AUTOSAR XML (schema 4-0-3)
package /AUTOSAR_Dem/CompuMethods
  compu method Dem_EventStatusExtendedType: 1=DEM_UDS_STATUS_TF, 2=DEM_UDS_STATUS_TFTOC, 4=DEM_UDS_STATUS_PDTC, 8=DEM_UDS_STATUS_CDTC, 16=DEM_UDS_STATUS_TNCSLC, 32=DEM_UDS_STATUS_TFSLC, 64=DEM_UDS_STATUS_TNCTOC, 128=DEM_UDS_STATUS_WIR
package /AUTOSAR_Dem/ImplementationDataTypes
  30 x impl type:
    Dem_ReturnDisableDTCRecordUpdateType: category=VALUE, base-type=uint8, compu {0x00=DEM_DISABLE_DTCRECUP_OK, 0x01=DEM_DISABLE_DTCRECUP_WRONG_DTC, 0x02=DEM_DISABLE_DTCRECUP_WRONG_DTCORIGIN, 0x03=DEM_DISABLE_DTCRECUP_PENDING}, range raw 0x00..0x03
    Dem_ReturnGetFreezeFrameDataByDTCType: category=VALUE, base-type=uint8, compu {0x00=DEM_GET_FFDATABYDTC_OK, 0x01=DEM_GET_FFDATABYDTC_WRONG_DTC, 0x02=DEM_GET_FFDATABYDTC_WRONG_DTCORIGIN, 0x03=DEM_GET_FFDATABYDTC_WRONG_RECORDNUMBER, 0x04=DEM_GET_FFDATABYDTC_WRONG_BUFFERSIZE, 0x05=DEM_GET_FFDATABYDTC_PENDING}, range raw 0x00..0x05
    Dem_ReturnGetSizeOfExtendedDataRecordByDTCType: category=VALUE, base-type=uint8, compu {0x00=DEM_GET_SIZEOFEDRBYDTC_OK, 0x01=DEM_GET_SIZEOFEDRBYDTC_W_DTC, 0x02=DEM_GET_SIZEOFEDRBYDTC_W_DTCOR, 0x03=DEM_GET_SIZEOFEDRBYDTC_W_RNUM, 0x04=DEM_GET_SIZEOFEDRBYDTC_PENDING}, range raw 0x00..0x04
    Dem_ReturnGetSeverityOfDTCType: category=VALUE, base-type=uint8, compu {0x00=DEM_GET_SEVERITYOFDTC_OK, 0x01=DEM_GET_SEVERITYOFDTC_WRONG_DTC, 0x02=DEM_GET_SEVERITYOFDTC_NOSEVERITY, 0x03=DEM_GET_SEVERITYOFDTC_PENDING}, range raw 0x00..0x03
    Dem_DTCFormatType: category=VALUE, base-type=uint8, compu {0=DEM_DTC_FORMAT_OBD, 1=DEM_DTC_FORMAT_UDS, 2=DEM_DTC_FORMAT_J1939}, range raw 0..2
    Dem_DTCKindType: category=VALUE, base-type=uint8, compu {0x01=DEM_DTC_KIND_ALL_DTCS, 0x02=DEM_DTC_KIND_EMISSION_REL_DTCS}, range raw 0x01..0x02
    Dem_DTCOriginType: category=VALUE, base-type=uint8, compu {0x01=DEM_DTC_ORIGIN_PRIMARY_MEMORY, 0x02=DEM_DTC_ORIGIN_MIRROR_MEMORY, 0x03=DEM_DTC_ORIGIN_PERMANENT_MEMORY, 0x04=DEM_DTC_ORIGIN_SECONDARY_MEMORY}, range raw 0x01..0x04
    Dem_DTCRequestType: category=VALUE, base-type=uint8, compu {0x01=DEM_FIRST_FAILED_DTC, 0x02=DEM_MOST_RECENT_FAILED_DTC, 0x03=DEM_FIRST_DET_CONFIRMED_DTC, 0x04=DEM_MOST_REC_DET_CONFIRMED_DTC, 0x04=DEM_NUM_OF_DTC_REQEST_TYPE}, range raw 0x01..0x04
    Dem_ReturnGetNumberOfFilteredDTCType: category=VALUE, base-type=uint8, compu {0x00=DEM_NUMBER_OK, 0x01=DEM_NUMBER_FAILED, 0x02=DEM_NUMBER_PENDING}, range raw 0x00..0x02
    Dem_DTCSeverityType: category=VALUE, base-type=uint8, compu {0=DEM_SEVERITY_NO_SEVERITY, 32=DEM_SEVERITY_MAINTENANCE_ONLY, 64=DEM_SEVERITY_CHECK_AT_NEXT_HALT, 128=DEM_SEVERITY_CHECK_IMMEDIATELY}, range raw 0x00..0xE0
    Dem_DTCTranslationFormatType: category=VALUE, base-type=uint8, compu {0x00=DEM_DTC_TRANSLATION_ISO15031_6, 0x01=DEM_DTC_TRANSLATION_ISO14229_1, 0x02=DEM_DTC_TRANSLATION_SAEJ1939_73, 0x03=DEM_DTC_TRANSLATION_ISO11992_4, 0x04=DEM_DTC_TRANSLATION_J2012DA_FORMAT_04}, range raw 0x00..0x04
    Dem_EventStatusType: category=VALUE, base-type=uint8, compu {0x00=DEM_EVENT_STATUS_PASSED, 0x01=DEM_EVENT_STATUS_FAILED, 0x02=DEM_EVENT_STATUS_PREPASSED, 0x03=DEM_EVENT_STATUS_PREFAILED}, range raw 0x00..0x03
    Dem_IndicatorStatusType: category=VALUE, base-type=uint8, compu {0x00=DEM_INDICATOR_OFF, 0x01=DEM_INDICATOR_CONTINUOUS, 0x02=DEM_INDICATOR_BLINKING, 0x03=DEM_INDICATOR_BLINK_CONT, 0x04=DEM_INDICATOR_SLOW_FLASH, 0x05=DEM_INDICATOR_FAST_FLASH}, range raw 0x00..0x05
    Dem_InitMonitorReasonType: category=VALUE, base-type=uint8, compu {0x01=DEM_INIT_MONITOR_CLEAR, 0x02=DEM_INIT_MONITOR_RESTART, 0x03=DEM_INIT_MONITOR_REENABLED}, range raw 0x01..0x03
    Dem_ReturnSetFilterType: category=VALUE, base-type=uint8, compu {0x00=DEM_FILTER_ACCEPTED, 0x01=DEM_WRONG_FILTER}, range raw 0x00..0x01
    Dem_OperationCycleStateType: category=VALUE, base-type=uint8, compu {0x00=DEM_CYCLE_STATE_START, 0x01=DEM_CYCLE_STATE_END}, range raw 0x00..0x01
    Dem_ReturnGetFunctionalUnitOfDTCType: category=VALUE, base-type=uint8, compu {0x00=DEM_GET_FUNCTIONALUNITOFDTC_OK, 0x01=DEM_GET_FUNCTIONALUNITOFDTC_WRONG_DTC}, range raw 0x00..0x01
    Dem_EventStatusExtendedType: category=VALUE, base-type=uint8, compu-method=Dem_EventStatusExtendedType, range raw 0x00..0xFF
    Dem_EventIdType: category=VALUE, base-type=uint16, range raw 0..65535
    DataArrayType_DE_0001: category=ARRAY
      element DataArrayType: array-size=3, array-size-semantics=FIXED-SIZE, implementation-data-type=uint8
    DataArrayType_DE_0002: category=ARRAY
      element DataArrayType: array-size=3, array-size-semantics=FIXED-SIZE, implementation-data-type=uint8
    Dem_ReturnGetStatusOfDTCType: category=VALUE, base-type=uint8, compu {0x00=DEM_STATUS_OK, 0x01=DEM_STATUS_WRONG_DTC, 0x02=DEM_STATUS_WRONG_DTCORIGIN, 0x03=DEM_STATUS_FAILED, 0x04=DEM_STATUS_PENDING}, range raw 0x00..0x04
    Dem_MaxDataValueType: category=ARRAY
      element Dem_MaxDataValueType: array-size=6, array-size-semantics=FIXED-SIZE, implementation-data-type=uint8
    Dem_ReturnGetSizeOfFreezeFrameByDTCType: category=VALUE, base-type=uint8, compu {0x00=DEM_GET_SIZEOFFF_OK, 0x01=DEM_GET_SIZEOFFF_WRONG_DTC, 0x02=DEM_GET_SIZEOFFF_WRONG_DTCOR, 0x03=DEM_GET_SIZEOFFF_WRONG_RNUM, 0x04=DEM_GET_SIZEOFFF_PENDING}, range raw 0x00..0x04
    Dem_DTCStatusMaskType: category=VALUE, base-type=uint8, compu-method=Dem_EventStatusExtendedType, range raw 0x00..0xFF
    Dem_ReturnGetNextFilteredDTCType: category=VALUE, base-type=uint8, compu {0x00=DEM_FILTERED_OK, 0x01=DEM_FILTERED_NO_MATCHING_DTC, 0x02=DEM_FILTERED_PENDING}, range raw 0x00..0x02
    Dem_ReturnClearDTCType: category=VALUE, base-type=uint8, compu {0x00=DEM_CLEAR_OK, 0x01=DEM_CLEAR_WRONG_DTC, 0x02=DEM_CLEAR_WRONG_DTCORIGIN, 0x03=DEM_CLEAR_FAILED, 0x04=DEM_CLEAR_PENDING, 0x05=DEM_CLEAR_BUSY, 0x06=DEM_CLEAR_MEMORY_ERROR}, range raw 0x00..0x06
    Dem_ReturnControlDTCSettingType: category=VALUE, base-type=uint8, compu {0x00=DEM_CONTROL_DTC_SETTING_OK, 0x01=DEM_CONTROL_DTC_SETTING_N_OK, 0x02=DEM_CONTROL_DTC_WRONG_DTCGROUP}, range raw 0x00..0x02
    Dem_ReturnGetExtendedDataRecordByDTCType: category=VALUE, base-type=uint8, compu {0x00=DEM_RECORD_OK, 0x01=DEM_RECORD_WRONG_DTC, 0x02=DEM_RECORD_WRONG_DTCORIGIN, 0x03=DEM_RECORD_WRONG_NUMBER, 0x04=DEM_RECORD_WRONG_BUFFERSIZE, 0x05=DEM_RECORD_PENDING}, range raw 0x00..0x05
    Dem_ReturnGetDTCByOccurrenceTimeType: category=VALUE, base-type=uint8, compu {0x00=DEM_OCCURR_OK, 0x01=DEM_OCCURR_NOT_AVAILABLE}, range raw 0x00..0x01
package /AUTOSAR_Dem/ClientServerInterfaces
  19 x client server interface, all with is-service=true:
    CSDataServices_DE_0001
      operation ReadData: possible-error=CSDataServices_DE_0001/E_NOT_OK
        arg Data: type=DataArrayType_DE_0001, direction=OUT
      error E_NOT_OK: error-code=1
    CSDataServices_DE_0002
      operation ReadData: possible-error=CSDataServices_DE_0002/E_NOT_OK
        arg Data: type=DataArrayType_DE_0002, direction=OUT
      error E_NOT_OK: error-code=1
    EnableCondition
      operation SetEnableCondition: possible-error=EnableCondition/E_NOT_OK
        arg ConditionFulfilled: type=boolean, direction=IN
      error E_NOT_OK: error-code=1
    DiagnosticMonitor
      operation ResetEventStatus: possible-error=DiagnosticMonitor/E_NOT_OK
      operation SetEventDisabled: possible-error=DiagnosticMonitor/E_NOT_OK
      operation SetEventStatus: possible-error=DiagnosticMonitor/E_NOT_OK
        arg EventStatus: type=Dem_EventStatusType, direction=IN
      error E_NOT_OK: error-code=1
    DiagnosticInfo
      7 x operation:
        GetDTCOfEvent: possible-error=[DiagnosticInfo/E_NOT_OK, DiagnosticInfo/DEM_E_NO_DTC_AVAILABLE]
          arg DTCFormat: type=Dem_DTCFormatType, direction=IN
          arg DTCOfEvent: type=uint32, direction=OUT
        GetEventExtendedDataRecord: possible-error=[DiagnosticInfo/DEM_E_NODATAAVAILABLE, DiagnosticInfo/DEM_E_WRONG_RECORDNUMBER]
          arg RecordNumber: type=uint8, direction=IN
          arg DestBuffer: type=Dem_MaxDataValueType, direction=OUT
        GetEventFailed: possible-error=DiagnosticInfo/E_NOT_OK
          arg EventFailed: type=boolean, direction=OUT
        GetEventFreezeFrameData: possible-error=[DiagnosticInfo/DEM_E_NODATAAVAILABLE, DiagnosticInfo/DEM_E_WRONG_RECORDNUMBER, DiagnosticInfo/DEM_E_WRONG_DIDNUMBER]
          4 x arg:
            RecordNumber: type=uint8, direction=IN
            ReportTotalRecord: type=boolean, direction=IN
            DataId: type=uint16, direction=IN
            DestBuffer: type=Dem_MaxDataValueType, direction=OUT
        GetEventStatus: possible-error=DiagnosticInfo/E_NOT_OK
          arg EventStatusExtended: type=Dem_EventStatusExtendedType, direction=OUT
        GetEventTested: possible-error=DiagnosticInfo/E_NOT_OK
          arg EventTested: type=boolean, direction=OUT
        GetFaultDetectionCounter: possible-error=[DiagnosticInfo/E_NOT_OK, DiagnosticInfo/DEM_E_NO_FDC_AVAILABLE]
          arg FaultDetectionCounter: type=sint8, direction=OUT
      6 x error:
        E_NOT_OK: error-code=1
        DEM_E_NO_DTC_AVAILABLE: error-code=2
        DEM_E_NO_FDC_AVAILABLE: error-code=3
        DEM_E_NODATAAVAILABLE: error-code=48
        DEM_E_WRONG_RECORDNUMBER: error-code=49
        DEM_E_WRONG_DIDNUMBER: error-code=50
    CallbackClearEventAllowed
      operation ClearEventAllowed: possible-error=CallbackClearEventAllowed/E_NOT_OK
        arg Allowed: type=boolean, direction=OUT
      error E_NOT_OK: error-code=1
    GeneralCallbackEventDataChanged
      operation EventDataChanged: possible-error=GeneralCallbackEventDataChanged/E_NOT_OK
        arg EventId: type=Dem_EventIdType, direction=IN
      error E_NOT_OK: error-code=1
    GeneralCallbackEventStatusChange
      operation EventStatusChanged: possible-error=GeneralCallbackEventStatusChange/E_NOT_OK
        arg EventId: type=Dem_EventIdType, direction=IN
        arg EventStatusOld: type=Dem_EventStatusExtendedType, direction=IN
        arg EventStatusNew: type=Dem_EventStatusExtendedType, direction=IN
      error E_NOT_OK: error-code=1
    GeneralDiagnosticInfo
      7 x operation:
        GetDTCOfEvent: possible-error=[GeneralDiagnosticInfo/E_NOT_OK, GeneralDiagnosticInfo/DEM_E_NO_DTC_AVAILABLE]
          arg EventId: type=Dem_EventIdType, direction=IN
          arg DTCFormat: type=Dem_DTCFormatType, direction=IN
          arg DTCOfEvent: type=uint32, direction=OUT
        GetEventExtendedDataRecord: possible-error=[GeneralDiagnosticInfo/DEM_E_NODATAAVAILABLE, GeneralDiagnosticInfo/DEM_E_WRONG_RECORDNUMBER]
          arg EventId: type=Dem_EventIdType, direction=IN
          arg RecordNumber: type=uint8, direction=IN
          arg DestBuffer: type=Dem_MaxDataValueType, direction=OUT
        GetEventFailed: possible-error=GeneralDiagnosticInfo/E_NOT_OK
          arg EventId: type=Dem_EventIdType, direction=IN
          arg EventFailed: type=boolean, direction=OUT
        GetEventFreezeFrameData: possible-error=[GeneralDiagnosticInfo/DEM_E_NODATAAVAILABLE, GeneralDiagnosticInfo/DEM_E_WRONG_RECORDNUMBER, GeneralDiagnosticInfo/DEM_E_WRONG_DIDNUMBER]
          5 x arg:
            EventId: type=Dem_EventIdType, direction=IN
            RecordNumber: type=uint8, direction=IN
            ReportTotalRecord: type=boolean, direction=IN
            DataId: type=uint16, direction=IN
            DestBuffer: type=Dem_MaxDataValueType, direction=OUT
        GetEventStatus: possible-error=GeneralDiagnosticInfo/E_NOT_OK
          arg EventId: type=Dem_EventIdType, direction=IN
          arg EventStatusExtended: type=Dem_EventStatusExtendedType, direction=OUT
        GetEventTested: possible-error=GeneralDiagnosticInfo/E_NOT_OK
          arg EventId: type=Dem_EventIdType, direction=IN
          arg EventTested: type=boolean, direction=OUT
        GetFaultDetectionCounter: possible-error=[GeneralDiagnosticInfo/E_NOT_OK, GeneralDiagnosticInfo/DEM_E_NO_FDC_AVAILABLE]
          arg EventId: type=Dem_EventIdType, direction=IN
          arg FaultDetectionCounter: type=sint8, direction=OUT
      6 x error:
        E_NOT_OK: error-code=1
        DEM_E_NO_DTC_AVAILABLE: error-code=2
        DEM_E_NO_FDC_AVAILABLE: error-code=3
        DEM_E_NODATAAVAILABLE: error-code=48
        DEM_E_WRONG_RECORDNUMBER: error-code=49
        DEM_E_WRONG_DIDNUMBER: error-code=50
    IndicatorStatus
      operation GetIndicatorStatus: possible-error=IndicatorStatus/E_NOT_OK
        arg IndicatorStatus: type=Dem_IndicatorStatusType, direction=OUT
      error E_NOT_OK: error-code=1
    OperationCycle
      operation SetOperationCycleState: possible-error=OperationCycle/E_NOT_OK
        arg CycleState: type=Dem_OperationCycleStateType, direction=IN
      error E_NOT_OK: error-code=1
    EvMemOverflowIndication
      operation GetEventMemoryOverflow: possible-error=EvMemOverflowIndication/E_NOT_OK
        arg OverflowIndication: type=boolean, direction=OUT
      error E_NOT_OK: error-code=1
    CallbackEventDataChanged
      operation EventDataChanged: possible-error=CallbackEventDataChanged/E_NOT_OK
      error E_NOT_OK: error-code=1
    StorageCondition
      operation SetStorageCondition: possible-error=StorageCondition/E_NOT_OK
        arg ConditionFulfilled: type=boolean, direction=IN
      error E_NOT_OK: error-code=1
    CallbackGetFaultDetectCounter
      operation GetFaultDetectionCounter: possible-error=CallbackGetFaultDetectCounter/E_NOT_OK
        arg FaultDetectionCounter: type=sint8, direction=OUT
      error E_NOT_OK: error-code=1
    CallbackInitMonitorForEvent
      operation InitMonitorForEvent: possible-error=CallbackInitMonitorForEvent/E_NOT_OK
        arg InitMonitorReason: type=Dem_InitMonitorReasonType, direction=IN
      error E_NOT_OK: error-code=1
    CallbackDTCStatusChange
      operation DTCStatusChanged: possible-error=CallbackDTCStatusChange/E_NOT_OK
        arg DTC: type=uint32, direction=IN
        arg DTCStatusOld: type=Dem_DTCStatusMaskType, direction=IN
        arg DTCStatusNew: type=Dem_DTCStatusMaskType, direction=IN
      error E_NOT_OK: error-code=1
    CallbackEventStatusChange
      operation EventStatusChanged: possible-error=CallbackEventStatusChange/E_NOT_OK
        arg EventStatusOld: type=Dem_EventStatusExtendedType, direction=IN
        arg EventStatusNew: type=Dem_EventStatusExtendedType, direction=IN
      error E_NOT_OK: error-code=1
    CddIf
      operation ClearDTC: possible-error=[DEM_CLEAR_WRONG_DTC, DEM_CLEAR_WRONG_DTCORIGIN, DEM_CLEAR_FAILED, DEM_CLEAR_PENDING, DEM_CLEAR_BUSY]
        arg DTC: type=uint32, direction=IN
        arg DTCFormat: type=Dem_DTCFormatType, direction=IN
        arg DTCOrigin: type=Dem_DTCOriginType, direction=IN
      5 x error:
        DEM_CLEAR_WRONG_DTC: error-code=1
        DEM_CLEAR_WRONG_DTCORIGIN: error-code=2
        DEM_CLEAR_FAILED: error-code=3
        DEM_CLEAR_PENDING: error-code=4
        DEM_CLEAR_BUSY: error-code=5
package /AUTOSAR_Dem/ServiceSwComponentTypes
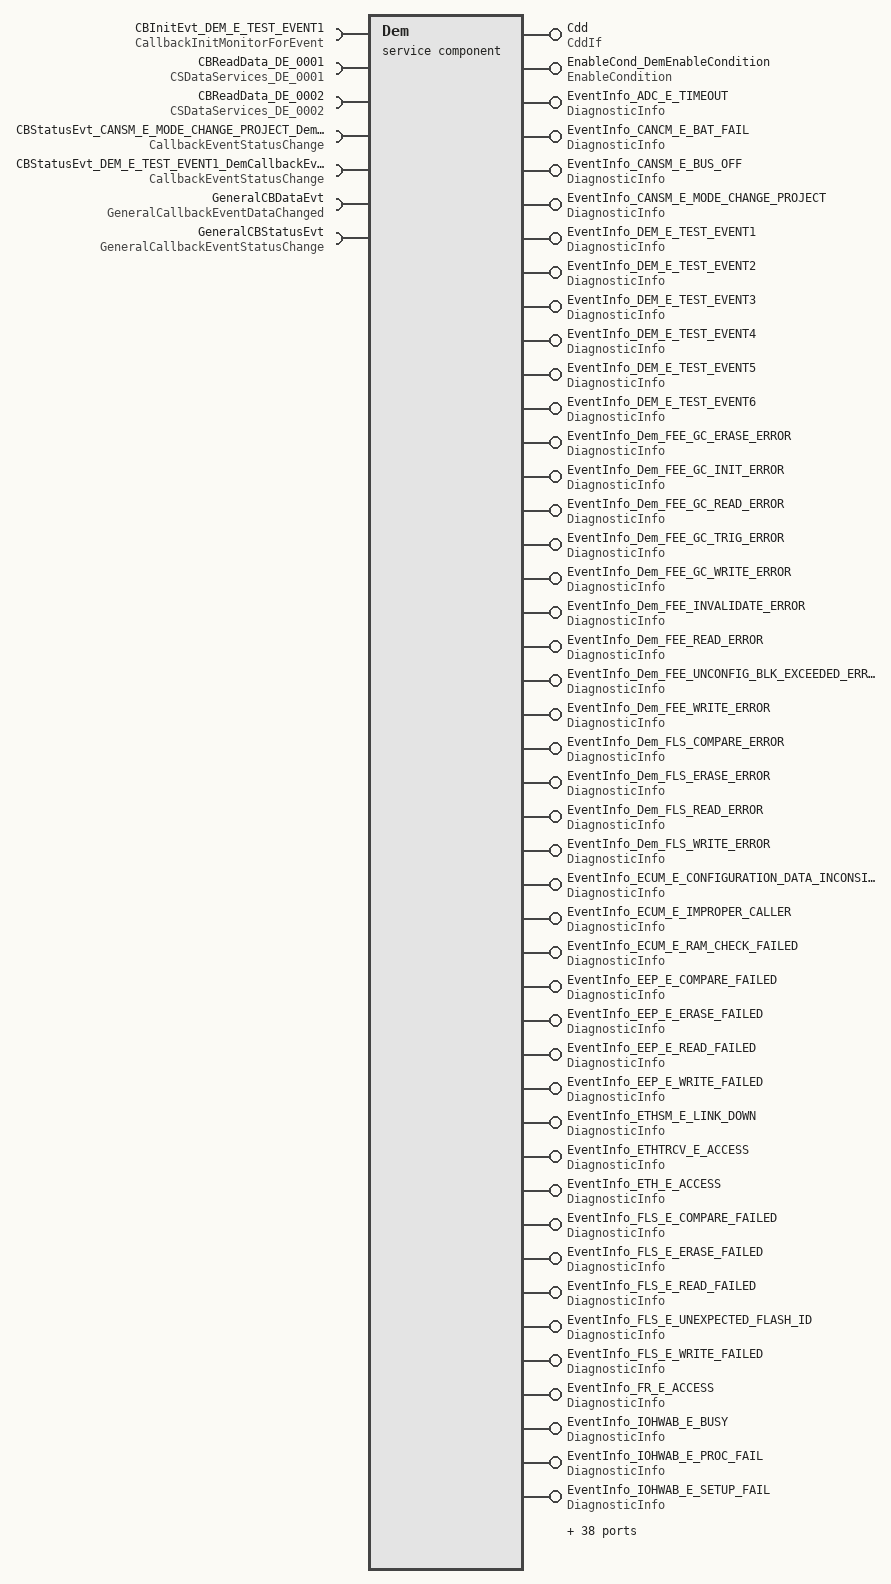
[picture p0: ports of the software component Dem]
  service sw component type Dem
    5 x require port:
      CBInitEvt_DEM_E_TEST_EVENT1: client-com-spec=InitMonitorForEvent, required-interface=CallbackInitMonitorForEvent
      CBReadData_DE_0001: client-com-spec=CSDataServices_DE_0001/ReadData, required-interface=CSDataServices_DE_0001
      CBReadData_DE_0002: client-com-spec=CSDataServices_DE_0002/ReadData, required-interface=CSDataServices_DE_0002
      CBStatusEvt_CANSM_E_MODE_CHANGE_PROJECT_DemCallbackEventStatusChanged0: client-com-spec=CallbackEventStatusChange/EventStatusChanged, required-interface=CallbackEventStatusChange
      CBStatusEvt_DEM_E_TEST_EVENT1_DemCallbackEventStatusChanged0: client-com-spec=CallbackEventStatusChange/EventStatusChanged, required-interface=CallbackEventStatusChange
    77 x provide port:
      Cdd: server-com-spec{operation=ClearDTC, queue-length=1}, provided-interface=CddIf
      EnableCond_DemEnableCondition: server-com-spec{operation=SetEnableCondition, queue-length=1}, provided-interface=EnableCondition
      EventInfo_ADC_E_TIMEOUT: provided-interface=DiagnosticInfo
        provided-com-specs:
          operation=DiagnosticInfo/GetDTCOfEvent, queue-length=1
          operation=DiagnosticInfo/GetEventExtendedDataRecord, queue-length=1
          operation=DiagnosticInfo/GetEventFailed, queue-length=1
          operation=DiagnosticInfo/GetEventFreezeFrameData, queue-length=1
          operation=DiagnosticInfo/GetEventStatus, queue-length=1
          operation=DiagnosticInfo/GetEventTested, queue-length=1
          operation=DiagnosticInfo/GetFaultDetectionCounter, queue-length=1
      EventInfo_CANCM_E_BAT_FAIL: provided-interface=DiagnosticInfo
        provided-com-specs:
          operation=DiagnosticInfo/GetDTCOfEvent, queue-length=1
          operation=DiagnosticInfo/GetEventExtendedDataRecord, queue-length=1
          operation=DiagnosticInfo/GetEventFailed, queue-length=1
          operation=DiagnosticInfo/GetEventFreezeFrameData, queue-length=1
          operation=DiagnosticInfo/GetEventStatus, queue-length=1
          operation=DiagnosticInfo/GetEventTested, queue-length=1
          operation=DiagnosticInfo/GetFaultDetectionCounter, queue-length=1
      EventInfo_CANSM_E_BUS_OFF: provided-interface=DiagnosticInfo
        provided-com-specs:
          operation=DiagnosticInfo/GetDTCOfEvent, queue-length=1
          operation=DiagnosticInfo/GetEventExtendedDataRecord, queue-length=1
          operation=DiagnosticInfo/GetEventFailed, queue-length=1
          operation=DiagnosticInfo/GetEventFreezeFrameData, queue-length=1
          operation=DiagnosticInfo/GetEventStatus, queue-length=1
          operation=DiagnosticInfo/GetEventTested, queue-length=1
          operation=DiagnosticInfo/GetFaultDetectionCounter, queue-length=1
      EventInfo_CANSM_E_MODE_CHANGE_PROJECT: provided-interface=DiagnosticInfo
        provided-com-specs:
          operation=DiagnosticInfo/GetDTCOfEvent, queue-length=1
          operation=DiagnosticInfo/GetEventExtendedDataRecord, queue-length=1
          operation=DiagnosticInfo/GetEventFailed, queue-length=1
          operation=DiagnosticInfo/GetEventFreezeFrameData, queue-length=1
          operation=DiagnosticInfo/GetEventStatus, queue-length=1
          operation=DiagnosticInfo/GetEventTested, queue-length=1
          operation=DiagnosticInfo/GetFaultDetectionCounter, queue-length=1
      EventInfo_DEM_E_TEST_EVENT1: provided-interface=DiagnosticInfo
        provided-com-specs:
          operation=DiagnosticInfo/GetDTCOfEvent, queue-length=1
          operation=DiagnosticInfo/GetEventExtendedDataRecord, queue-length=1
          operation=DiagnosticInfo/GetEventFailed, queue-length=1
          operation=DiagnosticInfo/GetEventFreezeFrameData, queue-length=1
          operation=DiagnosticInfo/GetEventStatus, queue-length=1
          operation=DiagnosticInfo/GetEventTested, queue-length=1
          operation=DiagnosticInfo/GetFaultDetectionCounter, queue-length=1
      EventInfo_DEM_E_TEST_EVENT2: provided-interface=DiagnosticInfo
        provided-com-specs:
          operation=DiagnosticInfo/GetDTCOfEvent, queue-length=1
          operation=DiagnosticInfo/GetEventExtendedDataRecord, queue-length=1
          operation=DiagnosticInfo/GetEventFailed, queue-length=1
          operation=DiagnosticInfo/GetEventFreezeFrameData, queue-length=1
          operation=DiagnosticInfo/GetEventStatus, queue-length=1
          operation=DiagnosticInfo/GetEventTested, queue-length=1
          operation=DiagnosticInfo/GetFaultDetectionCounter, queue-length=1
      EventInfo_DEM_E_TEST_EVENT3: provided-interface=DiagnosticInfo
        provided-com-specs:
          operation=DiagnosticInfo/GetDTCOfEvent, queue-length=1
          operation=DiagnosticInfo/GetEventExtendedDataRecord, queue-length=1
          operation=DiagnosticInfo/GetEventFailed, queue-length=1
          operation=DiagnosticInfo/GetEventFreezeFrameData, queue-length=1
          operation=DiagnosticInfo/GetEventStatus, queue-length=1
          operation=DiagnosticInfo/GetEventTested, queue-length=1
          operation=DiagnosticInfo/GetFaultDetectionCounter, queue-length=1
      EventInfo_DEM_E_TEST_EVENT4: provided-interface=DiagnosticInfo
        provided-com-specs:
          operation=DiagnosticInfo/GetDTCOfEvent, queue-length=1
          operation=DiagnosticInfo/GetEventExtendedDataRecord, queue-length=1
          operation=DiagnosticInfo/GetEventFailed, queue-length=1
          operation=DiagnosticInfo/GetEventFreezeFrameData, queue-length=1
          operation=DiagnosticInfo/GetEventStatus, queue-length=1
          operation=DiagnosticInfo/GetEventTested, queue-length=1
          operation=DiagnosticInfo/GetFaultDetectionCounter, queue-length=1
      EventInfo_DEM_E_TEST_EVENT5: provided-interface=DiagnosticInfo
        provided-com-specs:
          operation=DiagnosticInfo/GetDTCOfEvent, queue-length=1
          operation=DiagnosticInfo/GetEventExtendedDataRecord, queue-length=1
          operation=DiagnosticInfo/GetEventFailed, queue-length=1
          operation=DiagnosticInfo/GetEventFreezeFrameData, queue-length=1
          operation=DiagnosticInfo/GetEventStatus, queue-length=1
          operation=DiagnosticInfo/GetEventTested, queue-length=1
          operation=DiagnosticInfo/GetFaultDetectionCounter, queue-length=1
      EventInfo_DEM_E_TEST_EVENT6: provided-interface=DiagnosticInfo
        provided-com-specs:
          operation=DiagnosticInfo/GetDTCOfEvent, queue-length=1
          operation=DiagnosticInfo/GetEventExtendedDataRecord, queue-length=1
          operation=DiagnosticInfo/GetEventFailed, queue-length=1
          operation=DiagnosticInfo/GetEventFreezeFrameData, queue-length=1
          operation=DiagnosticInfo/GetEventStatus, queue-length=1
          operation=DiagnosticInfo/GetEventTested, queue-length=1
          operation=DiagnosticInfo/GetFaultDetectionCounter, queue-length=1
      EventInfo_Dem_FEE_GC_ERASE_ERROR: provided-interface=DiagnosticInfo
        provided-com-specs:
          operation=DiagnosticInfo/GetDTCOfEvent, queue-length=1
          operation=DiagnosticInfo/GetEventExtendedDataRecord, queue-length=1
          operation=DiagnosticInfo/GetEventFailed, queue-length=1
          operation=DiagnosticInfo/GetEventFreezeFrameData, queue-length=1
          operation=DiagnosticInfo/GetEventStatus, queue-length=1
          operation=DiagnosticInfo/GetEventTested, queue-length=1
          operation=DiagnosticInfo/GetFaultDetectionCounter, queue-length=1
      EventInfo_Dem_FEE_GC_INIT_ERROR: provided-interface=DiagnosticInfo
        provided-com-specs:
          operation=DiagnosticInfo/GetDTCOfEvent, queue-length=1
          operation=DiagnosticInfo/GetEventExtendedDataRecord, queue-length=1
          operation=DiagnosticInfo/GetEventFailed, queue-length=1
          operation=DiagnosticInfo/GetEventFreezeFrameData, queue-length=1
          operation=DiagnosticInfo/GetEventStatus, queue-length=1
          operation=DiagnosticInfo/GetEventTested, queue-length=1
          operation=DiagnosticInfo/GetFaultDetectionCounter, queue-length=1
      EventInfo_Dem_FEE_GC_READ_ERROR: provided-interface=DiagnosticInfo
        provided-com-specs:
          operation=DiagnosticInfo/GetDTCOfEvent, queue-length=1
          operation=DiagnosticInfo/GetEventExtendedDataRecord, queue-length=1
          operation=DiagnosticInfo/GetEventFailed, queue-length=1
          operation=DiagnosticInfo/GetEventFreezeFrameData, queue-length=1
          operation=DiagnosticInfo/GetEventStatus, queue-length=1
          operation=DiagnosticInfo/GetEventTested, queue-length=1
          operation=DiagnosticInfo/GetFaultDetectionCounter, queue-length=1
      EventInfo_Dem_FEE_GC_TRIG_ERROR: provided-interface=DiagnosticInfo
        provided-com-specs:
          operation=DiagnosticInfo/GetDTCOfEvent, queue-length=1
          operation=DiagnosticInfo/GetEventExtendedDataRecord, queue-length=1
          operation=DiagnosticInfo/GetEventFailed, queue-length=1
          operation=DiagnosticInfo/GetEventFreezeFrameData, queue-length=1
          operation=DiagnosticInfo/GetEventStatus, queue-length=1
          operation=DiagnosticInfo/GetEventTested, queue-length=1
          operation=DiagnosticInfo/GetFaultDetectionCounter, queue-length=1
      EventInfo_Dem_FEE_GC_WRITE_ERROR: provided-interface=DiagnosticInfo
        provided-com-specs:
          operation=DiagnosticInfo/GetDTCOfEvent, queue-length=1
          operation=DiagnosticInfo/GetEventExtendedDataRecord, queue-length=1
          operation=DiagnosticInfo/GetEventFailed, queue-length=1
          operation=DiagnosticInfo/GetEventFreezeFrameData, queue-length=1
          operation=DiagnosticInfo/GetEventStatus, queue-length=1
          operation=DiagnosticInfo/GetEventTested, queue-length=1
          operation=DiagnosticInfo/GetFaultDetectionCounter, queue-length=1
      EventInfo_Dem_FEE_INVALIDATE_ERROR: provided-interface=DiagnosticInfo
        provided-com-specs:
          operation=DiagnosticInfo/GetDTCOfEvent, queue-length=1
          operation=DiagnosticInfo/GetEventExtendedDataRecord, queue-length=1
          operation=DiagnosticInfo/GetEventFailed, queue-length=1
          operation=DiagnosticInfo/GetEventFreezeFrameData, queue-length=1
          operation=DiagnosticInfo/GetEventStatus, queue-length=1
          operation=DiagnosticInfo/GetEventTested, queue-length=1
          operation=DiagnosticInfo/GetFaultDetectionCounter, queue-length=1
      EventInfo_Dem_FEE_READ_ERROR: provided-interface=DiagnosticInfo
        provided-com-specs:
          operation=DiagnosticInfo/GetDTCOfEvent, queue-length=1
          operation=DiagnosticInfo/GetEventExtendedDataRecord, queue-length=1
          operation=DiagnosticInfo/GetEventFailed, queue-length=1
          operation=DiagnosticInfo/GetEventFreezeFrameData, queue-length=1
          operation=DiagnosticInfo/GetEventStatus, queue-length=1
          operation=DiagnosticInfo/GetEventTested, queue-length=1
          operation=DiagnosticInfo/GetFaultDetectionCounter, queue-length=1
      EventInfo_Dem_FEE_UNCONFIG_BLK_EXCEEDED_ERROR: provided-interface=DiagnosticInfo
        provided-com-specs:
          operation=DiagnosticInfo/GetDTCOfEvent, queue-length=1
          operation=DiagnosticInfo/GetEventExtendedDataRecord, queue-length=1
          operation=DiagnosticInfo/GetEventFailed, queue-length=1
          operation=DiagnosticInfo/GetEventFreezeFrameData, queue-length=1
          operation=DiagnosticInfo/GetEventStatus, queue-length=1
          operation=DiagnosticInfo/GetEventTested, queue-length=1
          operation=DiagnosticInfo/GetFaultDetectionCounter, queue-length=1
      EventInfo_Dem_FEE_WRITE_ERROR: provided-interface=DiagnosticInfo
        provided-com-specs:
          operation=DiagnosticInfo/GetDTCOfEvent, queue-length=1
          operation=DiagnosticInfo/GetEventExtendedDataRecord, queue-length=1
          operation=DiagnosticInfo/GetEventFailed, queue-length=1
          operation=DiagnosticInfo/GetEventFreezeFrameData, queue-length=1
          operation=DiagnosticInfo/GetEventStatus, queue-length=1
          operation=DiagnosticInfo/GetEventTested, queue-length=1
          operation=DiagnosticInfo/GetFaultDetectionCounter, queue-length=1
      EventInfo_Dem_FLS_COMPARE_ERROR: provided-interface=DiagnosticInfo
        provided-com-specs:
          operation=DiagnosticInfo/GetDTCOfEvent, queue-length=1
          operation=DiagnosticInfo/GetEventExtendedDataRecord, queue-length=1
          operation=DiagnosticInfo/GetEventFailed, queue-length=1
          operation=DiagnosticInfo/GetEventFreezeFrameData, queue-length=1
          operation=DiagnosticInfo/GetEventStatus, queue-length=1
          operation=DiagnosticInfo/GetEventTested, queue-length=1
          operation=DiagnosticInfo/GetFaultDetectionCounter, queue-length=1
      EventInfo_Dem_FLS_ERASE_ERROR: provided-interface=DiagnosticInfo
        provided-com-specs:
          operation=DiagnosticInfo/GetDTCOfEvent, queue-length=1
          operation=DiagnosticInfo/GetEventExtendedDataRecord, queue-length=1
          operation=DiagnosticInfo/GetEventFailed, queue-length=1
          operation=DiagnosticInfo/GetEventFreezeFrameData, queue-length=1
          operation=DiagnosticInfo/GetEventStatus, queue-length=1
          operation=DiagnosticInfo/GetEventTested, queue-length=1
          operation=DiagnosticInfo/GetFaultDetectionCounter, queue-length=1
      EventInfo_Dem_FLS_READ_ERROR: provided-interface=DiagnosticInfo
        provided-com-specs:
          operation=DiagnosticInfo/GetDTCOfEvent, queue-length=1
          operation=DiagnosticInfo/GetEventExtendedDataRecord, queue-length=1
          operation=DiagnosticInfo/GetEventFailed, queue-length=1
          operation=DiagnosticInfo/GetEventFreezeFrameData, queue-length=1
          operation=DiagnosticInfo/GetEventStatus, queue-length=1
          operation=DiagnosticInfo/GetEventTested, queue-length=1
          operation=DiagnosticInfo/GetFaultDetectionCounter, queue-length=1
      EventInfo_Dem_FLS_WRITE_ERROR: provided-interface=DiagnosticInfo
        provided-com-specs:
          operation=DiagnosticInfo/GetDTCOfEvent, queue-length=1
          operation=DiagnosticInfo/GetEventExtendedDataRecord, queue-length=1
          operation=DiagnosticInfo/GetEventFailed, queue-length=1
          operation=DiagnosticInfo/GetEventFreezeFrameData, queue-length=1
          operation=DiagnosticInfo/GetEventStatus, queue-length=1
          operation=DiagnosticInfo/GetEventTested, queue-length=1
          operation=DiagnosticInfo/GetFaultDetectionCounter, queue-length=1
      EventInfo_ECUM_E_CONFIGURATION_DATA_INCONSISTENT: provided-interface=DiagnosticInfo
        provided-com-specs:
          operation=DiagnosticInfo/GetDTCOfEvent, queue-length=1
          operation=DiagnosticInfo/GetEventExtendedDataRecord, queue-length=1
          operation=DiagnosticInfo/GetEventFailed, queue-length=1
          operation=DiagnosticInfo/GetEventFreezeFrameData, queue-length=1
          operation=DiagnosticInfo/GetEventStatus, queue-length=1
          operation=DiagnosticInfo/GetEventTested, queue-length=1
          operation=DiagnosticInfo/GetFaultDetectionCounter, queue-length=1
      EventInfo_ECUM_E_IMPROPER_CALLER: provided-interface=DiagnosticInfo
        provided-com-specs:
          operation=DiagnosticInfo/GetDTCOfEvent, queue-length=1
          operation=DiagnosticInfo/GetEventExtendedDataRecord, queue-length=1
          operation=DiagnosticInfo/GetEventFailed, queue-length=1
          operation=DiagnosticInfo/GetEventFreezeFrameData, queue-length=1
          operation=DiagnosticInfo/GetEventStatus, queue-length=1
          operation=DiagnosticInfo/GetEventTested, queue-length=1
          operation=DiagnosticInfo/GetFaultDetectionCounter, queue-length=1
      EventInfo_ECUM_E_RAM_CHECK_FAILED: provided-interface=DiagnosticInfo
        provided-com-specs:
          operation=DiagnosticInfo/GetDTCOfEvent, queue-length=1
          operation=DiagnosticInfo/GetEventExtendedDataRecord, queue-length=1
          operation=DiagnosticInfo/GetEventFailed, queue-length=1
          operation=DiagnosticInfo/GetEventFreezeFrameData, queue-length=1
          operation=DiagnosticInfo/GetEventStatus, queue-length=1
          operation=DiagnosticInfo/GetEventTested, queue-length=1
          operation=DiagnosticInfo/GetFaultDetectionCounter, queue-length=1
      EventInfo_EEP_E_COMPARE_FAILED: provided-interface=DiagnosticInfo
        provided-com-specs:
          operation=DiagnosticInfo/GetDTCOfEvent, queue-length=1
          operation=DiagnosticInfo/GetEventExtendedDataRecord, queue-length=1
          operation=DiagnosticInfo/GetEventFailed, queue-length=1
          operation=DiagnosticInfo/GetEventFreezeFrameData, queue-length=1
          operation=DiagnosticInfo/GetEventStatus, queue-length=1
          operation=DiagnosticInfo/GetEventTested, queue-length=1
          operation=DiagnosticInfo/GetFaultDetectionCounter, queue-length=1
      EventInfo_EEP_E_ERASE_FAILED: provided-interface=DiagnosticInfo
        provided-com-specs:
          operation=DiagnosticInfo/GetDTCOfEvent, queue-length=1
          operation=DiagnosticInfo/GetEventExtendedDataRecord, queue-length=1
          operation=DiagnosticInfo/GetEventFailed, queue-length=1
          operation=DiagnosticInfo/GetEventFreezeFrameData, queue-length=1
          operation=DiagnosticInfo/GetEventStatus, queue-length=1
          operation=DiagnosticInfo/GetEventTested, queue-length=1
          operation=DiagnosticInfo/GetFaultDetectionCounter, queue-length=1
      EventInfo_EEP_E_READ_FAILED: provided-interface=DiagnosticInfo
        provided-com-specs:
          operation=DiagnosticInfo/GetDTCOfEvent, queue-length=1
          operation=DiagnosticInfo/GetEventExtendedDataRecord, queue-length=1
          operation=DiagnosticInfo/GetEventFailed, queue-length=1
          operation=DiagnosticInfo/GetEventFreezeFrameData, queue-length=1
          operation=DiagnosticInfo/GetEventStatus, queue-length=1
          operation=DiagnosticInfo/GetEventTested, queue-length=1
          operation=DiagnosticInfo/GetFaultDetectionCounter, queue-length=1
      EventInfo_EEP_E_WRITE_FAILED: provided-interface=DiagnosticInfo
        provided-com-specs:
          operation=DiagnosticInfo/GetDTCOfEvent, queue-length=1
          operation=DiagnosticInfo/GetEventExtendedDataRecord, queue-length=1
          operation=DiagnosticInfo/GetEventFailed, queue-length=1
          operation=DiagnosticInfo/GetEventFreezeFrameData, queue-length=1
          operation=DiagnosticInfo/GetEventStatus, queue-length=1
          operation=DiagnosticInfo/GetEventTested, queue-length=1
          operation=DiagnosticInfo/GetFaultDetectionCounter, queue-length=1
      EventInfo_ETHSM_E_LINK_DOWN: provided-interface=DiagnosticInfo
        provided-com-specs:
          operation=DiagnosticInfo/GetDTCOfEvent, queue-length=1
          operation=DiagnosticInfo/GetEventExtendedDataRecord, queue-length=1
          operation=DiagnosticInfo/GetEventFailed, queue-length=1
          operation=DiagnosticInfo/GetEventFreezeFrameData, queue-length=1
          operation=DiagnosticInfo/GetEventStatus, queue-length=1
          operation=DiagnosticInfo/GetEventTested, queue-length=1
          operation=DiagnosticInfo/GetFaultDetectionCounter, queue-length=1
      EventInfo_ETHTRCV_E_ACCESS: provided-interface=DiagnosticInfo
        provided-com-specs:
          operation=DiagnosticInfo/GetDTCOfEvent, queue-length=1
          operation=DiagnosticInfo/GetEventExtendedDataRecord, queue-length=1
          operation=DiagnosticInfo/GetEventFailed, queue-length=1
          operation=DiagnosticInfo/GetEventFreezeFrameData, queue-length=1
          operation=DiagnosticInfo/GetEventStatus, queue-length=1
          operation=DiagnosticInfo/GetEventTested, queue-length=1
          operation=DiagnosticInfo/GetFaultDetectionCounter, queue-length=1
      EventInfo_ETH_E_ACCESS: provided-interface=DiagnosticInfo
        provided-com-specs:
          operation=DiagnosticInfo/GetDTCOfEvent, queue-length=1
          operation=DiagnosticInfo/GetEventExtendedDataRecord, queue-length=1
          operation=DiagnosticInfo/GetEventFailed, queue-length=1
          operation=DiagnosticInfo/GetEventFreezeFrameData, queue-length=1
          operation=DiagnosticInfo/GetEventStatus, queue-length=1
          operation=DiagnosticInfo/GetEventTested, queue-length=1
          operation=DiagnosticInfo/GetFaultDetectionCounter, queue-length=1
      EventInfo_FLS_E_COMPARE_FAILED: provided-interface=DiagnosticInfo
        provided-com-specs:
          operation=DiagnosticInfo/GetDTCOfEvent, queue-length=1
          operation=DiagnosticInfo/GetEventExtendedDataRecord, queue-length=1
          operation=DiagnosticInfo/GetEventFailed, queue-length=1
          operation=DiagnosticInfo/GetEventFreezeFrameData, queue-length=1
          operation=DiagnosticInfo/GetEventStatus, queue-length=1
          operation=DiagnosticInfo/GetEventTested, queue-length=1
          operation=DiagnosticInfo/GetFaultDetectionCounter, queue-length=1
      EventInfo_FLS_E_ERASE_FAILED: provided-interface=DiagnosticInfo
        provided-com-specs:
          operation=DiagnosticInfo/GetDTCOfEvent, queue-length=1
          operation=DiagnosticInfo/GetEventExtendedDataRecord, queue-length=1
          operation=DiagnosticInfo/GetEventFailed, queue-length=1
          operation=DiagnosticInfo/GetEventFreezeFrameData, queue-length=1
          operation=DiagnosticInfo/GetEventStatus, queue-length=1
          operation=DiagnosticInfo/GetEventTested, queue-length=1
          operation=DiagnosticInfo/GetFaultDetectionCounter, queue-length=1
      EventInfo_FLS_E_READ_FAILED: provided-interface=DiagnosticInfo
        provided-com-specs:
          operation=DiagnosticInfo/GetDTCOfEvent, queue-length=1
          operation=DiagnosticInfo/GetEventExtendedDataRecord, queue-length=1
          operation=DiagnosticInfo/GetEventFailed, queue-length=1
          operation=DiagnosticInfo/GetEventFreezeFrameData, queue-length=1
          operation=DiagnosticInfo/GetEventStatus, queue-length=1
          operation=DiagnosticInfo/GetEventTested, queue-length=1
          operation=DiagnosticInfo/GetFaultDetectionCounter, queue-length=1
      EventInfo_FLS_E_UNEXPECTED_FLASH_ID: provided-interface=DiagnosticInfo
        provided-com-specs:
          operation=DiagnosticInfo/GetDTCOfEvent, queue-length=1
          operation=DiagnosticInfo/GetEventExtendedDataRecord, queue-length=1
          operation=DiagnosticInfo/GetEventFailed, queue-length=1
          operation=DiagnosticInfo/GetEventFreezeFrameData, queue-length=1
          operation=DiagnosticInfo/GetEventStatus, queue-length=1
          operation=DiagnosticInfo/GetEventTested, queue-length=1
          operation=DiagnosticInfo/GetFaultDetectionCounter, queue-length=1
      EventInfo_FLS_E_WRITE_FAILED: provided-interface=DiagnosticInfo
        provided-com-specs:
          operation=DiagnosticInfo/GetDTCOfEvent, queue-length=1
          operation=DiagnosticInfo/GetEventExtendedDataRecord, queue-length=1
          operation=DiagnosticInfo/GetEventFailed, queue-length=1
          operation=DiagnosticInfo/GetEventFreezeFrameData, queue-length=1
          operation=DiagnosticInfo/GetEventStatus, queue-length=1
          operation=DiagnosticInfo/GetEventTested, queue-length=1
          operation=DiagnosticInfo/GetFaultDetectionCounter, queue-length=1
      EventInfo_FR_E_ACCESS: provided-interface=DiagnosticInfo
        provided-com-specs:
          operation=DiagnosticInfo/GetDTCOfEvent, queue-length=1
          operation=DiagnosticInfo/GetEventExtendedDataRecord, queue-length=1
          operation=DiagnosticInfo/GetEventFailed, queue-length=1
          operation=DiagnosticInfo/GetEventFreezeFrameData, queue-length=1
          operation=DiagnosticInfo/GetEventStatus, queue-length=1
          operation=DiagnosticInfo/GetEventTested, queue-length=1
          operation=DiagnosticInfo/GetFaultDetectionCounter, queue-length=1
      EventInfo_IOHWAB_E_BUSY: provided-interface=DiagnosticInfo
        provided-com-specs:
          operation=DiagnosticInfo/GetDTCOfEvent, queue-length=1
          operation=DiagnosticInfo/GetEventExtendedDataRecord, queue-length=1
          operation=DiagnosticInfo/GetEventFailed, queue-length=1
          operation=DiagnosticInfo/GetEventFreezeFrameData, queue-length=1
          operation=DiagnosticInfo/GetEventStatus, queue-length=1
          operation=DiagnosticInfo/GetEventTested, queue-length=1
          operation=DiagnosticInfo/GetFaultDetectionCounter, queue-length=1
      EventInfo_IOHWAB_E_PROC_FAIL: provided-interface=DiagnosticInfo
        provided-com-specs:
          operation=DiagnosticInfo/GetDTCOfEvent, queue-length=1
          operation=DiagnosticInfo/GetEventExtendedDataRecord, queue-length=1
          operation=DiagnosticInfo/GetEventFailed, queue-length=1
          operation=DiagnosticInfo/GetEventFreezeFrameData, queue-length=1
          operation=DiagnosticInfo/GetEventStatus, queue-length=1
          operation=DiagnosticInfo/GetEventTested, queue-length=1
          operation=DiagnosticInfo/GetFaultDetectionCounter, queue-length=1
      EventInfo_IOHWAB_E_SETUP_FAIL: provided-interface=DiagnosticInfo
        provided-com-specs:
          operation=DiagnosticInfo/GetDTCOfEvent, queue-length=1
          operation=DiagnosticInfo/GetEventExtendedDataRecord, queue-length=1
          operation=DiagnosticInfo/GetEventFailed, queue-length=1
          operation=DiagnosticInfo/GetEventFreezeFrameData, queue-length=1
          operation=DiagnosticInfo/GetEventStatus, queue-length=1
          operation=DiagnosticInfo/GetEventTested, queue-length=1
          operation=DiagnosticInfo/GetFaultDetectionCounter, queue-length=1
      EventInfo_IOHWAB_E_WRONG_PARAM: provided-interface=DiagnosticInfo
        provided-com-specs:
          operation=DiagnosticInfo/GetDTCOfEvent, queue-length=1
          operation=DiagnosticInfo/GetEventExtendedDataRecord, queue-length=1
          operation=DiagnosticInfo/GetEventFailed, queue-length=1
          operation=DiagnosticInfo/GetEventFreezeFrameData, queue-length=1
          operation=DiagnosticInfo/GetEventStatus, queue-length=1
          operation=DiagnosticInfo/GetEventTested, queue-length=1
          operation=DiagnosticInfo/GetFaultDetectionCounter, queue-length=1
      EventInfo_IOHWAB_E_WRONG_SETTING: provided-interface=DiagnosticInfo
        provided-com-specs:
          operation=DiagnosticInfo/GetDTCOfEvent, queue-length=1
          operation=DiagnosticInfo/GetEventExtendedDataRecord, queue-length=1
          operation=DiagnosticInfo/GetEventFailed, queue-length=1
          operation=DiagnosticInfo/GetEventFreezeFrameData, queue-length=1
          operation=DiagnosticInfo/GetEventStatus, queue-length=1
          operation=DiagnosticInfo/GetEventTested, queue-length=1
          operation=DiagnosticInfo/GetFaultDetectionCounter, queue-length=1
      EventInfo_IOHWAB_E_WRONG_STATE: provided-interface=DiagnosticInfo
        provided-com-specs:
          operation=DiagnosticInfo/GetDTCOfEvent, queue-length=1
          operation=DiagnosticInfo/GetEventExtendedDataRecord, queue-length=1
          operation=DiagnosticInfo/GetEventFailed, queue-length=1
          operation=DiagnosticInfo/GetEventFreezeFrameData, queue-length=1
          operation=DiagnosticInfo/GetEventStatus, queue-length=1
          operation=DiagnosticInfo/GetEventTested, queue-length=1
          operation=DiagnosticInfo/GetFaultDetectionCounter, queue-length=1
      EventInfo_LIN_E_TIMEOUT: provided-interface=DiagnosticInfo
        provided-com-specs:
          operation=DiagnosticInfo/GetDTCOfEvent, queue-length=1
          operation=DiagnosticInfo/GetEventExtendedDataRecord, queue-length=1
          operation=DiagnosticInfo/GetEventFailed, queue-length=1
          operation=DiagnosticInfo/GetEventFreezeFrameData, queue-length=1
          operation=DiagnosticInfo/GetEventStatus, queue-length=1
          operation=DiagnosticInfo/GetEventTested, queue-length=1
          operation=DiagnosticInfo/GetFaultDetectionCounter, queue-length=1
      EventInfo_MCU_E_CLOCK_FAILURE: provided-interface=DiagnosticInfo
        provided-com-specs:
          operation=DiagnosticInfo/GetDTCOfEvent, queue-length=1
          operation=DiagnosticInfo/GetEventExtendedDataRecord, queue-length=1
          operation=DiagnosticInfo/GetEventFailed, queue-length=1
          operation=DiagnosticInfo/GetEventFreezeFrameData, queue-length=1
          operation=DiagnosticInfo/GetEventStatus, queue-length=1
          operation=DiagnosticInfo/GetEventTested, queue-length=1
          operation=DiagnosticInfo/GetFaultDetectionCounter, queue-length=1
      EventInfo_MCU_E_LOCK_FAILURE: provided-interface=DiagnosticInfo
        provided-com-specs:
          operation=DiagnosticInfo/GetDTCOfEvent, queue-length=1
          operation=DiagnosticInfo/GetEventExtendedDataRecord, queue-length=1
          operation=DiagnosticInfo/GetEventFailed, queue-length=1
          operation=DiagnosticInfo/GetEventFreezeFrameData, queue-length=1
          operation=DiagnosticInfo/GetEventStatus, queue-length=1
          operation=DiagnosticInfo/GetEventTested, queue-length=1
          operation=DiagnosticInfo/GetFaultDetectionCounter, queue-length=1
      EventInfo_MCU_E_QUARTZ_FAILURE: provided-interface=DiagnosticInfo
        provided-com-specs:
          operation=DiagnosticInfo/GetDTCOfEvent, queue-length=1
          operation=DiagnosticInfo/GetEventExtendedDataRecord, queue-length=1
          operation=DiagnosticInfo/GetEventFailed, queue-length=1
          operation=DiagnosticInfo/GetEventFreezeFrameData, queue-length=1
          operation=DiagnosticInfo/GetEventStatus, queue-length=1
          operation=DiagnosticInfo/GetEventTested, queue-length=1
          operation=DiagnosticInfo/GetFaultDetectionCounter, queue-length=1
      EventInfo_MCU_E_TIMEOUT_TRANSITION: provided-interface=DiagnosticInfo
        provided-com-specs:
          operation=DiagnosticInfo/GetDTCOfEvent, queue-length=1
          operation=DiagnosticInfo/GetEventExtendedDataRecord, queue-length=1
          operation=DiagnosticInfo/GetEventFailed, queue-length=1
          operation=DiagnosticInfo/GetEventFreezeFrameData, queue-length=1
          operation=DiagnosticInfo/GetEventStatus, queue-length=1
          operation=DiagnosticInfo/GetEventTested, queue-length=1
          operation=DiagnosticInfo/GetFaultDetectionCounter, queue-length=1
      EventInfo_NVM_E_INTEGRITY_FAILED: provided-interface=DiagnosticInfo
        provided-com-specs:
          operation=DiagnosticInfo/GetDTCOfEvent, queue-length=1
          operation=DiagnosticInfo/GetEventExtendedDataRecord, queue-length=1
          operation=DiagnosticInfo/GetEventFailed, queue-length=1
          operation=DiagnosticInfo/GetEventFreezeFrameData, queue-length=1
          operation=DiagnosticInfo/GetEventStatus, queue-length=1
          operation=DiagnosticInfo/GetEventTested, queue-length=1
          operation=DiagnosticInfo/GetFaultDetectionCounter, queue-length=1
      EventInfo_NVM_E_LOSS_OF_REDUNDANCY: provided-interface=DiagnosticInfo
        provided-com-specs:
          operation=DiagnosticInfo/GetDTCOfEvent, queue-length=1
          operation=DiagnosticInfo/GetEventExtendedDataRecord, queue-length=1
          operation=DiagnosticInfo/GetEventFailed, queue-length=1
          operation=DiagnosticInfo/GetEventFreezeFrameData, queue-length=1
          operation=DiagnosticInfo/GetEventStatus, queue-length=1
          operation=DiagnosticInfo/GetEventTested, queue-length=1
          operation=DiagnosticInfo/GetFaultDetectionCounter, queue-length=1
      EventInfo_NVM_E_QUEUE_OVERFLOW: provided-interface=DiagnosticInfo
        provided-com-specs:
          operation=DiagnosticInfo/GetDTCOfEvent, queue-length=1
          operation=DiagnosticInfo/GetEventExtendedDataRecord, queue-length=1
          operation=DiagnosticInfo/GetEventFailed, queue-length=1
          operation=DiagnosticInfo/GetEventFreezeFrameData, queue-length=1
          operation=DiagnosticInfo/GetEventStatus, queue-length=1
          operation=DiagnosticInfo/GetEventTested, queue-length=1
          operation=DiagnosticInfo/GetFaultDetectionCounter, queue-length=1
      EventInfo_NVM_E_REQ_FAILED: provided-interface=DiagnosticInfo
        provided-com-specs:
          operation=DiagnosticInfo/GetDTCOfEvent, queue-length=1
          operation=DiagnosticInfo/GetEventExtendedDataRecord, queue-length=1
          operation=DiagnosticInfo/GetEventFailed, queue-length=1
          operation=DiagnosticInfo/GetEventFreezeFrameData, queue-length=1
          operation=DiagnosticInfo/GetEventStatus, queue-length=1
          operation=DiagnosticInfo/GetEventTested, queue-length=1
          operation=DiagnosticInfo/GetFaultDetectionCounter, queue-length=1
      EventInfo_NVM_E_VERIFY_FAILED: provided-interface=DiagnosticInfo
        provided-com-specs:
          operation=DiagnosticInfo/GetDTCOfEvent, queue-length=1
          operation=DiagnosticInfo/GetEventExtendedDataRecord, queue-length=1
          operation=DiagnosticInfo/GetEventFailed, queue-length=1
          operation=DiagnosticInfo/GetEventFreezeFrameData, queue-length=1
          operation=DiagnosticInfo/GetEventStatus, queue-length=1
          operation=DiagnosticInfo/GetEventTested, queue-length=1
          operation=DiagnosticInfo/GetFaultDetectionCounter, queue-length=1
      EventInfo_NVM_E_WRITE_PROTECTED: provided-interface=DiagnosticInfo
        provided-com-specs:
          operation=DiagnosticInfo/GetDTCOfEvent, queue-length=1
          operation=DiagnosticInfo/GetEventExtendedDataRecord, queue-length=1
          operation=DiagnosticInfo/GetEventFailed, queue-length=1
          operation=DiagnosticInfo/GetEventFreezeFrameData, queue-length=1
          operation=DiagnosticInfo/GetEventStatus, queue-length=1
          operation=DiagnosticInfo/GetEventTested, queue-length=1
          operation=DiagnosticInfo/GetFaultDetectionCounter, queue-length=1
      EventInfo_NVM_E_WRONG_BLOCK_ID: provided-interface=DiagnosticInfo
        provided-com-specs:
          operation=DiagnosticInfo/GetDTCOfEvent, queue-length=1
          operation=DiagnosticInfo/GetEventExtendedDataRecord, queue-length=1
          operation=DiagnosticInfo/GetEventFailed, queue-length=1
          operation=DiagnosticInfo/GetEventFreezeFrameData, queue-length=1
          operation=DiagnosticInfo/GetEventStatus, queue-length=1
          operation=DiagnosticInfo/GetEventTested, queue-length=1
          operation=DiagnosticInfo/GetFaultDetectionCounter, queue-length=1
      EventInfo_PWM_E_UNEXPECTED_IRQ: provided-interface=DiagnosticInfo
        provided-com-specs:
          operation=DiagnosticInfo/GetDTCOfEvent, queue-length=1
          operation=DiagnosticInfo/GetEventExtendedDataRecord, queue-length=1
          operation=DiagnosticInfo/GetEventFailed, queue-length=1
          operation=DiagnosticInfo/GetEventFreezeFrameData, queue-length=1
          operation=DiagnosticInfo/GetEventStatus, queue-length=1
          operation=DiagnosticInfo/GetEventTested, queue-length=1
          operation=DiagnosticInfo/GetFaultDetectionCounter, queue-length=1
      EventInfo_RAMTST_E_RAM_FAILURE: provided-interface=DiagnosticInfo
        provided-com-specs:
          operation=DiagnosticInfo/GetDTCOfEvent, queue-length=1
          operation=DiagnosticInfo/GetEventExtendedDataRecord, queue-length=1
          operation=DiagnosticInfo/GetEventFailed, queue-length=1
          operation=DiagnosticInfo/GetEventFreezeFrameData, queue-length=1
          operation=DiagnosticInfo/GetEventStatus, queue-length=1
          operation=DiagnosticInfo/GetEventTested, queue-length=1
          operation=DiagnosticInfo/GetFaultDetectionCounter, queue-length=1
      EventInfo_REGMON_E_REG_FAILURE: provided-interface=DiagnosticInfo
        provided-com-specs:
          operation=DiagnosticInfo/GetDTCOfEvent, queue-length=1
          operation=DiagnosticInfo/GetEventExtendedDataRecord, queue-length=1
          operation=DiagnosticInfo/GetEventFailed, queue-length=1
          operation=DiagnosticInfo/GetEventFreezeFrameData, queue-length=1
          operation=DiagnosticInfo/GetEventStatus, queue-length=1
          operation=DiagnosticInfo/GetEventTested, queue-length=1
          operation=DiagnosticInfo/GetFaultDetectionCounter, queue-length=1
      EventInfo_SPI_E_TIMEOUT: provided-interface=DiagnosticInfo
        provided-com-specs:
          operation=DiagnosticInfo/GetDTCOfEvent, queue-length=1
          operation=DiagnosticInfo/GetEventExtendedDataRecord, queue-length=1
          operation=DiagnosticInfo/GetEventFailed, queue-length=1
          operation=DiagnosticInfo/GetEventFreezeFrameData, queue-length=1
          operation=DiagnosticInfo/GetEventStatus, queue-length=1
          operation=DiagnosticInfo/GetEventTested, queue-length=1
          operation=DiagnosticInfo/GetFaultDetectionCounter, queue-length=1
      EventInfo_WDGM_E_IMPROPER_CALLER: provided-interface=DiagnosticInfo
        provided-com-specs:
          operation=DiagnosticInfo/GetDTCOfEvent, queue-length=1
          operation=DiagnosticInfo/GetEventExtendedDataRecord, queue-length=1
          operation=DiagnosticInfo/GetEventFailed, queue-length=1
          operation=DiagnosticInfo/GetEventFreezeFrameData, queue-length=1
          operation=DiagnosticInfo/GetEventStatus, queue-length=1
          operation=DiagnosticInfo/GetEventTested, queue-length=1
          operation=DiagnosticInfo/GetFaultDetectionCounter, queue-length=1
      EventInfo_WDGM_E_MONITORING: provided-interface=DiagnosticInfo
        provided-com-specs:
          operation=DiagnosticInfo/GetDTCOfEvent, queue-length=1
          operation=DiagnosticInfo/GetEventExtendedDataRecord, queue-length=1
          operation=DiagnosticInfo/GetEventFailed, queue-length=1
          operation=DiagnosticInfo/GetEventFreezeFrameData, queue-length=1
          operation=DiagnosticInfo/GetEventStatus, queue-length=1
          operation=DiagnosticInfo/GetEventTested, queue-length=1
          operation=DiagnosticInfo/GetFaultDetectionCounter, queue-length=1
      EventInfo_WDGM_E_SET_MODE: provided-interface=DiagnosticInfo
        provided-com-specs:
          operation=DiagnosticInfo/GetDTCOfEvent, queue-length=1
          operation=DiagnosticInfo/GetEventExtendedDataRecord, queue-length=1
          operation=DiagnosticInfo/GetEventFailed, queue-length=1
          operation=DiagnosticInfo/GetEventFreezeFrameData, queue-length=1
          operation=DiagnosticInfo/GetEventStatus, queue-length=1
          operation=DiagnosticInfo/GetEventTested, queue-length=1
          operation=DiagnosticInfo/GetFaultDetectionCounter, queue-length=1
      EventInfo_WDG_76_ACW_E_DISABLE_REJECTED: provided-interface=DiagnosticInfo
        provided-com-specs:
          operation=DiagnosticInfo/GetDTCOfEvent, queue-length=1
          operation=DiagnosticInfo/GetEventExtendedDataRecord, queue-length=1
          operation=DiagnosticInfo/GetEventFailed, queue-length=1
          operation=DiagnosticInfo/GetEventFreezeFrameData, queue-length=1
          operation=DiagnosticInfo/GetEventStatus, queue-length=1
          operation=DiagnosticInfo/GetEventTested, queue-length=1
          operation=DiagnosticInfo/GetFaultDetectionCounter, queue-length=1
      EventInfo_WDG_76_ACW_E_MODE_FAILED: provided-interface=DiagnosticInfo
        provided-com-specs:
          operation=DiagnosticInfo/GetDTCOfEvent, queue-length=1
          operation=DiagnosticInfo/GetEventExtendedDataRecord, queue-length=1
          operation=DiagnosticInfo/GetEventFailed, queue-length=1
          operation=DiagnosticInfo/GetEventFreezeFrameData, queue-length=1
          operation=DiagnosticInfo/GetEventStatus, queue-length=1
          operation=DiagnosticInfo/GetEventTested, queue-length=1
          operation=DiagnosticInfo/GetFaultDetectionCounter, queue-length=1
      EventInfo_WDG_E_DISABLE_REJECTED: provided-interface=DiagnosticInfo
        provided-com-specs:
          operation=DiagnosticInfo/GetDTCOfEvent, queue-length=1
          operation=DiagnosticInfo/GetEventExtendedDataRecord, queue-length=1
          operation=DiagnosticInfo/GetEventFailed, queue-length=1
          operation=DiagnosticInfo/GetEventFreezeFrameData, queue-length=1
          operation=DiagnosticInfo/GetEventStatus, queue-length=1
          operation=DiagnosticInfo/GetEventTested, queue-length=1
          operation=DiagnosticInfo/GetFaultDetectionCounter, queue-length=1
      EventInfo_WDG_E_MISS_TRIGGER: provided-interface=DiagnosticInfo
        provided-com-specs:
          operation=DiagnosticInfo/GetDTCOfEvent, queue-length=1
          operation=DiagnosticInfo/GetEventExtendedDataRecord, queue-length=1
          operation=DiagnosticInfo/GetEventFailed, queue-length=1
          operation=DiagnosticInfo/GetEventFreezeFrameData, queue-length=1
          operation=DiagnosticInfo/GetEventStatus, queue-length=1
          operation=DiagnosticInfo/GetEventTested, queue-length=1
          operation=DiagnosticInfo/GetFaultDetectionCounter, queue-length=1
      EventInfo_WDG_E_MODE_FAILED: provided-interface=DiagnosticInfo
        provided-com-specs:
          operation=DiagnosticInfo/GetDTCOfEvent, queue-length=1
          operation=DiagnosticInfo/GetEventExtendedDataRecord, queue-length=1
          operation=DiagnosticInfo/GetEventFailed, queue-length=1
          operation=DiagnosticInfo/GetEventFreezeFrameData, queue-length=1
          operation=DiagnosticInfo/GetEventStatus, queue-length=1
          operation=DiagnosticInfo/GetEventTested, queue-length=1
          operation=DiagnosticInfo/GetFaultDetectionCounter, queue-length=1
      Event_DEM_E_TEST_EVENT1: provided-interface=DiagnosticMonitor
        provided-com-specs:
          operation=ResetEventStatus, queue-length=1
          operation=SetEventDisabled, queue-length=1
          operation=SetEventStatus, queue-length=1
      Event_DEM_E_TEST_EVENT2: provided-interface=DiagnosticMonitor
        provided-com-specs:
          operation=ResetEventStatus, queue-length=1
          operation=SetEventDisabled, queue-length=1
          operation=SetEventStatus, queue-length=1
      Event_DEM_E_TEST_EVENT3: provided-interface=DiagnosticMonitor
        provided-com-specs:
          operation=ResetEventStatus, queue-length=1
          operation=SetEventDisabled, queue-length=1
          operation=SetEventStatus, queue-length=1
      Event_DEM_E_TEST_EVENT4: provided-interface=DiagnosticMonitor
        provided-com-specs:
          operation=ResetEventStatus, queue-length=1
          operation=SetEventDisabled, queue-length=1
          operation=SetEventStatus, queue-length=1
      Event_DEM_E_TEST_EVENT5: provided-interface=DiagnosticMonitor
        provided-com-specs:
          operation=ResetEventStatus, queue-length=1
          operation=SetEventDisabled, queue-length=1
          operation=SetEventStatus, queue-length=1
      Event_DEM_E_TEST_EVENT6: provided-interface=DiagnosticMonitor
        provided-com-specs:
          operation=ResetEventStatus, queue-length=1
          operation=SetEventDisabled, queue-length=1
          operation=SetEventStatus, queue-length=1
    require port GeneralCBDataEvt: client-com-spec=GeneralCallbackEventDataChanged/EventDataChanged, required-interface=GeneralCallbackEventDataChanged
    require port GeneralCBStatusEvt: client-com-spec=GeneralCallbackEventStatusChange/EventStatusChanged, required-interface=GeneralCallbackEventStatusChange
    5 x provide port:
      GeneralEvtInfo: provided-interface=GeneralDiagnosticInfo
        provided-com-specs:
          operation=GeneralDiagnosticInfo/GetDTCOfEvent, queue-length=1
          operation=GeneralDiagnosticInfo/GetEventExtendedDataRecord, queue-length=1
          operation=GeneralDiagnosticInfo/GetEventFailed, queue-length=1
          operation=GeneralDiagnosticInfo/GetEventFreezeFrameData, queue-length=1
          operation=GeneralDiagnosticInfo/GetEventStatus, queue-length=1
          operation=GeneralDiagnosticInfo/GetEventTested, queue-length=1
          operation=GeneralDiagnosticInfo/GetFaultDetectionCounter, queue-length=1
      IndStatus_DemIndicator_0: server-com-spec{operation=GetIndicatorStatus, queue-length=1}, provided-interface=IndicatorStatus
      IndStatus_DemIndicator_1: server-com-spec{operation=GetIndicatorStatus, queue-length=1}, provided-interface=IndicatorStatus
      OpCycle_DemOperationCycle0: server-com-spec{operation=SetOperationCycleState, queue-length=1}, provided-interface=OperationCycle
      OverflowIndPrimaryMemory: server-com-spec{operation=GetEventMemoryOverflow, queue-length=1}, provided-interface=EvMemOverflowIndication
    behavior DemInternalBehavior: handle-termination-and-restart=NO-SUPPORT, included-data-type-set=data-type=[Dem_ReturnDisableDTCRecordUpdateType, Dem_ReturnGetFreezeFrameDataByDTCType, Dem_ReturnGetSizeOfExtendedDataRecordByDTCType, Dem_ReturnGetSeverityOfDTCType, Dem_DTCFormatType, Dem_DTCKindType, Dem_DTCOriginType, Dem_DTCRequestType, Dem_ReturnGetNumberOfFilteredDTCType, Dem_DTCSeverityType, Dem_DTCTranslationFormatType, Dem_EventStatusType, Dem_IndicatorStatusType, Dem_InitMonitorReasonType, Dem_ReturnSetFilterType, Dem_OperationCycleStateType, Dem_ReturnGetFunctionalUnitOfDTCType, Dem_EventStatusExtendedType, Dem_EventIdType, DataArrayType_DE_0001, DataArrayType_DE_0002, Dem_ReturnGetStatusOfDTCType, Dem_MaxDataValueType, Dem_ReturnGetSizeOfFreezeFrameByDTCType, Dem_DTCStatusMaskType, Dem_ReturnGetNextFilteredDTCType, Dem_ReturnClearDTCType, Dem_ReturnControlDTCSettingType, Dem_ReturnGetExtendedDataRecordByDTCType, Dem_ReturnGetDTCByOccurrenceTimeType]
      514 x operation invoked event:
        OIE_Cdd_ClearDTC: start-on-event=ClearDTC, operation=Cdd.ClearDTC
        OIE_EnableCond_DemEnableCondition_SetEnableCondition: start-on-event=SetEnableCondition, operation=EnableCond_DemEnableCondition.SetEnableCondition
        OIE_EventInfo_ADC_E_TIMEOUT_GetDTCOfEvent: start-on-event=GetDTCOfEvent, operation=EventInfo_ADC_E_TIMEOUT.GetDTCOfEvent
        OIE_EventInfo_ADC_E_TIMEOUT_GetEventExtendedDataRecord: start-on-event=GetEventExtendedDataRecord, operation=EventInfo_ADC_E_TIMEOUT.GetEventExtendedDataRecord
        OIE_EventInfo_ADC_E_TIMEOUT_GetEventFailed: start-on-event=GetEventFailed, operation=EventInfo_ADC_E_TIMEOUT.GetEventFailed
        OIE_EventInfo_ADC_E_TIMEOUT_GetEventFreezeFrameData: start-on-event=GetEventFreezeFrameData, operation=EventInfo_ADC_E_TIMEOUT.GetEventFreezeFrameData
        OIE_EventInfo_ADC_E_TIMEOUT_GetEventStatus: start-on-event=GetEventStatus, operation=EventInfo_ADC_E_TIMEOUT.GetEventStatus
        OIE_EventInfo_ADC_E_TIMEOUT_GetEventTested: start-on-event=GetEventTested, operation=EventInfo_ADC_E_TIMEOUT.GetEventTested
        OIE_EventInfo_ADC_E_TIMEOUT_GetFaultDetectionCounter: start-on-event=GetFaultDetectionCounter, operation=EventInfo_ADC_E_TIMEOUT.GetFaultDetectionCounter
        OIE_EventInfo_CANCM_E_BAT_FAIL_GetDTCOfEvent: start-on-event=GetDTCOfEvent, operation=EventInfo_CANCM_E_BAT_FAIL.GetDTCOfEvent
        OIE_EventInfo_CANCM_E_BAT_FAIL_GetEventExtendedDataRecord: start-on-event=GetEventExtendedDataRecord, operation=EventInfo_CANCM_E_BAT_FAIL.GetEventExtendedDataRecord
        OIE_EventInfo_CANCM_E_BAT_FAIL_GetEventFailed: start-on-event=GetEventFailed, operation=EventInfo_CANCM_E_BAT_FAIL.GetEventFailed
        OIE_EventInfo_CANCM_E_BAT_FAIL_GetEventFreezeFrameData: start-on-event=GetEventFreezeFrameData, operation=EventInfo_CANCM_E_BAT_FAIL.GetEventFreezeFrameData
        OIE_EventInfo_CANCM_E_BAT_FAIL_GetEventStatus: start-on-event=GetEventStatus, operation=EventInfo_CANCM_E_BAT_FAIL.GetEventStatus
        OIE_EventInfo_CANCM_E_BAT_FAIL_GetEventTested: start-on-event=GetEventTested, operation=EventInfo_CANCM_E_BAT_FAIL.GetEventTested
        OIE_EventInfo_CANCM_E_BAT_FAIL_GetFaultDetectionCounter: start-on-event=GetFaultDetectionCounter, operation=EventInfo_CANCM_E_BAT_FAIL.GetFaultDetectionCounter
        OIE_EventInfo_CANSM_E_BUS_OFF_GetDTCOfEvent: start-on-event=GetDTCOfEvent, operation=EventInfo_CANSM_E_BUS_OFF.GetDTCOfEvent
        OIE_EventInfo_CANSM_E_BUS_OFF_GetEventExtendedDataRecord: start-on-event=GetEventExtendedDataRecord, operation=EventInfo_CANSM_E_BUS_OFF.GetEventExtendedDataRecord
        OIE_EventInfo_CANSM_E_BUS_OFF_GetEventFailed: start-on-event=GetEventFailed, operation=EventInfo_CANSM_E_BUS_OFF.GetEventFailed
        OIE_EventInfo_CANSM_E_BUS_OFF_GetEventFreezeFrameData: start-on-event=GetEventFreezeFrameData, operation=EventInfo_CANSM_E_BUS_OFF.GetEventFreezeFrameData
        OIE_EventInfo_CANSM_E_BUS_OFF_GetEventStatus: start-on-event=GetEventStatus, operation=EventInfo_CANSM_E_BUS_OFF.GetEventStatus
        OIE_EventInfo_CANSM_E_BUS_OFF_GetEventTested: start-on-event=GetEventTested, operation=EventInfo_CANSM_E_BUS_OFF.GetEventTested
        OIE_EventInfo_CANSM_E_BUS_OFF_GetFaultDetectionCounter: start-on-event=GetFaultDetectionCounter, operation=EventInfo_CANSM_E_BUS_OFF.GetFaultDetectionCounter
        OIE_EventInfo_CANSM_E_MODE_CHANGE_PROJECT_GetDTCOfEvent: start-on-event=GetDTCOfEvent, operation=EventInfo_CANSM_E_MODE_CHANGE_PROJECT.GetDTCOfEvent
        OIE_EventInfo_CANSM_E_MODE_CHANGE_PROJECT_GetEventExtendedDataRecord: start-on-event=GetEventExtendedDataRecord, operation=EventInfo_CANSM_E_MODE_CHANGE_PROJECT.GetEventExtendedDataRecord
        OIE_EventInfo_CANSM_E_MODE_CHANGE_PROJECT_GetEventFailed: start-on-event=GetEventFailed, operation=EventInfo_CANSM_E_MODE_CHANGE_PROJECT.GetEventFailed
        OIE_EventInfo_CANSM_E_MODE_CHANGE_PROJECT_GetEventFreezeFrameData: start-on-event=GetEventFreezeFrameData, operation=EventInfo_CANSM_E_MODE_CHANGE_PROJECT.GetEventFreezeFrameData
        OIE_EventInfo_CANSM_E_MODE_CHANGE_PROJECT_GetEventStatus: start-on-event=GetEventStatus, operation=EventInfo_CANSM_E_MODE_CHANGE_PROJECT.GetEventStatus
        OIE_EventInfo_CANSM_E_MODE_CHANGE_PROJECT_GetEventTested: start-on-event=GetEventTested, operation=EventInfo_CANSM_E_MODE_CHANGE_PROJECT.GetEventTested
        OIE_EventInfo_CANSM_E_MODE_CHANGE_PROJECT_GetFaultDetectionCounter: start-on-event=GetFaultDetectionCounter, operation=EventInfo_CANSM_E_MODE_CHANGE_PROJECT.GetFaultDetectionCounter
        OIE_EventInfo_DEM_E_TEST_EVENT1_GetDTCOfEvent: start-on-event=GetDTCOfEvent, operation=EventInfo_DEM_E_TEST_EVENT1.GetDTCOfEvent
        OIE_EventInfo_DEM_E_TEST_EVENT1_GetEventExtendedDataRecord: start-on-event=GetEventExtendedDataRecord, operation=EventInfo_DEM_E_TEST_EVENT1.GetEventExtendedDataRecord
        OIE_EventInfo_DEM_E_TEST_EVENT1_GetEventFailed: start-on-event=GetEventFailed, operation=EventInfo_DEM_E_TEST_EVENT1.GetEventFailed
        OIE_EventInfo_DEM_E_TEST_EVENT1_GetEventFreezeFrameData: start-on-event=GetEventFreezeFrameData, operation=EventInfo_DEM_E_TEST_EVENT1.GetEventFreezeFrameData
        OIE_EventInfo_DEM_E_TEST_EVENT1_GetEventStatus: start-on-event=GetEventStatus, operation=EventInfo_DEM_E_TEST_EVENT1.GetEventStatus
        OIE_EventInfo_DEM_E_TEST_EVENT1_GetEventTested: start-on-event=GetEventTested, operation=EventInfo_DEM_E_TEST_EVENT1.GetEventTested
        OIE_EventInfo_DEM_E_TEST_EVENT1_GetFaultDetectionCounter: start-on-event=GetFaultDetectionCounter, operation=EventInfo_DEM_E_TEST_EVENT1.GetFaultDetectionCounter
        OIE_EventInfo_DEM_E_TEST_EVENT2_GetDTCOfEvent: start-on-event=GetDTCOfEvent, operation=EventInfo_DEM_E_TEST_EVENT2.GetDTCOfEvent
        OIE_EventInfo_DEM_E_TEST_EVENT2_GetEventExtendedDataRecord: start-on-event=GetEventExtendedDataRecord, operation=EventInfo_DEM_E_TEST_EVENT2.GetEventExtendedDataRecord
        OIE_EventInfo_DEM_E_TEST_EVENT2_GetEventFailed: start-on-event=GetEventFailed, operation=EventInfo_DEM_E_TEST_EVENT2.GetEventFailed
        OIE_EventInfo_DEM_E_TEST_EVENT2_GetEventFreezeFrameData: start-on-event=GetEventFreezeFrameData, operation=EventInfo_DEM_E_TEST_EVENT2.GetEventFreezeFrameData
        OIE_EventInfo_DEM_E_TEST_EVENT2_GetEventStatus: start-on-event=GetEventStatus, operation=EventInfo_DEM_E_TEST_EVENT2.GetEventStatus
        OIE_EventInfo_DEM_E_TEST_EVENT2_GetEventTested: start-on-event=GetEventTested, operation=EventInfo_DEM_E_TEST_EVENT2.GetEventTested
        OIE_EventInfo_DEM_E_TEST_EVENT2_GetFaultDetectionCounter: start-on-event=GetFaultDetectionCounter, operation=EventInfo_DEM_E_TEST_EVENT2.GetFaultDetectionCounter
        OIE_EventInfo_DEM_E_TEST_EVENT3_GetDTCOfEvent: start-on-event=GetDTCOfEvent, operation=EventInfo_DEM_E_TEST_EVENT3.GetDTCOfEvent
        OIE_EventInfo_DEM_E_TEST_EVENT3_GetEventExtendedDataRecord: start-on-event=GetEventExtendedDataRecord, operation=EventInfo_DEM_E_TEST_EVENT3.GetEventExtendedDataRecord
        OIE_EventInfo_DEM_E_TEST_EVENT3_GetEventFailed: start-on-event=GetEventFailed, operation=EventInfo_DEM_E_TEST_EVENT3.GetEventFailed
        OIE_EventInfo_DEM_E_TEST_EVENT3_GetEventFreezeFrameData: start-on-event=GetEventFreezeFrameData, operation=EventInfo_DEM_E_TEST_EVENT3.GetEventFreezeFrameData
        OIE_EventInfo_DEM_E_TEST_EVENT3_GetEventStatus: start-on-event=GetEventStatus, operation=EventInfo_DEM_E_TEST_EVENT3.GetEventStatus
        OIE_EventInfo_DEM_E_TEST_EVENT3_GetEventTested: start-on-event=GetEventTested, operation=EventInfo_DEM_E_TEST_EVENT3.GetEventTested
        OIE_EventInfo_DEM_E_TEST_EVENT3_GetFaultDetectionCounter: start-on-event=GetFaultDetectionCounter, operation=EventInfo_DEM_E_TEST_EVENT3.GetFaultDetectionCounter
        OIE_EventInfo_DEM_E_TEST_EVENT4_GetDTCOfEvent: start-on-event=GetDTCOfEvent, operation=EventInfo_DEM_E_TEST_EVENT4.GetDTCOfEvent
        OIE_EventInfo_DEM_E_TEST_EVENT4_GetEventExtendedDataRecord: start-on-event=GetEventExtendedDataRecord, operation=EventInfo_DEM_E_TEST_EVENT4.GetEventExtendedDataRecord
        OIE_EventInfo_DEM_E_TEST_EVENT4_GetEventFailed: start-on-event=GetEventFailed, operation=EventInfo_DEM_E_TEST_EVENT4.GetEventFailed
        OIE_EventInfo_DEM_E_TEST_EVENT4_GetEventFreezeFrameData: start-on-event=GetEventFreezeFrameData, operation=EventInfo_DEM_E_TEST_EVENT4.GetEventFreezeFrameData
        OIE_EventInfo_DEM_E_TEST_EVENT4_GetEventStatus: start-on-event=GetEventStatus, operation=EventInfo_DEM_E_TEST_EVENT4.GetEventStatus
        OIE_EventInfo_DEM_E_TEST_EVENT4_GetEventTested: start-on-event=GetEventTested, operation=EventInfo_DEM_E_TEST_EVENT4.GetEventTested
        OIE_EventInfo_DEM_E_TEST_EVENT4_GetFaultDetectionCounter: start-on-event=GetFaultDetectionCounter, operation=EventInfo_DEM_E_TEST_EVENT4.GetFaultDetectionCounter
        OIE_EventInfo_DEM_E_TEST_EVENT5_GetDTCOfEvent: start-on-event=GetDTCOfEvent, operation=EventInfo_DEM_E_TEST_EVENT5.GetDTCOfEvent
        OIE_EventInfo_DEM_E_TEST_EVENT5_GetEventExtendedDataRecord: start-on-event=GetEventExtendedDataRecord, operation=EventInfo_DEM_E_TEST_EVENT5.GetEventExtendedDataRecord
        OIE_EventInfo_DEM_E_TEST_EVENT5_GetEventFailed: start-on-event=GetEventFailed, operation=EventInfo_DEM_E_TEST_EVENT5.GetEventFailed
        OIE_EventInfo_DEM_E_TEST_EVENT5_GetEventFreezeFrameData: start-on-event=GetEventFreezeFrameData, operation=EventInfo_DEM_E_TEST_EVENT5.GetEventFreezeFrameData
        OIE_EventInfo_DEM_E_TEST_EVENT5_GetEventStatus: start-on-event=GetEventStatus, operation=EventInfo_DEM_E_TEST_EVENT5.GetEventStatus
        OIE_EventInfo_DEM_E_TEST_EVENT5_GetEventTested: start-on-event=GetEventTested, operation=EventInfo_DEM_E_TEST_EVENT5.GetEventTested
        OIE_EventInfo_DEM_E_TEST_EVENT5_GetFaultDetectionCounter: start-on-event=GetFaultDetectionCounter, operation=EventInfo_DEM_E_TEST_EVENT5.GetFaultDetectionCounter
        OIE_EventInfo_DEM_E_TEST_EVENT6_GetDTCOfEvent: start-on-event=GetDTCOfEvent, operation=EventInfo_DEM_E_TEST_EVENT6.GetDTCOfEvent
        OIE_EventInfo_DEM_E_TEST_EVENT6_GetEventExtendedDataRecord: start-on-event=GetEventExtendedDataRecord, operation=EventInfo_DEM_E_TEST_EVENT6.GetEventExtendedDataRecord
        OIE_EventInfo_DEM_E_TEST_EVENT6_GetEventFailed: start-on-event=GetEventFailed, operation=EventInfo_DEM_E_TEST_EVENT6.GetEventFailed
        OIE_EventInfo_DEM_E_TEST_EVENT6_GetEventFreezeFrameData: start-on-event=GetEventFreezeFrameData, operation=EventInfo_DEM_E_TEST_EVENT6.GetEventFreezeFrameData
        OIE_EventInfo_DEM_E_TEST_EVENT6_GetEventStatus: start-on-event=GetEventStatus, operation=EventInfo_DEM_E_TEST_EVENT6.GetEventStatus
        OIE_EventInfo_DEM_E_TEST_EVENT6_GetEventTested: start-on-event=GetEventTested, operation=EventInfo_DEM_E_TEST_EVENT6.GetEventTested
        OIE_EventInfo_DEM_E_TEST_EVENT6_GetFaultDetectionCounter: start-on-event=GetFaultDetectionCounter, operation=EventInfo_DEM_E_TEST_EVENT6.GetFaultDetectionCounter
        OIE_EventInfo_Dem_FEE_GC_ERASE_ERROR_GetDTCOfEvent: start-on-event=GetDTCOfEvent, operation=EventInfo_Dem_FEE_GC_ERASE_ERROR.GetDTCOfEvent
        OIE_EventInfo_Dem_FEE_GC_ERASE_ERROR_GetEventExtendedDataRecord: start-on-event=GetEventExtendedDataRecord, operation=EventInfo_Dem_FEE_GC_ERASE_ERROR.GetEventExtendedDataRecord
        OIE_EventInfo_Dem_FEE_GC_ERASE_ERROR_GetEventFailed: start-on-event=GetEventFailed, operation=EventInfo_Dem_FEE_GC_ERASE_ERROR.GetEventFailed
        OIE_EventInfo_Dem_FEE_GC_ERASE_ERROR_GetEventFreezeFrameData: start-on-event=GetEventFreezeFrameData, operation=EventInfo_Dem_FEE_GC_ERASE_ERROR.GetEventFreezeFrameData
        OIE_EventInfo_Dem_FEE_GC_ERASE_ERROR_GetEventStatus: start-on-event=GetEventStatus, operation=EventInfo_Dem_FEE_GC_ERASE_ERROR.GetEventStatus
        OIE_EventInfo_Dem_FEE_GC_ERASE_ERROR_GetEventTested: start-on-event=GetEventTested, operation=EventInfo_Dem_FEE_GC_ERASE_ERROR.GetEventTested
        OIE_EventInfo_Dem_FEE_GC_ERASE_ERROR_GetFaultDetectionCounter: start-on-event=GetFaultDetectionCounter, operation=EventInfo_Dem_FEE_GC_ERASE_ERROR.GetFaultDetectionCounter
        OIE_EventInfo_Dem_FEE_GC_INIT_ERROR_GetDTCOfEvent: start-on-event=GetDTCOfEvent, operation=EventInfo_Dem_FEE_GC_INIT_ERROR.GetDTCOfEvent
        OIE_EventInfo_Dem_FEE_GC_INIT_ERROR_GetEventExtendedDataRecord: start-on-event=GetEventExtendedDataRecord, operation=EventInfo_Dem_FEE_GC_INIT_ERROR.GetEventExtendedDataRecord
        OIE_EventInfo_Dem_FEE_GC_INIT_ERROR_GetEventFailed: start-on-event=GetEventFailed, operation=EventInfo_Dem_FEE_GC_INIT_ERROR.GetEventFailed
        OIE_EventInfo_Dem_FEE_GC_INIT_ERROR_GetEventFreezeFrameData: start-on-event=GetEventFreezeFrameData, operation=EventInfo_Dem_FEE_GC_INIT_ERROR.GetEventFreezeFrameData
        OIE_EventInfo_Dem_FEE_GC_INIT_ERROR_GetEventStatus: start-on-event=GetEventStatus, operation=EventInfo_Dem_FEE_GC_INIT_ERROR.GetEventStatus
        OIE_EventInfo_Dem_FEE_GC_INIT_ERROR_GetEventTested: start-on-event=GetEventTested, operation=EventInfo_Dem_FEE_GC_INIT_ERROR.GetEventTested
        OIE_EventInfo_Dem_FEE_GC_INIT_ERROR_GetFaultDetectionCounter: start-on-event=GetFaultDetectionCounter, operation=EventInfo_Dem_FEE_GC_INIT_ERROR.GetFaultDetectionCounter
        OIE_EventInfo_Dem_FEE_GC_READ_ERROR_GetDTCOfEvent: start-on-event=GetDTCOfEvent, operation=EventInfo_Dem_FEE_GC_READ_ERROR.GetDTCOfEvent
        OIE_EventInfo_Dem_FEE_GC_READ_ERROR_GetEventExtendedDataRecord: start-on-event=GetEventExtendedDataRecord, operation=EventInfo_Dem_FEE_GC_READ_ERROR.GetEventExtendedDataRecord
        OIE_EventInfo_Dem_FEE_GC_READ_ERROR_GetEventFailed: start-on-event=GetEventFailed, operation=EventInfo_Dem_FEE_GC_READ_ERROR.GetEventFailed
        OIE_EventInfo_Dem_FEE_GC_READ_ERROR_GetEventFreezeFrameData: start-on-event=GetEventFreezeFrameData, operation=EventInfo_Dem_FEE_GC_READ_ERROR.GetEventFreezeFrameData
        OIE_EventInfo_Dem_FEE_GC_READ_ERROR_GetEventStatus: start-on-event=GetEventStatus, operation=EventInfo_Dem_FEE_GC_READ_ERROR.GetEventStatus
        OIE_EventInfo_Dem_FEE_GC_READ_ERROR_GetEventTested: start-on-event=GetEventTested, operation=EventInfo_Dem_FEE_GC_READ_ERROR.GetEventTested
        OIE_EventInfo_Dem_FEE_GC_READ_ERROR_GetFaultDetectionCounter: start-on-event=GetFaultDetectionCounter, operation=EventInfo_Dem_FEE_GC_READ_ERROR.GetFaultDetectionCounter
        OIE_EventInfo_Dem_FEE_GC_TRIG_ERROR_GetDTCOfEvent: start-on-event=GetDTCOfEvent, operation=EventInfo_Dem_FEE_GC_TRIG_ERROR.GetDTCOfEvent
        OIE_EventInfo_Dem_FEE_GC_TRIG_ERROR_GetEventExtendedDataRecord: start-on-event=GetEventExtendedDataRecord, operation=EventInfo_Dem_FEE_GC_TRIG_ERROR.GetEventExtendedDataRecord
        OIE_EventInfo_Dem_FEE_GC_TRIG_ERROR_GetEventFailed: start-on-event=GetEventFailed, operation=EventInfo_Dem_FEE_GC_TRIG_ERROR.GetEventFailed
        OIE_EventInfo_Dem_FEE_GC_TRIG_ERROR_GetEventFreezeFrameData: start-on-event=GetEventFreezeFrameData, operation=EventInfo_Dem_FEE_GC_TRIG_ERROR.GetEventFreezeFrameData
        OIE_EventInfo_Dem_FEE_GC_TRIG_ERROR_GetEventStatus: start-on-event=GetEventStatus, operation=EventInfo_Dem_FEE_GC_TRIG_ERROR.GetEventStatus
        OIE_EventInfo_Dem_FEE_GC_TRIG_ERROR_GetEventTested: start-on-event=GetEventTested, operation=EventInfo_Dem_FEE_GC_TRIG_ERROR.GetEventTested
        OIE_EventInfo_Dem_FEE_GC_TRIG_ERROR_GetFaultDetectionCounter: start-on-event=GetFaultDetectionCounter, operation=EventInfo_Dem_FEE_GC_TRIG_ERROR.GetFaultDetectionCounter
        OIE_EventInfo_Dem_FEE_GC_WRITE_ERROR_GetDTCOfEvent: start-on-event=GetDTCOfEvent, operation=EventInfo_Dem_FEE_GC_WRITE_ERROR.GetDTCOfEvent
        OIE_EventInfo_Dem_FEE_GC_WRITE_ERROR_GetEventExtendedDataRecord: start-on-event=GetEventExtendedDataRecord, operation=EventInfo_Dem_FEE_GC_WRITE_ERROR.GetEventExtendedDataRecord
        OIE_EventInfo_Dem_FEE_GC_WRITE_ERROR_GetEventFailed: start-on-event=GetEventFailed, operation=EventInfo_Dem_FEE_GC_WRITE_ERROR.GetEventFailed
        OIE_EventInfo_Dem_FEE_GC_WRITE_ERROR_GetEventFreezeFrameData: start-on-event=GetEventFreezeFrameData, operation=EventInfo_Dem_FEE_GC_WRITE_ERROR.GetEventFreezeFrameData
        OIE_EventInfo_Dem_FEE_GC_WRITE_ERROR_GetEventStatus: start-on-event=GetEventStatus, operation=EventInfo_Dem_FEE_GC_WRITE_ERROR.GetEventStatus
        OIE_EventInfo_Dem_FEE_GC_WRITE_ERROR_GetEventTested: start-on-event=GetEventTested, operation=EventInfo_Dem_FEE_GC_WRITE_ERROR.GetEventTested
        OIE_EventInfo_Dem_FEE_GC_WRITE_ERROR_GetFaultDetectionCounter: start-on-event=GetFaultDetectionCounter, operation=EventInfo_Dem_FEE_GC_WRITE_ERROR.GetFaultDetectionCounter
        OIE_EventInfo_Dem_FEE_INVALIDATE_ERROR_GetDTCOfEvent: start-on-event=GetDTCOfEvent, operation=EventInfo_Dem_FEE_INVALIDATE_ERROR.GetDTCOfEvent
        OIE_EventInfo_Dem_FEE_INVALIDATE_ERROR_GetEventExtendedDataRecord: start-on-event=GetEventExtendedDataRecord, operation=EventInfo_Dem_FEE_INVALIDATE_ERROR.GetEventExtendedDataRecord
        OIE_EventInfo_Dem_FEE_INVALIDATE_ERROR_GetEventFailed: start-on-event=GetEventFailed, operation=EventInfo_Dem_FEE_INVALIDATE_ERROR.GetEventFailed
        OIE_EventInfo_Dem_FEE_INVALIDATE_ERROR_GetEventFreezeFrameData: start-on-event=GetEventFreezeFrameData, operation=EventInfo_Dem_FEE_INVALIDATE_ERROR.GetEventFreezeFrameData
        OIE_EventInfo_Dem_FEE_INVALIDATE_ERROR_GetEventStatus: start-on-event=GetEventStatus, operation=EventInfo_Dem_FEE_INVALIDATE_ERROR.GetEventStatus
        OIE_EventInfo_Dem_FEE_INVALIDATE_ERROR_GetEventTested: start-on-event=GetEventTested, operation=EventInfo_Dem_FEE_INVALIDATE_ERROR.GetEventTested
        OIE_EventInfo_Dem_FEE_INVALIDATE_ERROR_GetFaultDetectionCounter: start-on-event=GetFaultDetectionCounter, operation=EventInfo_Dem_FEE_INVALIDATE_ERROR.GetFaultDetectionCounter
        OIE_EventInfo_Dem_FEE_READ_ERROR_GetDTCOfEvent: start-on-event=GetDTCOfEvent, operation=EventInfo_Dem_FEE_READ_ERROR.GetDTCOfEvent
        OIE_EventInfo_Dem_FEE_READ_ERROR_GetEventExtendedDataRecord: start-on-event=GetEventExtendedDataRecord, operation=EventInfo_Dem_FEE_READ_ERROR.GetEventExtendedDataRecord
        OIE_EventInfo_Dem_FEE_READ_ERROR_GetEventFailed: start-on-event=GetEventFailed, operation=EventInfo_Dem_FEE_READ_ERROR.GetEventFailed
        OIE_EventInfo_Dem_FEE_READ_ERROR_GetEventFreezeFrameData: start-on-event=GetEventFreezeFrameData, operation=EventInfo_Dem_FEE_READ_ERROR.GetEventFreezeFrameData
        OIE_EventInfo_Dem_FEE_READ_ERROR_GetEventStatus: start-on-event=GetEventStatus, operation=EventInfo_Dem_FEE_READ_ERROR.GetEventStatus
        OIE_EventInfo_Dem_FEE_READ_ERROR_GetEventTested: start-on-event=GetEventTested, operation=EventInfo_Dem_FEE_READ_ERROR.GetEventTested
        OIE_EventInfo_Dem_FEE_READ_ERROR_GetFaultDetectionCounter: start-on-event=GetFaultDetectionCounter, operation=EventInfo_Dem_FEE_READ_ERROR.GetFaultDetectionCounter
        OIE_EventInfo_Dem_FEE_UNCONFIG_BLK_EXCEEDED_ERROR_GetDTCOfEvent: start-on-event=GetDTCOfEvent, operation=EventInfo_Dem_FEE_UNCONFIG_BLK_EXCEEDED_ERROR.GetDTCOfEvent
        OIE_EventInfo_Dem_FEE_UNCONFIG_BLK_EXCEEDED_ERROR_GetEventExtendedDataRecord: start-on-event=GetEventExtendedDataRecord, operation=EventInfo_Dem_FEE_UNCONFIG_BLK_EXCEEDED_ERROR.GetEventExtendedDataRecord
        OIE_EventInfo_Dem_FEE_UNCONFIG_BLK_EXCEEDED_ERROR_GetEventFailed: start-on-event=GetEventFailed, operation=EventInfo_Dem_FEE_UNCONFIG_BLK_EXCEEDED_ERROR.GetEventFailed
        OIE_EventInfo_Dem_FEE_UNCONFIG_BLK_EXCEEDED_ERROR_GetEventFreezeFrameData: start-on-event=GetEventFreezeFrameData, operation=EventInfo_Dem_FEE_UNCONFIG_BLK_EXCEEDED_ERROR.GetEventFreezeFrameData
        OIE_EventInfo_Dem_FEE_UNCONFIG_BLK_EXCEEDED_ERROR_GetEventStatus: start-on-event=GetEventStatus, operation=EventInfo_Dem_FEE_UNCONFIG_BLK_EXCEEDED_ERROR.GetEventStatus
        OIE_EventInfo_Dem_FEE_UNCONFIG_BLK_EXCEEDED_ERROR_GetEventTested: start-on-event=GetEventTested, operation=EventInfo_Dem_FEE_UNCONFIG_BLK_EXCEEDED_ERROR.GetEventTested
        OIE_EventInfo_Dem_FEE_UNCONFIG_BLK_EXCEEDED_ERROR_GetFaultDetectionCounter: start-on-event=GetFaultDetectionCounter, operation=EventInfo_Dem_FEE_UNCONFIG_BLK_EXCEEDED_ERROR.GetFaultDetectionCounter
        OIE_EventInfo_Dem_FEE_WRITE_ERROR_GetDTCOfEvent: start-on-event=GetDTCOfEvent, operation=EventInfo_Dem_FEE_WRITE_ERROR.GetDTCOfEvent
        OIE_EventInfo_Dem_FEE_WRITE_ERROR_GetEventExtendedDataRecord: start-on-event=GetEventExtendedDataRecord, operation=EventInfo_Dem_FEE_WRITE_ERROR.GetEventExtendedDataRecord
        OIE_EventInfo_Dem_FEE_WRITE_ERROR_GetEventFailed: start-on-event=GetEventFailed, operation=EventInfo_Dem_FEE_WRITE_ERROR.GetEventFailed
        OIE_EventInfo_Dem_FEE_WRITE_ERROR_GetEventFreezeFrameData: start-on-event=GetEventFreezeFrameData, operation=EventInfo_Dem_FEE_WRITE_ERROR.GetEventFreezeFrameData
        OIE_EventInfo_Dem_FEE_WRITE_ERROR_GetEventStatus: start-on-event=GetEventStatus, operation=EventInfo_Dem_FEE_WRITE_ERROR.GetEventStatus
        OIE_EventInfo_Dem_FEE_WRITE_ERROR_GetEventTested: start-on-event=GetEventTested, operation=EventInfo_Dem_FEE_WRITE_ERROR.GetEventTested
        OIE_EventInfo_Dem_FEE_WRITE_ERROR_GetFaultDetectionCounter: start-on-event=GetFaultDetectionCounter, operation=EventInfo_Dem_FEE_WRITE_ERROR.GetFaultDetectionCounter
        OIE_EventInfo_Dem_FLS_COMPARE_ERROR_GetDTCOfEvent: start-on-event=GetDTCOfEvent, operation=EventInfo_Dem_FLS_COMPARE_ERROR.GetDTCOfEvent
        OIE_EventInfo_Dem_FLS_COMPARE_ERROR_GetEventExtendedDataRecord: start-on-event=GetEventExtendedDataRecord, operation=EventInfo_Dem_FLS_COMPARE_ERROR.GetEventExtendedDataRecord
        OIE_EventInfo_Dem_FLS_COMPARE_ERROR_GetEventFailed: start-on-event=GetEventFailed, operation=EventInfo_Dem_FLS_COMPARE_ERROR.GetEventFailed
        OIE_EventInfo_Dem_FLS_COMPARE_ERROR_GetEventFreezeFrameData: start-on-event=GetEventFreezeFrameData, operation=EventInfo_Dem_FLS_COMPARE_ERROR.GetEventFreezeFrameData
        OIE_EventInfo_Dem_FLS_COMPARE_ERROR_GetEventStatus: start-on-event=GetEventStatus, operation=EventInfo_Dem_FLS_COMPARE_ERROR.GetEventStatus
        OIE_EventInfo_Dem_FLS_COMPARE_ERROR_GetEventTested: start-on-event=GetEventTested, operation=EventInfo_Dem_FLS_COMPARE_ERROR.GetEventTested
        OIE_EventInfo_Dem_FLS_COMPARE_ERROR_GetFaultDetectionCounter: start-on-event=GetFaultDetectionCounter, operation=EventInfo_Dem_FLS_COMPARE_ERROR.GetFaultDetectionCounter
        OIE_EventInfo_Dem_FLS_ERASE_ERROR_GetDTCOfEvent: start-on-event=GetDTCOfEvent, operation=EventInfo_Dem_FLS_ERASE_ERROR.GetDTCOfEvent
        OIE_EventInfo_Dem_FLS_ERASE_ERROR_GetEventExtendedDataRecord: start-on-event=GetEventExtendedDataRecord, operation=EventInfo_Dem_FLS_ERASE_ERROR.GetEventExtendedDataRecord
        OIE_EventInfo_Dem_FLS_ERASE_ERROR_GetEventFailed: start-on-event=GetEventFailed, operation=EventInfo_Dem_FLS_ERASE_ERROR.GetEventFailed
        OIE_EventInfo_Dem_FLS_ERASE_ERROR_GetEventFreezeFrameData: start-on-event=GetEventFreezeFrameData, operation=EventInfo_Dem_FLS_ERASE_ERROR.GetEventFreezeFrameData
        OIE_EventInfo_Dem_FLS_ERASE_ERROR_GetEventStatus: start-on-event=GetEventStatus, operation=EventInfo_Dem_FLS_ERASE_ERROR.GetEventStatus
        OIE_EventInfo_Dem_FLS_ERASE_ERROR_GetEventTested: start-on-event=GetEventTested, operation=EventInfo_Dem_FLS_ERASE_ERROR.GetEventTested
        OIE_EventInfo_Dem_FLS_ERASE_ERROR_GetFaultDetectionCounter: start-on-event=GetFaultDetectionCounter, operation=EventInfo_Dem_FLS_ERASE_ERROR.GetFaultDetectionCounter
        OIE_EventInfo_Dem_FLS_READ_ERROR_GetDTCOfEvent: start-on-event=GetDTCOfEvent, operation=EventInfo_Dem_FLS_READ_ERROR.GetDTCOfEvent
        OIE_EventInfo_Dem_FLS_READ_ERROR_GetEventExtendedDataRecord: start-on-event=GetEventExtendedDataRecord, operation=EventInfo_Dem_FLS_READ_ERROR.GetEventExtendedDataRecord
        OIE_EventInfo_Dem_FLS_READ_ERROR_GetEventFailed: start-on-event=GetEventFailed, operation=EventInfo_Dem_FLS_READ_ERROR.GetEventFailed
        OIE_EventInfo_Dem_FLS_READ_ERROR_GetEventFreezeFrameData: start-on-event=GetEventFreezeFrameData, operation=EventInfo_Dem_FLS_READ_ERROR.GetEventFreezeFrameData
        OIE_EventInfo_Dem_FLS_READ_ERROR_GetEventStatus: start-on-event=GetEventStatus, operation=EventInfo_Dem_FLS_READ_ERROR.GetEventStatus
        OIE_EventInfo_Dem_FLS_READ_ERROR_GetEventTested: start-on-event=GetEventTested, operation=EventInfo_Dem_FLS_READ_ERROR.GetEventTested
        OIE_EventInfo_Dem_FLS_READ_ERROR_GetFaultDetectionCounter: start-on-event=GetFaultDetectionCounter, operation=EventInfo_Dem_FLS_READ_ERROR.GetFaultDetectionCounter
        OIE_EventInfo_Dem_FLS_WRITE_ERROR_GetDTCOfEvent: start-on-event=GetDTCOfEvent, operation=EventInfo_Dem_FLS_WRITE_ERROR.GetDTCOfEvent
        OIE_EventInfo_Dem_FLS_WRITE_ERROR_GetEventExtendedDataRecord: start-on-event=GetEventExtendedDataRecord, operation=EventInfo_Dem_FLS_WRITE_ERROR.GetEventExtendedDataRecord
        OIE_EventInfo_Dem_FLS_WRITE_ERROR_GetEventFailed: start-on-event=GetEventFailed, operation=EventInfo_Dem_FLS_WRITE_ERROR.GetEventFailed
        OIE_EventInfo_Dem_FLS_WRITE_ERROR_GetEventFreezeFrameData: start-on-event=GetEventFreezeFrameData, operation=EventInfo_Dem_FLS_WRITE_ERROR.GetEventFreezeFrameData
        OIE_EventInfo_Dem_FLS_WRITE_ERROR_GetEventStatus: start-on-event=GetEventStatus, operation=EventInfo_Dem_FLS_WRITE_ERROR.GetEventStatus
        OIE_EventInfo_Dem_FLS_WRITE_ERROR_GetEventTested: start-on-event=GetEventTested, operation=EventInfo_Dem_FLS_WRITE_ERROR.GetEventTested
        OIE_EventInfo_Dem_FLS_WRITE_ERROR_GetFaultDetectionCounter: start-on-event=GetFaultDetectionCounter, operation=EventInfo_Dem_FLS_WRITE_ERROR.GetFaultDetectionCounter
        OIE_EventInfo_ECUM_E_CONFIGURATION_DATA_INCONSISTENT_GetDTCOfEvent: start-on-event=GetDTCOfEvent, operation=EventInfo_ECUM_E_CONFIGURATION_DATA_INCONSISTENT.GetDTCOfEvent
        OIE_EventInfo_ECUM_E_CONFIGURATION_DATA_INCONSISTENT_GetEventExtendedDataRecord: start-on-event=GetEventExtendedDataRecord, operation=EventInfo_ECUM_E_CONFIGURATION_DATA_INCONSISTENT.GetEventExtendedDataRecord
        OIE_EventInfo_ECUM_E_CONFIGURATION_DATA_INCONSISTENT_GetEventFailed: start-on-event=GetEventFailed, operation=EventInfo_ECUM_E_CONFIGURATION_DATA_INCONSISTENT.GetEventFailed
        OIE_EventInfo_ECUM_E_CONFIGURATION_DATA_INCONSISTENT_GetEventFreezeFrameData: start-on-event=GetEventFreezeFrameData, operation=EventInfo_ECUM_E_CONFIGURATION_DATA_INCONSISTENT.GetEventFreezeFrameData
        OIE_EventInfo_ECUM_E_CONFIGURATION_DATA_INCONSISTENT_GetEventStatus: start-on-event=GetEventStatus, operation=EventInfo_ECUM_E_CONFIGURATION_DATA_INCONSISTENT.GetEventStatus
        OIE_EventInfo_ECUM_E_CONFIGURATION_DATA_INCONSISTENT_GetEventTested: start-on-event=GetEventTested, operation=EventInfo_ECUM_E_CONFIGURATION_DATA_INCONSISTENT.GetEventTested
        OIE_EventInfo_ECUM_E_CONFIGURATION_DATA_INCONSISTENT_GetFaultDetectionCounter: start-on-event=GetFaultDetectionCounter, operation=EventInfo_ECUM_E_CONFIGURATION_DATA_INCONSISTENT.GetFaultDetectionCounter
        OIE_EventInfo_ECUM_E_IMPROPER_CALLER_GetDTCOfEvent: start-on-event=GetDTCOfEvent, operation=EventInfo_ECUM_E_IMPROPER_CALLER.GetDTCOfEvent
        OIE_EventInfo_ECUM_E_IMPROPER_CALLER_GetEventExtendedDataRecord: start-on-event=GetEventExtendedDataRecord, operation=EventInfo_ECUM_E_IMPROPER_CALLER.GetEventExtendedDataRecord
        OIE_EventInfo_ECUM_E_IMPROPER_CALLER_GetEventFailed: start-on-event=GetEventFailed, operation=EventInfo_ECUM_E_IMPROPER_CALLER.GetEventFailed
        OIE_EventInfo_ECUM_E_IMPROPER_CALLER_GetEventFreezeFrameData: start-on-event=GetEventFreezeFrameData, operation=EventInfo_ECUM_E_IMPROPER_CALLER.GetEventFreezeFrameData
        OIE_EventInfo_ECUM_E_IMPROPER_CALLER_GetEventStatus: start-on-event=GetEventStatus, operation=EventInfo_ECUM_E_IMPROPER_CALLER.GetEventStatus
        OIE_EventInfo_ECUM_E_IMPROPER_CALLER_GetEventTested: start-on-event=GetEventTested, operation=EventInfo_ECUM_E_IMPROPER_CALLER.GetEventTested
        OIE_EventInfo_ECUM_E_IMPROPER_CALLER_GetFaultDetectionCounter: start-on-event=GetFaultDetectionCounter, operation=EventInfo_ECUM_E_IMPROPER_CALLER.GetFaultDetectionCounter
        OIE_EventInfo_ECUM_E_RAM_CHECK_FAILED_GetDTCOfEvent: start-on-event=GetDTCOfEvent, operation=EventInfo_ECUM_E_RAM_CHECK_FAILED.GetDTCOfEvent
        OIE_EventInfo_ECUM_E_RAM_CHECK_FAILED_GetEventExtendedDataRecord: start-on-event=GetEventExtendedDataRecord, operation=EventInfo_ECUM_E_RAM_CHECK_FAILED.GetEventExtendedDataRecord
        OIE_EventInfo_ECUM_E_RAM_CHECK_FAILED_GetEventFailed: start-on-event=GetEventFailed, operation=EventInfo_ECUM_E_RAM_CHECK_FAILED.GetEventFailed
        OIE_EventInfo_ECUM_E_RAM_CHECK_FAILED_GetEventFreezeFrameData: start-on-event=GetEventFreezeFrameData, operation=EventInfo_ECUM_E_RAM_CHECK_FAILED.GetEventFreezeFrameData
        OIE_EventInfo_ECUM_E_RAM_CHECK_FAILED_GetEventStatus: start-on-event=GetEventStatus, operation=EventInfo_ECUM_E_RAM_CHECK_FAILED.GetEventStatus
        OIE_EventInfo_ECUM_E_RAM_CHECK_FAILED_GetEventTested: start-on-event=GetEventTested, operation=EventInfo_ECUM_E_RAM_CHECK_FAILED.GetEventTested
        OIE_EventInfo_ECUM_E_RAM_CHECK_FAILED_GetFaultDetectionCounter: start-on-event=GetFaultDetectionCounter, operation=EventInfo_ECUM_E_RAM_CHECK_FAILED.GetFaultDetectionCounter
        OIE_EventInfo_EEP_E_COMPARE_FAILED_GetDTCOfEvent: start-on-event=GetDTCOfEvent, operation=EventInfo_EEP_E_COMPARE_FAILED.GetDTCOfEvent
        OIE_EventInfo_EEP_E_COMPARE_FAILED_GetEventExtendedDataRecord: start-on-event=GetEventExtendedDataRecord, operation=EventInfo_EEP_E_COMPARE_FAILED.GetEventExtendedDataRecord
        OIE_EventInfo_EEP_E_COMPARE_FAILED_GetEventFailed: start-on-event=GetEventFailed, operation=EventInfo_EEP_E_COMPARE_FAILED.GetEventFailed
        OIE_EventInfo_EEP_E_COMPARE_FAILED_GetEventFreezeFrameData: start-on-event=GetEventFreezeFrameData, operation=EventInfo_EEP_E_COMPARE_FAILED.GetEventFreezeFrameData
        OIE_EventInfo_EEP_E_COMPARE_FAILED_GetEventStatus: start-on-event=GetEventStatus, operation=EventInfo_EEP_E_COMPARE_FAILED.GetEventStatus
        OIE_EventInfo_EEP_E_COMPARE_FAILED_GetEventTested: start-on-event=GetEventTested, operation=EventInfo_EEP_E_COMPARE_FAILED.GetEventTested
        OIE_EventInfo_EEP_E_COMPARE_FAILED_GetFaultDetectionCounter: start-on-event=GetFaultDetectionCounter, operation=EventInfo_EEP_E_COMPARE_FAILED.GetFaultDetectionCounter
        OIE_EventInfo_EEP_E_ERASE_FAILED_GetDTCOfEvent: start-on-event=GetDTCOfEvent, operation=EventInfo_EEP_E_ERASE_FAILED.GetDTCOfEvent
        OIE_EventInfo_EEP_E_ERASE_FAILED_GetEventExtendedDataRecord: start-on-event=GetEventExtendedDataRecord, operation=EventInfo_EEP_E_ERASE_FAILED.GetEventExtendedDataRecord
        OIE_EventInfo_EEP_E_ERASE_FAILED_GetEventFailed: start-on-event=GetEventFailed, operation=EventInfo_EEP_E_ERASE_FAILED.GetEventFailed
        OIE_EventInfo_EEP_E_ERASE_FAILED_GetEventFreezeFrameData: start-on-event=GetEventFreezeFrameData, operation=EventInfo_EEP_E_ERASE_FAILED.GetEventFreezeFrameData
        OIE_EventInfo_EEP_E_ERASE_FAILED_GetEventStatus: start-on-event=GetEventStatus, operation=EventInfo_EEP_E_ERASE_FAILED.GetEventStatus
        OIE_EventInfo_EEP_E_ERASE_FAILED_GetEventTested: start-on-event=GetEventTested, operation=EventInfo_EEP_E_ERASE_FAILED.GetEventTested
        OIE_EventInfo_EEP_E_ERASE_FAILED_GetFaultDetectionCounter: start-on-event=GetFaultDetectionCounter, operation=EventInfo_EEP_E_ERASE_FAILED.GetFaultDetectionCounter
        OIE_EventInfo_EEP_E_READ_FAILED_GetDTCOfEvent: start-on-event=GetDTCOfEvent, operation=EventInfo_EEP_E_READ_FAILED.GetDTCOfEvent
        OIE_EventInfo_EEP_E_READ_FAILED_GetEventExtendedDataRecord: start-on-event=GetEventExtendedDataRecord, operation=EventInfo_EEP_E_READ_FAILED.GetEventExtendedDataRecord
        OIE_EventInfo_EEP_E_READ_FAILED_GetEventFailed: start-on-event=GetEventFailed, operation=EventInfo_EEP_E_READ_FAILED.GetEventFailed
        OIE_EventInfo_EEP_E_READ_FAILED_GetEventFreezeFrameData: start-on-event=GetEventFreezeFrameData, operation=EventInfo_EEP_E_READ_FAILED.GetEventFreezeFrameData
        OIE_EventInfo_EEP_E_READ_FAILED_GetEventStatus: start-on-event=GetEventStatus, operation=EventInfo_EEP_E_READ_FAILED.GetEventStatus
        OIE_EventInfo_EEP_E_READ_FAILED_GetEventTested: start-on-event=GetEventTested, operation=EventInfo_EEP_E_READ_FAILED.GetEventTested
        OIE_EventInfo_EEP_E_READ_FAILED_GetFaultDetectionCounter: start-on-event=GetFaultDetectionCounter, operation=EventInfo_EEP_E_READ_FAILED.GetFaultDetectionCounter
        OIE_EventInfo_EEP_E_WRITE_FAILED_GetDTCOfEvent: start-on-event=GetDTCOfEvent, operation=EventInfo_EEP_E_WRITE_FAILED.GetDTCOfEvent
        OIE_EventInfo_EEP_E_WRITE_FAILED_GetEventExtendedDataRecord: start-on-event=GetEventExtendedDataRecord, operation=EventInfo_EEP_E_WRITE_FAILED.GetEventExtendedDataRecord
        OIE_EventInfo_EEP_E_WRITE_FAILED_GetEventFailed: start-on-event=GetEventFailed, operation=EventInfo_EEP_E_WRITE_FAILED.GetEventFailed
        OIE_EventInfo_EEP_E_WRITE_FAILED_GetEventFreezeFrameData: start-on-event=GetEventFreezeFrameData, operation=EventInfo_EEP_E_WRITE_FAILED.GetEventFreezeFrameData
        OIE_EventInfo_EEP_E_WRITE_FAILED_GetEventStatus: start-on-event=GetEventStatus, operation=EventInfo_EEP_E_WRITE_FAILED.GetEventStatus
        OIE_EventInfo_EEP_E_WRITE_FAILED_GetEventTested: start-on-event=GetEventTested, operation=EventInfo_EEP_E_WRITE_FAILED.GetEventTested
        OIE_EventInfo_EEP_E_WRITE_FAILED_GetFaultDetectionCounter: start-on-event=GetFaultDetectionCounter, operation=EventInfo_EEP_E_WRITE_FAILED.GetFaultDetectionCounter
        OIE_EventInfo_ETHSM_E_LINK_DOWN_GetDTCOfEvent: start-on-event=GetDTCOfEvent, operation=EventInfo_ETHSM_E_LINK_DOWN.GetDTCOfEvent
        OIE_EventInfo_ETHSM_E_LINK_DOWN_GetEventExtendedDataRecord: start-on-event=GetEventExtendedDataRecord, operation=EventInfo_ETHSM_E_LINK_DOWN.GetEventExtendedDataRecord
        OIE_EventInfo_ETHSM_E_LINK_DOWN_GetEventFailed: start-on-event=GetEventFailed, operation=EventInfo_ETHSM_E_LINK_DOWN.GetEventFailed
        OIE_EventInfo_ETHSM_E_LINK_DOWN_GetEventFreezeFrameData: start-on-event=GetEventFreezeFrameData, operation=EventInfo_ETHSM_E_LINK_DOWN.GetEventFreezeFrameData
        OIE_EventInfo_ETHSM_E_LINK_DOWN_GetEventStatus: start-on-event=GetEventStatus, operation=EventInfo_ETHSM_E_LINK_DOWN.GetEventStatus
        OIE_EventInfo_ETHSM_E_LINK_DOWN_GetEventTested: start-on-event=GetEventTested, operation=EventInfo_ETHSM_E_LINK_DOWN.GetEventTested
        OIE_EventInfo_ETHSM_E_LINK_DOWN_GetFaultDetectionCounter: start-on-event=GetFaultDetectionCounter, operation=EventInfo_ETHSM_E_LINK_DOWN.GetFaultDetectionCounter
        OIE_EventInfo_ETHTRCV_E_ACCESS_GetDTCOfEvent: start-on-event=GetDTCOfEvent, operation=EventInfo_ETHTRCV_E_ACCESS.GetDTCOfEvent
        OIE_EventInfo_ETHTRCV_E_ACCESS_GetEventExtendedDataRecord: start-on-event=GetEventExtendedDataRecord, operation=EventInfo_ETHTRCV_E_ACCESS.GetEventExtendedDataRecord
        OIE_EventInfo_ETHTRCV_E_ACCESS_GetEventFailed: start-on-event=GetEventFailed, operation=EventInfo_ETHTRCV_E_ACCESS.GetEventFailed
        OIE_EventInfo_ETHTRCV_E_ACCESS_GetEventFreezeFrameData: start-on-event=GetEventFreezeFrameData, operation=EventInfo_ETHTRCV_E_ACCESS.GetEventFreezeFrameData
        OIE_EventInfo_ETHTRCV_E_ACCESS_GetEventStatus: start-on-event=GetEventStatus, operation=EventInfo_ETHTRCV_E_ACCESS.GetEventStatus
        OIE_EventInfo_ETHTRCV_E_ACCESS_GetEventTested: start-on-event=GetEventTested, operation=EventInfo_ETHTRCV_E_ACCESS.GetEventTested
        OIE_EventInfo_ETHTRCV_E_ACCESS_GetFaultDetectionCounter: start-on-event=GetFaultDetectionCounter, operation=EventInfo_ETHTRCV_E_ACCESS.GetFaultDetectionCounter
        OIE_EventInfo_ETH_E_ACCESS_GetDTCOfEvent: start-on-event=GetDTCOfEvent, operation=EventInfo_ETH_E_ACCESS.GetDTCOfEvent
        OIE_EventInfo_ETH_E_ACCESS_GetEventExtendedDataRecord: start-on-event=GetEventExtendedDataRecord, operation=EventInfo_ETH_E_ACCESS.GetEventExtendedDataRecord
        OIE_EventInfo_ETH_E_ACCESS_GetEventFailed: start-on-event=GetEventFailed, operation=EventInfo_ETH_E_ACCESS.GetEventFailed
        OIE_EventInfo_ETH_E_ACCESS_GetEventFreezeFrameData: start-on-event=GetEventFreezeFrameData, operation=EventInfo_ETH_E_ACCESS.GetEventFreezeFrameData
        OIE_EventInfo_ETH_E_ACCESS_GetEventStatus: start-on-event=GetEventStatus, operation=EventInfo_ETH_E_ACCESS.GetEventStatus
        OIE_EventInfo_ETH_E_ACCESS_GetEventTested: start-on-event=GetEventTested, operation=EventInfo_ETH_E_ACCESS.GetEventTested
        OIE_EventInfo_ETH_E_ACCESS_GetFaultDetectionCounter: start-on-event=GetFaultDetectionCounter, operation=EventInfo_ETH_E_ACCESS.GetFaultDetectionCounter
        OIE_EventInfo_FLS_E_COMPARE_FAILED_GetDTCOfEvent: start-on-event=GetDTCOfEvent, operation=EventInfo_FLS_E_COMPARE_FAILED.GetDTCOfEvent
        OIE_EventInfo_FLS_E_COMPARE_FAILED_GetEventExtendedDataRecord: start-on-event=GetEventExtendedDataRecord, operation=EventInfo_FLS_E_COMPARE_FAILED.GetEventExtendedDataRecord
        OIE_EventInfo_FLS_E_COMPARE_FAILED_GetEventFailed: start-on-event=GetEventFailed, operation=EventInfo_FLS_E_COMPARE_FAILED.GetEventFailed
        OIE_EventInfo_FLS_E_COMPARE_FAILED_GetEventFreezeFrameData: start-on-event=GetEventFreezeFrameData, operation=EventInfo_FLS_E_COMPARE_FAILED.GetEventFreezeFrameData
        OIE_EventInfo_FLS_E_COMPARE_FAILED_GetEventStatus: start-on-event=GetEventStatus, operation=EventInfo_FLS_E_COMPARE_FAILED.GetEventStatus
        OIE_EventInfo_FLS_E_COMPARE_FAILED_GetEventTested: start-on-event=GetEventTested, operation=EventInfo_FLS_E_COMPARE_FAILED.GetEventTested
        OIE_EventInfo_FLS_E_COMPARE_FAILED_GetFaultDetectionCounter: start-on-event=GetFaultDetectionCounter, operation=EventInfo_FLS_E_COMPARE_FAILED.GetFaultDetectionCounter
        OIE_EventInfo_FLS_E_ERASE_FAILED_GetDTCOfEvent: start-on-event=GetDTCOfEvent, operation=EventInfo_FLS_E_ERASE_FAILED.GetDTCOfEvent
        OIE_EventInfo_FLS_E_ERASE_FAILED_GetEventExtendedDataRecord: start-on-event=GetEventExtendedDataRecord, operation=EventInfo_FLS_E_ERASE_FAILED.GetEventExtendedDataRecord
        OIE_EventInfo_FLS_E_ERASE_FAILED_GetEventFailed: start-on-event=GetEventFailed, operation=EventInfo_FLS_E_ERASE_FAILED.GetEventFailed
        OIE_EventInfo_FLS_E_ERASE_FAILED_GetEventFreezeFrameData: start-on-event=GetEventFreezeFrameData, operation=EventInfo_FLS_E_ERASE_FAILED.GetEventFreezeFrameData
        OIE_EventInfo_FLS_E_ERASE_FAILED_GetEventStatus: start-on-event=GetEventStatus, operation=EventInfo_FLS_E_ERASE_FAILED.GetEventStatus
        OIE_EventInfo_FLS_E_ERASE_FAILED_GetEventTested: start-on-event=GetEventTested, operation=EventInfo_FLS_E_ERASE_FAILED.GetEventTested
        OIE_EventInfo_FLS_E_ERASE_FAILED_GetFaultDetectionCounter: start-on-event=GetFaultDetectionCounter, operation=EventInfo_FLS_E_ERASE_FAILED.GetFaultDetectionCounter
        OIE_EventInfo_FLS_E_READ_FAILED_GetDTCOfEvent: start-on-event=GetDTCOfEvent, operation=EventInfo_FLS_E_READ_FAILED.GetDTCOfEvent
        OIE_EventInfo_FLS_E_READ_FAILED_GetEventExtendedDataRecord: start-on-event=GetEventExtendedDataRecord, operation=EventInfo_FLS_E_READ_FAILED.GetEventExtendedDataRecord
        OIE_EventInfo_FLS_E_READ_FAILED_GetEventFailed: start-on-event=GetEventFailed, operation=EventInfo_FLS_E_READ_FAILED.GetEventFailed
        OIE_EventInfo_FLS_E_READ_FAILED_GetEventFreezeFrameData: start-on-event=GetEventFreezeFrameData, operation=EventInfo_FLS_E_READ_FAILED.GetEventFreezeFrameData
        OIE_EventInfo_FLS_E_READ_FAILED_GetEventStatus: start-on-event=GetEventStatus, operation=EventInfo_FLS_E_READ_FAILED.GetEventStatus
        OIE_EventInfo_FLS_E_READ_FAILED_GetEventTested: start-on-event=GetEventTested, operation=EventInfo_FLS_E_READ_FAILED.GetEventTested
        OIE_EventInfo_FLS_E_READ_FAILED_GetFaultDetectionCounter: start-on-event=GetFaultDetectionCounter, operation=EventInfo_FLS_E_READ_FAILED.GetFaultDetectionCounter
        OIE_EventInfo_FLS_E_UNEXPECTED_FLASH_ID_GetDTCOfEvent: start-on-event=GetDTCOfEvent, operation=EventInfo_FLS_E_UNEXPECTED_FLASH_ID.GetDTCOfEvent
        OIE_EventInfo_FLS_E_UNEXPECTED_FLASH_ID_GetEventExtendedDataRecord: start-on-event=GetEventExtendedDataRecord, operation=EventInfo_FLS_E_UNEXPECTED_FLASH_ID.GetEventExtendedDataRecord
        OIE_EventInfo_FLS_E_UNEXPECTED_FLASH_ID_GetEventFailed: start-on-event=GetEventFailed, operation=EventInfo_FLS_E_UNEXPECTED_FLASH_ID.GetEventFailed
        OIE_EventInfo_FLS_E_UNEXPECTED_FLASH_ID_GetEventFreezeFrameData: start-on-event=GetEventFreezeFrameData, operation=EventInfo_FLS_E_UNEXPECTED_FLASH_ID.GetEventFreezeFrameData
        OIE_EventInfo_FLS_E_UNEXPECTED_FLASH_ID_GetEventStatus: start-on-event=GetEventStatus, operation=EventInfo_FLS_E_UNEXPECTED_FLASH_ID.GetEventStatus
        OIE_EventInfo_FLS_E_UNEXPECTED_FLASH_ID_GetEventTested: start-on-event=GetEventTested, operation=EventInfo_FLS_E_UNEXPECTED_FLASH_ID.GetEventTested
        OIE_EventInfo_FLS_E_UNEXPECTED_FLASH_ID_GetFaultDetectionCounter: start-on-event=GetFaultDetectionCounter, operation=EventInfo_FLS_E_UNEXPECTED_FLASH_ID.GetFaultDetectionCounter
        OIE_EventInfo_FLS_E_WRITE_FAILED_GetDTCOfEvent: start-on-event=GetDTCOfEvent, operation=EventInfo_FLS_E_WRITE_FAILED.GetDTCOfEvent
        OIE_EventInfo_FLS_E_WRITE_FAILED_GetEventExtendedDataRecord: start-on-event=GetEventExtendedDataRecord, operation=EventInfo_FLS_E_WRITE_FAILED.GetEventExtendedDataRecord
        OIE_EventInfo_FLS_E_WRITE_FAILED_GetEventFailed: start-on-event=GetEventFailed, operation=EventInfo_FLS_E_WRITE_FAILED.GetEventFailed
        OIE_EventInfo_FLS_E_WRITE_FAILED_GetEventFreezeFrameData: start-on-event=GetEventFreezeFrameData, operation=EventInfo_FLS_E_WRITE_FAILED.GetEventFreezeFrameData
        OIE_EventInfo_FLS_E_WRITE_FAILED_GetEventStatus: start-on-event=GetEventStatus, operation=EventInfo_FLS_E_WRITE_FAILED.GetEventStatus
        OIE_EventInfo_FLS_E_WRITE_FAILED_GetEventTested: start-on-event=GetEventTested, operation=EventInfo_FLS_E_WRITE_FAILED.GetEventTested
        OIE_EventInfo_FLS_E_WRITE_FAILED_GetFaultDetectionCounter: start-on-event=GetFaultDetectionCounter, operation=EventInfo_FLS_E_WRITE_FAILED.GetFaultDetectionCounter
        OIE_EventInfo_FR_E_ACCESS_GetDTCOfEvent: start-on-event=GetDTCOfEvent, operation=EventInfo_FR_E_ACCESS.GetDTCOfEvent
        OIE_EventInfo_FR_E_ACCESS_GetEventExtendedDataRecord: start-on-event=GetEventExtendedDataRecord, operation=EventInfo_FR_E_ACCESS.GetEventExtendedDataRecord
        OIE_EventInfo_FR_E_ACCESS_GetEventFailed: start-on-event=GetEventFailed, operation=EventInfo_FR_E_ACCESS.GetEventFailed
        OIE_EventInfo_FR_E_ACCESS_GetEventFreezeFrameData: start-on-event=GetEventFreezeFrameData, operation=EventInfo_FR_E_ACCESS.GetEventFreezeFrameData
        OIE_EventInfo_FR_E_ACCESS_GetEventStatus: start-on-event=GetEventStatus, operation=EventInfo_FR_E_ACCESS.GetEventStatus
        OIE_EventInfo_FR_E_ACCESS_GetEventTested: start-on-event=GetEventTested, operation=EventInfo_FR_E_ACCESS.GetEventTested
        OIE_EventInfo_FR_E_ACCESS_GetFaultDetectionCounter: start-on-event=GetFaultDetectionCounter, operation=EventInfo_FR_E_ACCESS.GetFaultDetectionCounter
        OIE_EventInfo_IOHWAB_E_BUSY_GetDTCOfEvent: start-on-event=GetDTCOfEvent, operation=EventInfo_IOHWAB_E_BUSY.GetDTCOfEvent
        OIE_EventInfo_IOHWAB_E_BUSY_GetEventExtendedDataRecord: start-on-event=GetEventExtendedDataRecord, operation=EventInfo_IOHWAB_E_BUSY.GetEventExtendedDataRecord
        OIE_EventInfo_IOHWAB_E_BUSY_GetEventFailed: start-on-event=GetEventFailed, operation=EventInfo_IOHWAB_E_BUSY.GetEventFailed
        OIE_EventInfo_IOHWAB_E_BUSY_GetEventFreezeFrameData: start-on-event=GetEventFreezeFrameData, operation=EventInfo_IOHWAB_E_BUSY.GetEventFreezeFrameData
        OIE_EventInfo_IOHWAB_E_BUSY_GetEventStatus: start-on-event=GetEventStatus, operation=EventInfo_IOHWAB_E_BUSY.GetEventStatus
        OIE_EventInfo_IOHWAB_E_BUSY_GetEventTested: start-on-event=GetEventTested, operation=EventInfo_IOHWAB_E_BUSY.GetEventTested
        OIE_EventInfo_IOHWAB_E_BUSY_GetFaultDetectionCounter: start-on-event=GetFaultDetectionCounter, operation=EventInfo_IOHWAB_E_BUSY.GetFaultDetectionCounter
        OIE_EventInfo_IOHWAB_E_PROC_FAIL_GetDTCOfEvent: start-on-event=GetDTCOfEvent, operation=EventInfo_IOHWAB_E_PROC_FAIL.GetDTCOfEvent
        OIE_EventInfo_IOHWAB_E_PROC_FAIL_GetEventExtendedDataRecord: start-on-event=GetEventExtendedDataRecord, operation=EventInfo_IOHWAB_E_PROC_FAIL.GetEventExtendedDataRecord
        OIE_EventInfo_IOHWAB_E_PROC_FAIL_GetEventFailed: start-on-event=GetEventFailed, operation=EventInfo_IOHWAB_E_PROC_FAIL.GetEventFailed
        OIE_EventInfo_IOHWAB_E_PROC_FAIL_GetEventFreezeFrameData: start-on-event=GetEventFreezeFrameData, operation=EventInfo_IOHWAB_E_PROC_FAIL.GetEventFreezeFrameData
        OIE_EventInfo_IOHWAB_E_PROC_FAIL_GetEventStatus: start-on-event=GetEventStatus, operation=EventInfo_IOHWAB_E_PROC_FAIL.GetEventStatus
        OIE_EventInfo_IOHWAB_E_PROC_FAIL_GetEventTested: start-on-event=GetEventTested, operation=EventInfo_IOHWAB_E_PROC_FAIL.GetEventTested
        OIE_EventInfo_IOHWAB_E_PROC_FAIL_GetFaultDetectionCounter: start-on-event=GetFaultDetectionCounter, operation=EventInfo_IOHWAB_E_PROC_FAIL.GetFaultDetectionCounter
        OIE_EventInfo_IOHWAB_E_SETUP_FAIL_GetDTCOfEvent: start-on-event=GetDTCOfEvent, operation=EventInfo_IOHWAB_E_SETUP_FAIL.GetDTCOfEvent
        OIE_EventInfo_IOHWAB_E_SETUP_FAIL_GetEventExtendedDataRecord: start-on-event=GetEventExtendedDataRecord, operation=EventInfo_IOHWAB_E_SETUP_FAIL.GetEventExtendedDataRecord
        OIE_EventInfo_IOHWAB_E_SETUP_FAIL_GetEventFailed: start-on-event=GetEventFailed, operation=EventInfo_IOHWAB_E_SETUP_FAIL.GetEventFailed
        OIE_EventInfo_IOHWAB_E_SETUP_FAIL_GetEventFreezeFrameData: start-on-event=GetEventFreezeFrameData, operation=EventInfo_IOHWAB_E_SETUP_FAIL.GetEventFreezeFrameData
        OIE_EventInfo_IOHWAB_E_SETUP_FAIL_GetEventStatus: start-on-event=GetEventStatus, operation=EventInfo_IOHWAB_E_SETUP_FAIL.GetEventStatus
        OIE_EventInfo_IOHWAB_E_SETUP_FAIL_GetEventTested: start-on-event=GetEventTested, operation=EventInfo_IOHWAB_E_SETUP_FAIL.GetEventTested
        OIE_EventInfo_IOHWAB_E_SETUP_FAIL_GetFaultDetectionCounter: start-on-event=GetFaultDetectionCounter, operation=EventInfo_IOHWAB_E_SETUP_FAIL.GetFaultDetectionCounter
        OIE_EventInfo_IOHWAB_E_WRONG_PARAM_GetDTCOfEvent: start-on-event=GetDTCOfEvent, operation=EventInfo_IOHWAB_E_WRONG_PARAM.GetDTCOfEvent
        OIE_EventInfo_IOHWAB_E_WRONG_PARAM_GetEventExtendedDataRecord: start-on-event=GetEventExtendedDataRecord, operation=EventInfo_IOHWAB_E_WRONG_PARAM.GetEventExtendedDataRecord
        OIE_EventInfo_IOHWAB_E_WRONG_PARAM_GetEventFailed: start-on-event=GetEventFailed, operation=EventInfo_IOHWAB_E_WRONG_PARAM.GetEventFailed
        OIE_EventInfo_IOHWAB_E_WRONG_PARAM_GetEventFreezeFrameData: start-on-event=GetEventFreezeFrameData, operation=EventInfo_IOHWAB_E_WRONG_PARAM.GetEventFreezeFrameData
        OIE_EventInfo_IOHWAB_E_WRONG_PARAM_GetEventStatus: start-on-event=GetEventStatus, operation=EventInfo_IOHWAB_E_WRONG_PARAM.GetEventStatus
        OIE_EventInfo_IOHWAB_E_WRONG_PARAM_GetEventTested: start-on-event=GetEventTested, operation=EventInfo_IOHWAB_E_WRONG_PARAM.GetEventTested
        OIE_EventInfo_IOHWAB_E_WRONG_PARAM_GetFaultDetectionCounter: start-on-event=GetFaultDetectionCounter, operation=EventInfo_IOHWAB_E_WRONG_PARAM.GetFaultDetectionCounter
        OIE_EventInfo_IOHWAB_E_WRONG_SETTING_GetDTCOfEvent: start-on-event=GetDTCOfEvent, operation=EventInfo_IOHWAB_E_WRONG_SETTING.GetDTCOfEvent
        OIE_EventInfo_IOHWAB_E_WRONG_SETTING_GetEventExtendedDataRecord: start-on-event=GetEventExtendedDataRecord, operation=EventInfo_IOHWAB_E_WRONG_SETTING.GetEventExtendedDataRecord
        OIE_EventInfo_IOHWAB_E_WRONG_SETTING_GetEventFailed: start-on-event=GetEventFailed, operation=EventInfo_IOHWAB_E_WRONG_SETTING.GetEventFailed
        OIE_EventInfo_IOHWAB_E_WRONG_SETTING_GetEventFreezeFrameData: start-on-event=GetEventFreezeFrameData, operation=EventInfo_IOHWAB_E_WRONG_SETTING.GetEventFreezeFrameData
        OIE_EventInfo_IOHWAB_E_WRONG_SETTING_GetEventStatus: start-on-event=GetEventStatus, operation=EventInfo_IOHWAB_E_WRONG_SETTING.GetEventStatus
        OIE_EventInfo_IOHWAB_E_WRONG_SETTING_GetEventTested: start-on-event=GetEventTested, operation=EventInfo_IOHWAB_E_WRONG_SETTING.GetEventTested
        OIE_EventInfo_IOHWAB_E_WRONG_SETTING_GetFaultDetectionCounter: start-on-event=GetFaultDetectionCounter, operation=EventInfo_IOHWAB_E_WRONG_SETTING.GetFaultDetectionCounter
        OIE_EventInfo_IOHWAB_E_WRONG_STATE_GetDTCOfEvent: start-on-event=GetDTCOfEvent, operation=EventInfo_IOHWAB_E_WRONG_STATE.GetDTCOfEvent
        OIE_EventInfo_IOHWAB_E_WRONG_STATE_GetEventExtendedDataRecord: start-on-event=GetEventExtendedDataRecord, operation=EventInfo_IOHWAB_E_WRONG_STATE.GetEventExtendedDataRecord
        OIE_EventInfo_IOHWAB_E_WRONG_STATE_GetEventFailed: start-on-event=GetEventFailed, operation=EventInfo_IOHWAB_E_WRONG_STATE.GetEventFailed
        OIE_EventInfo_IOHWAB_E_WRONG_STATE_GetEventFreezeFrameData: start-on-event=GetEventFreezeFrameData, operation=EventInfo_IOHWAB_E_WRONG_STATE.GetEventFreezeFrameData
        OIE_EventInfo_IOHWAB_E_WRONG_STATE_GetEventStatus: start-on-event=GetEventStatus, operation=EventInfo_IOHWAB_E_WRONG_STATE.GetEventStatus
        OIE_EventInfo_IOHWAB_E_WRONG_STATE_GetEventTested: start-on-event=GetEventTested, operation=EventInfo_IOHWAB_E_WRONG_STATE.GetEventTested
        OIE_EventInfo_IOHWAB_E_WRONG_STATE_GetFaultDetectionCounter: start-on-event=GetFaultDetectionCounter, operation=EventInfo_IOHWAB_E_WRONG_STATE.GetFaultDetectionCounter
        OIE_EventInfo_LIN_E_TIMEOUT_GetDTCOfEvent: start-on-event=GetDTCOfEvent, operation=EventInfo_LIN_E_TIMEOUT.GetDTCOfEvent
        OIE_EventInfo_LIN_E_TIMEOUT_GetEventExtendedDataRecord: start-on-event=GetEventExtendedDataRecord, operation=EventInfo_LIN_E_TIMEOUT.GetEventExtendedDataRecord
        OIE_EventInfo_LIN_E_TIMEOUT_GetEventFailed: start-on-event=GetEventFailed, operation=EventInfo_LIN_E_TIMEOUT.GetEventFailed
        OIE_EventInfo_LIN_E_TIMEOUT_GetEventFreezeFrameData: start-on-event=GetEventFreezeFrameData, operation=EventInfo_LIN_E_TIMEOUT.GetEventFreezeFrameData
        OIE_EventInfo_LIN_E_TIMEOUT_GetEventStatus: start-on-event=GetEventStatus, operation=EventInfo_LIN_E_TIMEOUT.GetEventStatus
        OIE_EventInfo_LIN_E_TIMEOUT_GetEventTested: start-on-event=GetEventTested, operation=EventInfo_LIN_E_TIMEOUT.GetEventTested
        OIE_EventInfo_LIN_E_TIMEOUT_GetFaultDetectionCounter: start-on-event=GetFaultDetectionCounter, operation=EventInfo_LIN_E_TIMEOUT.GetFaultDetectionCounter
        OIE_EventInfo_MCU_E_CLOCK_FAILURE_GetDTCOfEvent: start-on-event=GetDTCOfEvent, operation=EventInfo_MCU_E_CLOCK_FAILURE.GetDTCOfEvent
        OIE_EventInfo_MCU_E_CLOCK_FAILURE_GetEventExtendedDataRecord: start-on-event=GetEventExtendedDataRecord, operation=EventInfo_MCU_E_CLOCK_FAILURE.GetEventExtendedDataRecord
        OIE_EventInfo_MCU_E_CLOCK_FAILURE_GetEventFailed: start-on-event=GetEventFailed, operation=EventInfo_MCU_E_CLOCK_FAILURE.GetEventFailed
        OIE_EventInfo_MCU_E_CLOCK_FAILURE_GetEventFreezeFrameData: start-on-event=GetEventFreezeFrameData, operation=EventInfo_MCU_E_CLOCK_FAILURE.GetEventFreezeFrameData
        OIE_EventInfo_MCU_E_CLOCK_FAILURE_GetEventStatus: start-on-event=GetEventStatus, operation=EventInfo_MCU_E_CLOCK_FAILURE.GetEventStatus
        OIE_EventInfo_MCU_E_CLOCK_FAILURE_GetEventTested: start-on-event=GetEventTested, operation=EventInfo_MCU_E_CLOCK_FAILURE.GetEventTested
        OIE_EventInfo_MCU_E_CLOCK_FAILURE_GetFaultDetectionCounter: start-on-event=GetFaultDetectionCounter, operation=EventInfo_MCU_E_CLOCK_FAILURE.GetFaultDetectionCounter
        OIE_EventInfo_MCU_E_LOCK_FAILURE_GetDTCOfEvent: start-on-event=GetDTCOfEvent, operation=EventInfo_MCU_E_LOCK_FAILURE.GetDTCOfEvent
        OIE_EventInfo_MCU_E_LOCK_FAILURE_GetEventExtendedDataRecord: start-on-event=GetEventExtendedDataRecord, operation=EventInfo_MCU_E_LOCK_FAILURE.GetEventExtendedDataRecord
        OIE_EventInfo_MCU_E_LOCK_FAILURE_GetEventFailed: start-on-event=GetEventFailed, operation=EventInfo_MCU_E_LOCK_FAILURE.GetEventFailed
        OIE_EventInfo_MCU_E_LOCK_FAILURE_GetEventFreezeFrameData: start-on-event=GetEventFreezeFrameData, operation=EventInfo_MCU_E_LOCK_FAILURE.GetEventFreezeFrameData
        OIE_EventInfo_MCU_E_LOCK_FAILURE_GetEventStatus: start-on-event=GetEventStatus, operation=EventInfo_MCU_E_LOCK_FAILURE.GetEventStatus
        OIE_EventInfo_MCU_E_LOCK_FAILURE_GetEventTested: start-on-event=GetEventTested, operation=EventInfo_MCU_E_LOCK_FAILURE.GetEventTested
        OIE_EventInfo_MCU_E_LOCK_FAILURE_GetFaultDetectionCounter: start-on-event=GetFaultDetectionCounter, operation=EventInfo_MCU_E_LOCK_FAILURE.GetFaultDetectionCounter
        OIE_EventInfo_MCU_E_QUARTZ_FAILURE_GetDTCOfEvent: start-on-event=GetDTCOfEvent, operation=EventInfo_MCU_E_QUARTZ_FAILURE.GetDTCOfEvent
        OIE_EventInfo_MCU_E_QUARTZ_FAILURE_GetEventExtendedDataRecord: start-on-event=GetEventExtendedDataRecord, operation=EventInfo_MCU_E_QUARTZ_FAILURE.GetEventExtendedDataRecord
        OIE_EventInfo_MCU_E_QUARTZ_FAILURE_GetEventFailed: start-on-event=GetEventFailed, operation=EventInfo_MCU_E_QUARTZ_FAILURE.GetEventFailed
        OIE_EventInfo_MCU_E_QUARTZ_FAILURE_GetEventFreezeFrameData: start-on-event=GetEventFreezeFrameData, operation=EventInfo_MCU_E_QUARTZ_FAILURE.GetEventFreezeFrameData
        OIE_EventInfo_MCU_E_QUARTZ_FAILURE_GetEventStatus: start-on-event=GetEventStatus, operation=EventInfo_MCU_E_QUARTZ_FAILURE.GetEventStatus
        OIE_EventInfo_MCU_E_QUARTZ_FAILURE_GetEventTested: start-on-event=GetEventTested, operation=EventInfo_MCU_E_QUARTZ_FAILURE.GetEventTested
        OIE_EventInfo_MCU_E_QUARTZ_FAILURE_GetFaultDetectionCounter: start-on-event=GetFaultDetectionCounter, operation=EventInfo_MCU_E_QUARTZ_FAILURE.GetFaultDetectionCounter
        OIE_EventInfo_MCU_E_TIMEOUT_TRANSITION_GetDTCOfEvent: start-on-event=GetDTCOfEvent, operation=EventInfo_MCU_E_TIMEOUT_TRANSITION.GetDTCOfEvent
        OIE_EventInfo_MCU_E_TIMEOUT_TRANSITION_GetEventExtendedDataRecord: start-on-event=GetEventExtendedDataRecord, operation=EventInfo_MCU_E_TIMEOUT_TRANSITION.GetEventExtendedDataRecord
        OIE_EventInfo_MCU_E_TIMEOUT_TRANSITION_GetEventFailed: start-on-event=GetEventFailed, operation=EventInfo_MCU_E_TIMEOUT_TRANSITION.GetEventFailed
        OIE_EventInfo_MCU_E_TIMEOUT_TRANSITION_GetEventFreezeFrameData: start-on-event=GetEventFreezeFrameData, operation=EventInfo_MCU_E_TIMEOUT_TRANSITION.GetEventFreezeFrameData
        OIE_EventInfo_MCU_E_TIMEOUT_TRANSITION_GetEventStatus: start-on-event=GetEventStatus, operation=EventInfo_MCU_E_TIMEOUT_TRANSITION.GetEventStatus
        OIE_EventInfo_MCU_E_TIMEOUT_TRANSITION_GetEventTested: start-on-event=GetEventTested, operation=EventInfo_MCU_E_TIMEOUT_TRANSITION.GetEventTested
        OIE_EventInfo_MCU_E_TIMEOUT_TRANSITION_GetFaultDetectionCounter: start-on-event=GetFaultDetectionCounter, operation=EventInfo_MCU_E_TIMEOUT_TRANSITION.GetFaultDetectionCounter
        OIE_EventInfo_NVM_E_INTEGRITY_FAILED_GetDTCOfEvent: start-on-event=GetDTCOfEvent, operation=EventInfo_NVM_E_INTEGRITY_FAILED.GetDTCOfEvent
        OIE_EventInfo_NVM_E_INTEGRITY_FAILED_GetEventExtendedDataRecord: start-on-event=GetEventExtendedDataRecord, operation=EventInfo_NVM_E_INTEGRITY_FAILED.GetEventExtendedDataRecord
        OIE_EventInfo_NVM_E_INTEGRITY_FAILED_GetEventFailed: start-on-event=GetEventFailed, operation=EventInfo_NVM_E_INTEGRITY_FAILED.GetEventFailed
        OIE_EventInfo_NVM_E_INTEGRITY_FAILED_GetEventFreezeFrameData: start-on-event=GetEventFreezeFrameData, operation=EventInfo_NVM_E_INTEGRITY_FAILED.GetEventFreezeFrameData
        OIE_EventInfo_NVM_E_INTEGRITY_FAILED_GetEventStatus: start-on-event=GetEventStatus, operation=EventInfo_NVM_E_INTEGRITY_FAILED.GetEventStatus
        OIE_EventInfo_NVM_E_INTEGRITY_FAILED_GetEventTested: start-on-event=GetEventTested, operation=EventInfo_NVM_E_INTEGRITY_FAILED.GetEventTested
        OIE_EventInfo_NVM_E_INTEGRITY_FAILED_GetFaultDetectionCounter: start-on-event=GetFaultDetectionCounter, operation=EventInfo_NVM_E_INTEGRITY_FAILED.GetFaultDetectionCounter
        OIE_EventInfo_NVM_E_LOSS_OF_REDUNDANCY_GetDTCOfEvent: start-on-event=GetDTCOfEvent, operation=EventInfo_NVM_E_LOSS_OF_REDUNDANCY.GetDTCOfEvent
        OIE_EventInfo_NVM_E_LOSS_OF_REDUNDANCY_GetEventExtendedDataRecord: start-on-event=GetEventExtendedDataRecord, operation=EventInfo_NVM_E_LOSS_OF_REDUNDANCY.GetEventExtendedDataRecord
        OIE_EventInfo_NVM_E_LOSS_OF_REDUNDANCY_GetEventFailed: start-on-event=GetEventFailed, operation=EventInfo_NVM_E_LOSS_OF_REDUNDANCY.GetEventFailed
        OIE_EventInfo_NVM_E_LOSS_OF_REDUNDANCY_GetEventFreezeFrameData: start-on-event=GetEventFreezeFrameData, operation=EventInfo_NVM_E_LOSS_OF_REDUNDANCY.GetEventFreezeFrameData
        OIE_EventInfo_NVM_E_LOSS_OF_REDUNDANCY_GetEventStatus: start-on-event=GetEventStatus, operation=EventInfo_NVM_E_LOSS_OF_REDUNDANCY.GetEventStatus
        OIE_EventInfo_NVM_E_LOSS_OF_REDUNDANCY_GetEventTested: start-on-event=GetEventTested, operation=EventInfo_NVM_E_LOSS_OF_REDUNDANCY.GetEventTested
        OIE_EventInfo_NVM_E_LOSS_OF_REDUNDANCY_GetFaultDetectionCounter: start-on-event=GetFaultDetectionCounter, operation=EventInfo_NVM_E_LOSS_OF_REDUNDANCY.GetFaultDetectionCounter
        OIE_EventInfo_NVM_E_QUEUE_OVERFLOW_GetDTCOfEvent: start-on-event=GetDTCOfEvent, operation=EventInfo_NVM_E_QUEUE_OVERFLOW.GetDTCOfEvent
        OIE_EventInfo_NVM_E_QUEUE_OVERFLOW_GetEventExtendedDataRecord: start-on-event=GetEventExtendedDataRecord, operation=EventInfo_NVM_E_QUEUE_OVERFLOW.GetEventExtendedDataRecord
        OIE_EventInfo_NVM_E_QUEUE_OVERFLOW_GetEventFailed: start-on-event=GetEventFailed, operation=EventInfo_NVM_E_QUEUE_OVERFLOW.GetEventFailed
        OIE_EventInfo_NVM_E_QUEUE_OVERFLOW_GetEventFreezeFrameData: start-on-event=GetEventFreezeFrameData, operation=EventInfo_NVM_E_QUEUE_OVERFLOW.GetEventFreezeFrameData
        OIE_EventInfo_NVM_E_QUEUE_OVERFLOW_GetEventStatus: start-on-event=GetEventStatus, operation=EventInfo_NVM_E_QUEUE_OVERFLOW.GetEventStatus
        OIE_EventInfo_NVM_E_QUEUE_OVERFLOW_GetEventTested: start-on-event=GetEventTested, operation=EventInfo_NVM_E_QUEUE_OVERFLOW.GetEventTested
        OIE_EventInfo_NVM_E_QUEUE_OVERFLOW_GetFaultDetectionCounter: start-on-event=GetFaultDetectionCounter, operation=EventInfo_NVM_E_QUEUE_OVERFLOW.GetFaultDetectionCounter
        OIE_EventInfo_NVM_E_REQ_FAILED_GetDTCOfEvent: start-on-event=GetDTCOfEvent, operation=EventInfo_NVM_E_REQ_FAILED.GetDTCOfEvent
        OIE_EventInfo_NVM_E_REQ_FAILED_GetEventExtendedDataRecord: start-on-event=GetEventExtendedDataRecord, operation=EventInfo_NVM_E_REQ_FAILED.GetEventExtendedDataRecord
        OIE_EventInfo_NVM_E_REQ_FAILED_GetEventFailed: start-on-event=GetEventFailed, operation=EventInfo_NVM_E_REQ_FAILED.GetEventFailed
        OIE_EventInfo_NVM_E_REQ_FAILED_GetEventFreezeFrameData: start-on-event=GetEventFreezeFrameData, operation=EventInfo_NVM_E_REQ_FAILED.GetEventFreezeFrameData
        OIE_EventInfo_NVM_E_REQ_FAILED_GetEventStatus: start-on-event=GetEventStatus, operation=EventInfo_NVM_E_REQ_FAILED.GetEventStatus
        OIE_EventInfo_NVM_E_REQ_FAILED_GetEventTested: start-on-event=GetEventTested, operation=EventInfo_NVM_E_REQ_FAILED.GetEventTested
        OIE_EventInfo_NVM_E_REQ_FAILED_GetFaultDetectionCounter: start-on-event=GetFaultDetectionCounter, operation=EventInfo_NVM_E_REQ_FAILED.GetFaultDetectionCounter
        OIE_EventInfo_NVM_E_VERIFY_FAILED_GetDTCOfEvent: start-on-event=GetDTCOfEvent, operation=EventInfo_NVM_E_VERIFY_FAILED.GetDTCOfEvent
        OIE_EventInfo_NVM_E_VERIFY_FAILED_GetEventExtendedDataRecord: start-on-event=GetEventExtendedDataRecord, operation=EventInfo_NVM_E_VERIFY_FAILED.GetEventExtendedDataRecord
        OIE_EventInfo_NVM_E_VERIFY_FAILED_GetEventFailed: start-on-event=GetEventFailed, operation=EventInfo_NVM_E_VERIFY_FAILED.GetEventFailed
        OIE_EventInfo_NVM_E_VERIFY_FAILED_GetEventFreezeFrameData: start-on-event=GetEventFreezeFrameData, operation=EventInfo_NVM_E_VERIFY_FAILED.GetEventFreezeFrameData
        OIE_EventInfo_NVM_E_VERIFY_FAILED_GetEventStatus: start-on-event=GetEventStatus, operation=EventInfo_NVM_E_VERIFY_FAILED.GetEventStatus
        OIE_EventInfo_NVM_E_VERIFY_FAILED_GetEventTested: start-on-event=GetEventTested, operation=EventInfo_NVM_E_VERIFY_FAILED.GetEventTested
        OIE_EventInfo_NVM_E_VERIFY_FAILED_GetFaultDetectionCounter: start-on-event=GetFaultDetectionCounter, operation=EventInfo_NVM_E_VERIFY_FAILED.GetFaultDetectionCounter
        OIE_EventInfo_NVM_E_WRITE_PROTECTED_GetDTCOfEvent: start-on-event=GetDTCOfEvent, operation=EventInfo_NVM_E_WRITE_PROTECTED.GetDTCOfEvent
        OIE_EventInfo_NVM_E_WRITE_PROTECTED_GetEventExtendedDataRecord: start-on-event=GetEventExtendedDataRecord, operation=EventInfo_NVM_E_WRITE_PROTECTED.GetEventExtendedDataRecord
        OIE_EventInfo_NVM_E_WRITE_PROTECTED_GetEventFailed: start-on-event=GetEventFailed, operation=EventInfo_NVM_E_WRITE_PROTECTED.GetEventFailed
        OIE_EventInfo_NVM_E_WRITE_PROTECTED_GetEventFreezeFrameData: start-on-event=GetEventFreezeFrameData, operation=EventInfo_NVM_E_WRITE_PROTECTED.GetEventFreezeFrameData
        OIE_EventInfo_NVM_E_WRITE_PROTECTED_GetEventStatus: start-on-event=GetEventStatus, operation=EventInfo_NVM_E_WRITE_PROTECTED.GetEventStatus
        OIE_EventInfo_NVM_E_WRITE_PROTECTED_GetEventTested: start-on-event=GetEventTested, operation=EventInfo_NVM_E_WRITE_PROTECTED.GetEventTested
        OIE_EventInfo_NVM_E_WRITE_PROTECTED_GetFaultDetectionCounter: start-on-event=GetFaultDetectionCounter, operation=EventInfo_NVM_E_WRITE_PROTECTED.GetFaultDetectionCounter
        OIE_EventInfo_NVM_E_WRONG_BLOCK_ID_GetDTCOfEvent: start-on-event=GetDTCOfEvent, operation=EventInfo_NVM_E_WRONG_BLOCK_ID.GetDTCOfEvent
        OIE_EventInfo_NVM_E_WRONG_BLOCK_ID_GetEventExtendedDataRecord: start-on-event=GetEventExtendedDataRecord, operation=EventInfo_NVM_E_WRONG_BLOCK_ID.GetEventExtendedDataRecord
        OIE_EventInfo_NVM_E_WRONG_BLOCK_ID_GetEventFailed: start-on-event=GetEventFailed, operation=EventInfo_NVM_E_WRONG_BLOCK_ID.GetEventFailed
        OIE_EventInfo_NVM_E_WRONG_BLOCK_ID_GetEventFreezeFrameData: start-on-event=GetEventFreezeFrameData, operation=EventInfo_NVM_E_WRONG_BLOCK_ID.GetEventFreezeFrameData
        OIE_EventInfo_NVM_E_WRONG_BLOCK_ID_GetEventStatus: start-on-event=GetEventStatus, operation=EventInfo_NVM_E_WRONG_BLOCK_ID.GetEventStatus
        OIE_EventInfo_NVM_E_WRONG_BLOCK_ID_GetEventTested: start-on-event=GetEventTested, operation=EventInfo_NVM_E_WRONG_BLOCK_ID.GetEventTested
        OIE_EventInfo_NVM_E_WRONG_BLOCK_ID_GetFaultDetectionCounter: start-on-event=GetFaultDetectionCounter, operation=EventInfo_NVM_E_WRONG_BLOCK_ID.GetFaultDetectionCounter
        OIE_EventInfo_PWM_E_UNEXPECTED_IRQ_GetDTCOfEvent: start-on-event=GetDTCOfEvent, operation=EventInfo_PWM_E_UNEXPECTED_IRQ.GetDTCOfEvent
        OIE_EventInfo_PWM_E_UNEXPECTED_IRQ_GetEventExtendedDataRecord: start-on-event=GetEventExtendedDataRecord, operation=EventInfo_PWM_E_UNEXPECTED_IRQ.GetEventExtendedDataRecord
        OIE_EventInfo_PWM_E_UNEXPECTED_IRQ_GetEventFailed: start-on-event=GetEventFailed, operation=EventInfo_PWM_E_UNEXPECTED_IRQ.GetEventFailed
        OIE_EventInfo_PWM_E_UNEXPECTED_IRQ_GetEventFreezeFrameData: start-on-event=GetEventFreezeFrameData, operation=EventInfo_PWM_E_UNEXPECTED_IRQ.GetEventFreezeFrameData
        OIE_EventInfo_PWM_E_UNEXPECTED_IRQ_GetEventStatus: start-on-event=GetEventStatus, operation=EventInfo_PWM_E_UNEXPECTED_IRQ.GetEventStatus
        OIE_EventInfo_PWM_E_UNEXPECTED_IRQ_GetEventTested: start-on-event=GetEventTested, operation=EventInfo_PWM_E_UNEXPECTED_IRQ.GetEventTested
        OIE_EventInfo_PWM_E_UNEXPECTED_IRQ_GetFaultDetectionCounter: start-on-event=GetFaultDetectionCounter, operation=EventInfo_PWM_E_UNEXPECTED_IRQ.GetFaultDetectionCounter
        OIE_EventInfo_RAMTST_E_RAM_FAILURE_GetDTCOfEvent: start-on-event=GetDTCOfEvent, operation=EventInfo_RAMTST_E_RAM_FAILURE.GetDTCOfEvent
        OIE_EventInfo_RAMTST_E_RAM_FAILURE_GetEventExtendedDataRecord: start-on-event=GetEventExtendedDataRecord, operation=EventInfo_RAMTST_E_RAM_FAILURE.GetEventExtendedDataRecord
        OIE_EventInfo_RAMTST_E_RAM_FAILURE_GetEventFailed: start-on-event=GetEventFailed, operation=EventInfo_RAMTST_E_RAM_FAILURE.GetEventFailed
        OIE_EventInfo_RAMTST_E_RAM_FAILURE_GetEventFreezeFrameData: start-on-event=GetEventFreezeFrameData, operation=EventInfo_RAMTST_E_RAM_FAILURE.GetEventFreezeFrameData
        OIE_EventInfo_RAMTST_E_RAM_FAILURE_GetEventStatus: start-on-event=GetEventStatus, operation=EventInfo_RAMTST_E_RAM_FAILURE.GetEventStatus
        OIE_EventInfo_RAMTST_E_RAM_FAILURE_GetEventTested: start-on-event=GetEventTested, operation=EventInfo_RAMTST_E_RAM_FAILURE.GetEventTested
        OIE_EventInfo_RAMTST_E_RAM_FAILURE_GetFaultDetectionCounter: start-on-event=GetFaultDetectionCounter, operation=EventInfo_RAMTST_E_RAM_FAILURE.GetFaultDetectionCounter
        OIE_EventInfo_REGMON_E_REG_FAILURE_GetDTCOfEvent: start-on-event=GetDTCOfEvent, operation=EventInfo_REGMON_E_REG_FAILURE.GetDTCOfEvent
        OIE_EventInfo_REGMON_E_REG_FAILURE_GetEventExtendedDataRecord: start-on-event=GetEventExtendedDataRecord, operation=EventInfo_REGMON_E_REG_FAILURE.GetEventExtendedDataRecord
        OIE_EventInfo_REGMON_E_REG_FAILURE_GetEventFailed: start-on-event=GetEventFailed, operation=EventInfo_REGMON_E_REG_FAILURE.GetEventFailed
        OIE_EventInfo_REGMON_E_REG_FAILURE_GetEventFreezeFrameData: start-on-event=GetEventFreezeFrameData, operation=EventInfo_REGMON_E_REG_FAILURE.GetEventFreezeFrameData
        OIE_EventInfo_REGMON_E_REG_FAILURE_GetEventStatus: start-on-event=GetEventStatus, operation=EventInfo_REGMON_E_REG_FAILURE.GetEventStatus
        OIE_EventInfo_REGMON_E_REG_FAILURE_GetEventTested: start-on-event=GetEventTested, operation=EventInfo_REGMON_E_REG_FAILURE.GetEventTested
        OIE_EventInfo_REGMON_E_REG_FAILURE_GetFaultDetectionCounter: start-on-event=GetFaultDetectionCounter, operation=EventInfo_REGMON_E_REG_FAILURE.GetFaultDetectionCounter
        OIE_EventInfo_SPI_E_TIMEOUT_GetDTCOfEvent: start-on-event=GetDTCOfEvent, operation=EventInfo_SPI_E_TIMEOUT.GetDTCOfEvent
        OIE_EventInfo_SPI_E_TIMEOUT_GetEventExtendedDataRecord: start-on-event=GetEventExtendedDataRecord, operation=EventInfo_SPI_E_TIMEOUT.GetEventExtendedDataRecord
        OIE_EventInfo_SPI_E_TIMEOUT_GetEventFailed: start-on-event=GetEventFailed, operation=EventInfo_SPI_E_TIMEOUT.GetEventFailed
        OIE_EventInfo_SPI_E_TIMEOUT_GetEventFreezeFrameData: start-on-event=GetEventFreezeFrameData, operation=EventInfo_SPI_E_TIMEOUT.GetEventFreezeFrameData
        OIE_EventInfo_SPI_E_TIMEOUT_GetEventStatus: start-on-event=GetEventStatus, operation=EventInfo_SPI_E_TIMEOUT.GetEventStatus
        OIE_EventInfo_SPI_E_TIMEOUT_GetEventTested: start-on-event=GetEventTested, operation=EventInfo_SPI_E_TIMEOUT.GetEventTested
        OIE_EventInfo_SPI_E_TIMEOUT_GetFaultDetectionCounter: start-on-event=GetFaultDetectionCounter, operation=EventInfo_SPI_E_TIMEOUT.GetFaultDetectionCounter
        OIE_EventInfo_WDGM_E_IMPROPER_CALLER_GetDTCOfEvent: start-on-event=GetDTCOfEvent, operation=EventInfo_WDGM_E_IMPROPER_CALLER.GetDTCOfEvent
        OIE_EventInfo_WDGM_E_IMPROPER_CALLER_GetEventExtendedDataRecord: start-on-event=GetEventExtendedDataRecord, operation=EventInfo_WDGM_E_IMPROPER_CALLER.GetEventExtendedDataRecord
        OIE_EventInfo_WDGM_E_IMPROPER_CALLER_GetEventFailed: start-on-event=GetEventFailed, operation=EventInfo_WDGM_E_IMPROPER_CALLER.GetEventFailed
        OIE_EventInfo_WDGM_E_IMPROPER_CALLER_GetEventFreezeFrameData: start-on-event=GetEventFreezeFrameData, operation=EventInfo_WDGM_E_IMPROPER_CALLER.GetEventFreezeFrameData
        OIE_EventInfo_WDGM_E_IMPROPER_CALLER_GetEventStatus: start-on-event=GetEventStatus, operation=EventInfo_WDGM_E_IMPROPER_CALLER.GetEventStatus
        OIE_EventInfo_WDGM_E_IMPROPER_CALLER_GetEventTested: start-on-event=GetEventTested, operation=EventInfo_WDGM_E_IMPROPER_CALLER.GetEventTested
        OIE_EventInfo_WDGM_E_IMPROPER_CALLER_GetFaultDetectionCounter: start-on-event=GetFaultDetectionCounter, operation=EventInfo_WDGM_E_IMPROPER_CALLER.GetFaultDetectionCounter
        OIE_EventInfo_WDGM_E_MONITORING_GetDTCOfEvent: start-on-event=GetDTCOfEvent, operation=EventInfo_WDGM_E_MONITORING.GetDTCOfEvent
        OIE_EventInfo_WDGM_E_MONITORING_GetEventExtendedDataRecord: start-on-event=GetEventExtendedDataRecord, operation=EventInfo_WDGM_E_MONITORING.GetEventExtendedDataRecord
        OIE_EventInfo_WDGM_E_MONITORING_GetEventFailed: start-on-event=GetEventFailed, operation=EventInfo_WDGM_E_MONITORING.GetEventFailed
        OIE_EventInfo_WDGM_E_MONITORING_GetEventFreezeFrameData: start-on-event=GetEventFreezeFrameData, operation=EventInfo_WDGM_E_MONITORING.GetEventFreezeFrameData
        OIE_EventInfo_WDGM_E_MONITORING_GetEventStatus: start-on-event=GetEventStatus, operation=EventInfo_WDGM_E_MONITORING.GetEventStatus
        OIE_EventInfo_WDGM_E_MONITORING_GetEventTested: start-on-event=GetEventTested, operation=EventInfo_WDGM_E_MONITORING.GetEventTested
        OIE_EventInfo_WDGM_E_MONITORING_GetFaultDetectionCounter: start-on-event=GetFaultDetectionCounter, operation=EventInfo_WDGM_E_MONITORING.GetFaultDetectionCounter
        OIE_EventInfo_WDGM_E_SET_MODE_GetDTCOfEvent: start-on-event=GetDTCOfEvent, operation=EventInfo_WDGM_E_SET_MODE.GetDTCOfEvent
        OIE_EventInfo_WDGM_E_SET_MODE_GetEventExtendedDataRecord: start-on-event=GetEventExtendedDataRecord, operation=EventInfo_WDGM_E_SET_MODE.GetEventExtendedDataRecord
        OIE_EventInfo_WDGM_E_SET_MODE_GetEventFailed: start-on-event=GetEventFailed, operation=EventInfo_WDGM_E_SET_MODE.GetEventFailed
        OIE_EventInfo_WDGM_E_SET_MODE_GetEventFreezeFrameData: start-on-event=GetEventFreezeFrameData, operation=EventInfo_WDGM_E_SET_MODE.GetEventFreezeFrameData
        OIE_EventInfo_WDGM_E_SET_MODE_GetEventStatus: start-on-event=GetEventStatus, operation=EventInfo_WDGM_E_SET_MODE.GetEventStatus
        OIE_EventInfo_WDGM_E_SET_MODE_GetEventTested: start-on-event=GetEventTested, operation=EventInfo_WDGM_E_SET_MODE.GetEventTested
        OIE_EventInfo_WDGM_E_SET_MODE_GetFaultDetectionCounter: start-on-event=GetFaultDetectionCounter, operation=EventInfo_WDGM_E_SET_MODE.GetFaultDetectionCounter
        OIE_EventInfo_WDG_76_ACW_E_DISABLE_REJECTED_GetDTCOfEvent: start-on-event=GetDTCOfEvent, operation=EventInfo_WDG_76_ACW_E_DISABLE_REJECTED.GetDTCOfEvent
        OIE_EventInfo_WDG_76_ACW_E_DISABLE_REJECTED_GetEventExtendedDataRecord: start-on-event=GetEventExtendedDataRecord, operation=EventInfo_WDG_76_ACW_E_DISABLE_REJECTED.GetEventExtendedDataRecord
        OIE_EventInfo_WDG_76_ACW_E_DISABLE_REJECTED_GetEventFailed: start-on-event=GetEventFailed, operation=EventInfo_WDG_76_ACW_E_DISABLE_REJECTED.GetEventFailed
        OIE_EventInfo_WDG_76_ACW_E_DISABLE_REJECTED_GetEventFreezeFrameData: start-on-event=GetEventFreezeFrameData, operation=EventInfo_WDG_76_ACW_E_DISABLE_REJECTED.GetEventFreezeFrameData
        OIE_EventInfo_WDG_76_ACW_E_DISABLE_REJECTED_GetEventStatus: start-on-event=GetEventStatus, operation=EventInfo_WDG_76_ACW_E_DISABLE_REJECTED.GetEventStatus
        OIE_EventInfo_WDG_76_ACW_E_DISABLE_REJECTED_GetEventTested: start-on-event=GetEventTested, operation=EventInfo_WDG_76_ACW_E_DISABLE_REJECTED.GetEventTested
        OIE_EventInfo_WDG_76_ACW_E_DISABLE_REJECTED_GetFaultDetectionCounter: start-on-event=GetFaultDetectionCounter, operation=EventInfo_WDG_76_ACW_E_DISABLE_REJECTED.GetFaultDetectionCounter
        OIE_EventInfo_WDG_76_ACW_E_MODE_FAILED_GetDTCOfEvent: start-on-event=GetDTCOfEvent, operation=EventInfo_WDG_76_ACW_E_MODE_FAILED.GetDTCOfEvent
        OIE_EventInfo_WDG_76_ACW_E_MODE_FAILED_GetEventExtendedDataRecord: start-on-event=GetEventExtendedDataRecord, operation=EventInfo_WDG_76_ACW_E_MODE_FAILED.GetEventExtendedDataRecord
        OIE_EventInfo_WDG_76_ACW_E_MODE_FAILED_GetEventFailed: start-on-event=GetEventFailed, operation=EventInfo_WDG_76_ACW_E_MODE_FAILED.GetEventFailed
        OIE_EventInfo_WDG_76_ACW_E_MODE_FAILED_GetEventFreezeFrameData: start-on-event=GetEventFreezeFrameData, operation=EventInfo_WDG_76_ACW_E_MODE_FAILED.GetEventFreezeFrameData
        OIE_EventInfo_WDG_76_ACW_E_MODE_FAILED_GetEventStatus: start-on-event=GetEventStatus, operation=EventInfo_WDG_76_ACW_E_MODE_FAILED.GetEventStatus
        OIE_EventInfo_WDG_76_ACW_E_MODE_FAILED_GetEventTested: start-on-event=GetEventTested, operation=EventInfo_WDG_76_ACW_E_MODE_FAILED.GetEventTested
        OIE_EventInfo_WDG_76_ACW_E_MODE_FAILED_GetFaultDetectionCounter: start-on-event=GetFaultDetectionCounter, operation=EventInfo_WDG_76_ACW_E_MODE_FAILED.GetFaultDetectionCounter
        OIE_EventInfo_WDG_E_DISABLE_REJECTED_GetDTCOfEvent: start-on-event=GetDTCOfEvent, operation=EventInfo_WDG_E_DISABLE_REJECTED.GetDTCOfEvent
        OIE_EventInfo_WDG_E_DISABLE_REJECTED_GetEventExtendedDataRecord: start-on-event=GetEventExtendedDataRecord, operation=EventInfo_WDG_E_DISABLE_REJECTED.GetEventExtendedDataRecord
        OIE_EventInfo_WDG_E_DISABLE_REJECTED_GetEventFailed: start-on-event=GetEventFailed, operation=EventInfo_WDG_E_DISABLE_REJECTED.GetEventFailed
        OIE_EventInfo_WDG_E_DISABLE_REJECTED_GetEventFreezeFrameData: start-on-event=GetEventFreezeFrameData, operation=EventInfo_WDG_E_DISABLE_REJECTED.GetEventFreezeFrameData
        OIE_EventInfo_WDG_E_DISABLE_REJECTED_GetEventStatus: start-on-event=GetEventStatus, operation=EventInfo_WDG_E_DISABLE_REJECTED.GetEventStatus
        OIE_EventInfo_WDG_E_DISABLE_REJECTED_GetEventTested: start-on-event=GetEventTested, operation=EventInfo_WDG_E_DISABLE_REJECTED.GetEventTested
        OIE_EventInfo_WDG_E_DISABLE_REJECTED_GetFaultDetectionCounter: start-on-event=GetFaultDetectionCounter, operation=EventInfo_WDG_E_DISABLE_REJECTED.GetFaultDetectionCounter
        OIE_EventInfo_WDG_E_MISS_TRIGGER_GetDTCOfEvent: start-on-event=GetDTCOfEvent, operation=EventInfo_WDG_E_MISS_TRIGGER.GetDTCOfEvent
        OIE_EventInfo_WDG_E_MISS_TRIGGER_GetEventExtendedDataRecord: start-on-event=GetEventExtendedDataRecord, operation=EventInfo_WDG_E_MISS_TRIGGER.GetEventExtendedDataRecord
        OIE_EventInfo_WDG_E_MISS_TRIGGER_GetEventFailed: start-on-event=GetEventFailed, operation=EventInfo_WDG_E_MISS_TRIGGER.GetEventFailed
        OIE_EventInfo_WDG_E_MISS_TRIGGER_GetEventFreezeFrameData: start-on-event=GetEventFreezeFrameData, operation=EventInfo_WDG_E_MISS_TRIGGER.GetEventFreezeFrameData
        OIE_EventInfo_WDG_E_MISS_TRIGGER_GetEventStatus: start-on-event=GetEventStatus, operation=EventInfo_WDG_E_MISS_TRIGGER.GetEventStatus
        OIE_EventInfo_WDG_E_MISS_TRIGGER_GetEventTested: start-on-event=GetEventTested, operation=EventInfo_WDG_E_MISS_TRIGGER.GetEventTested
        OIE_EventInfo_WDG_E_MISS_TRIGGER_GetFaultDetectionCounter: start-on-event=GetFaultDetectionCounter, operation=EventInfo_WDG_E_MISS_TRIGGER.GetFaultDetectionCounter
        OIE_EventInfo_WDG_E_MODE_FAILED_GetDTCOfEvent: start-on-event=GetDTCOfEvent, operation=EventInfo_WDG_E_MODE_FAILED.GetDTCOfEvent
        OIE_EventInfo_WDG_E_MODE_FAILED_GetEventExtendedDataRecord: start-on-event=GetEventExtendedDataRecord, operation=EventInfo_WDG_E_MODE_FAILED.GetEventExtendedDataRecord
        OIE_EventInfo_WDG_E_MODE_FAILED_GetEventFailed: start-on-event=GetEventFailed, operation=EventInfo_WDG_E_MODE_FAILED.GetEventFailed
        OIE_EventInfo_WDG_E_MODE_FAILED_GetEventFreezeFrameData: start-on-event=GetEventFreezeFrameData, operation=EventInfo_WDG_E_MODE_FAILED.GetEventFreezeFrameData
        OIE_EventInfo_WDG_E_MODE_FAILED_GetEventStatus: start-on-event=GetEventStatus, operation=EventInfo_WDG_E_MODE_FAILED.GetEventStatus
        OIE_EventInfo_WDG_E_MODE_FAILED_GetEventTested: start-on-event=GetEventTested, operation=EventInfo_WDG_E_MODE_FAILED.GetEventTested
        OIE_EventInfo_WDG_E_MODE_FAILED_GetFaultDetectionCounter: start-on-event=GetFaultDetectionCounter, operation=EventInfo_WDG_E_MODE_FAILED.GetFaultDetectionCounter
        OIE_Event_DEM_E_TEST_EVENT1_ResetEventStatus: start-on-event=ResetEventStatus, operation=Event_DEM_E_TEST_EVENT1.ResetEventStatus
        OIE_Event_DEM_E_TEST_EVENT1_SetEventDisabled: start-on-event=SetEventDisabled, operation=Event_DEM_E_TEST_EVENT1.SetEventDisabled
        OIE_Event_DEM_E_TEST_EVENT1_SetEventStatus: start-on-event=SetEventStatus, operation=Event_DEM_E_TEST_EVENT1.SetEventStatus
        OIE_Event_DEM_E_TEST_EVENT2_ResetEventStatus: start-on-event=ResetEventStatus, operation=Event_DEM_E_TEST_EVENT2.ResetEventStatus
        OIE_Event_DEM_E_TEST_EVENT2_SetEventDisabled: start-on-event=SetEventDisabled, operation=Event_DEM_E_TEST_EVENT2.SetEventDisabled
        OIE_Event_DEM_E_TEST_EVENT2_SetEventStatus: start-on-event=SetEventStatus, operation=Event_DEM_E_TEST_EVENT2.SetEventStatus
        OIE_Event_DEM_E_TEST_EVENT3_ResetEventStatus: start-on-event=ResetEventStatus, operation=Event_DEM_E_TEST_EVENT3.ResetEventStatus
        OIE_Event_DEM_E_TEST_EVENT3_SetEventDisabled: start-on-event=SetEventDisabled, operation=Event_DEM_E_TEST_EVENT3.SetEventDisabled
        OIE_Event_DEM_E_TEST_EVENT3_SetEventStatus: start-on-event=SetEventStatus, operation=Event_DEM_E_TEST_EVENT3.SetEventStatus
        OIE_Event_DEM_E_TEST_EVENT4_ResetEventStatus: start-on-event=ResetEventStatus, operation=Event_DEM_E_TEST_EVENT4.ResetEventStatus
        OIE_Event_DEM_E_TEST_EVENT4_SetEventDisabled: start-on-event=SetEventDisabled, operation=Event_DEM_E_TEST_EVENT4.SetEventDisabled
        OIE_Event_DEM_E_TEST_EVENT4_SetEventStatus: start-on-event=SetEventStatus, operation=Event_DEM_E_TEST_EVENT4.SetEventStatus
        OIE_Event_DEM_E_TEST_EVENT5_ResetEventStatus: start-on-event=ResetEventStatus, operation=Event_DEM_E_TEST_EVENT5.ResetEventStatus
        OIE_Event_DEM_E_TEST_EVENT5_SetEventDisabled: start-on-event=SetEventDisabled, operation=Event_DEM_E_TEST_EVENT5.SetEventDisabled
        OIE_Event_DEM_E_TEST_EVENT5_SetEventStatus: start-on-event=SetEventStatus, operation=Event_DEM_E_TEST_EVENT5.SetEventStatus
        OIE_Event_DEM_E_TEST_EVENT6_ResetEventStatus: start-on-event=ResetEventStatus, operation=Event_DEM_E_TEST_EVENT6.ResetEventStatus
        OIE_Event_DEM_E_TEST_EVENT6_SetEventDisabled: start-on-event=SetEventDisabled, operation=Event_DEM_E_TEST_EVENT6.SetEventDisabled
        OIE_Event_DEM_E_TEST_EVENT6_SetEventStatus: start-on-event=SetEventStatus, operation=Event_DEM_E_TEST_EVENT6.SetEventStatus
        OIE_GeneralEvtInfo_GetDTCOfEvent: start-on-event=GetDTCOfEvent, operation=GeneralEvtInfo.GetDTCOfEvent
        OIE_GeneralEvtInfo_GetEventExtendedDataRecord: start-on-event=GetEventExtendedDataRecord, operation=GeneralEvtInfo.GetEventExtendedDataRecord
        OIE_GeneralEvtInfo_GetEventFailed: start-on-event=GetEventFailed, operation=GeneralEvtInfo.GetEventFailed
        OIE_GeneralEvtInfo_GetEventFreezeFrameData: start-on-event=GetEventFreezeFrameData, operation=GeneralEvtInfo.GetEventFreezeFrameData
        OIE_GeneralEvtInfo_GetEventStatus: start-on-event=GetEventStatus, operation=GeneralEvtInfo.GetEventStatus
        OIE_GeneralEvtInfo_GetEventTested: start-on-event=GetEventTested, operation=GeneralEvtInfo.GetEventTested
        OIE_GeneralEvtInfo_GetFaultDetectionCounter: start-on-event=GetFaultDetectionCounter, operation=GeneralEvtInfo.GetFaultDetectionCounter
        OIE_IndStatus_DemIndicator_0_GetIndicatorStatus: start-on-event=GetIndicatorStatus, operation=IndStatus_DemIndicator_0.GetIndicatorStatus
        OIE_IndStatus_DemIndicator_1_GetIndicatorStatus: start-on-event=GetIndicatorStatus, operation=IndStatus_DemIndicator_1.GetIndicatorStatus
        OIE_OpCycle_DemOperationCycle0_SetOperationCycleState: start-on-event=SetOperationCycleState, operation=OpCycle_DemOperationCycle0.SetOperationCycleState
        OIE_OverflowIndPrimaryMemory_GetEventMemoryOverflow: start-on-event=GetEventMemoryOverflow, operation=OverflowIndPrimaryMemory.GetEventMemoryOverflow
      port-api-options:
        {enable-take-address=false, indirect-api=false, port-defined-argument-value{value=0, value-type=uint8}, port=EnableCond_DemEnableCondition}
        {enable-take-address=false, indirect-api=false, port-defined-argument-value{value=1, value-type=Dem_EventIdType}, port=EventInfo_ADC_E_TIMEOUT}
        {enable-take-address=false, indirect-api=false, port-defined-argument-value{value=62, value-type=Dem_EventIdType}, port=EventInfo_CANCM_E_BAT_FAIL}
        {enable-take-address=false, indirect-api=false, port-defined-argument-value{value=53, value-type=Dem_EventIdType}, port=EventInfo_CANSM_E_BUS_OFF}
        {enable-take-address=false, indirect-api=false, port-defined-argument-value{value=68, value-type=Dem_EventIdType}, port=EventInfo_CANSM_E_MODE_CHANGE_PROJECT}
        {enable-take-address=false, indirect-api=false, port-defined-argument-value{value=21, value-type=Dem_EventIdType}, port=EventInfo_DEM_E_TEST_EVENT1}
        {enable-take-address=false, indirect-api=false, port-defined-argument-value{value=45, value-type=Dem_EventIdType}, port=EventInfo_DEM_E_TEST_EVENT2}
        {enable-take-address=false, indirect-api=false, port-defined-argument-value{value=46, value-type=Dem_EventIdType}, port=EventInfo_DEM_E_TEST_EVENT3}
        {enable-take-address=false, indirect-api=false, port-defined-argument-value{value=47, value-type=Dem_EventIdType}, port=EventInfo_DEM_E_TEST_EVENT4}
        {enable-take-address=false, indirect-api=false, port-defined-argument-value{value=54, value-type=Dem_EventIdType}, port=EventInfo_DEM_E_TEST_EVENT5}
        {enable-take-address=false, indirect-api=false, port-defined-argument-value{value=55, value-type=Dem_EventIdType}, port=EventInfo_DEM_E_TEST_EVENT6}
        {enable-take-address=false, indirect-api=false, port-defined-argument-value{value=36, value-type=Dem_EventIdType}, port=EventInfo_Dem_FEE_GC_ERASE_ERROR}
        {enable-take-address=false, indirect-api=false, port-defined-argument-value{value=30, value-type=Dem_EventIdType}, port=EventInfo_Dem_FEE_GC_INIT_ERROR}
        {enable-take-address=false, indirect-api=false, port-defined-argument-value{value=35, value-type=Dem_EventIdType}, port=EventInfo_Dem_FEE_GC_READ_ERROR}
        {enable-take-address=false, indirect-api=false, port-defined-argument-value{value=31, value-type=Dem_EventIdType}, port=EventInfo_Dem_FEE_GC_TRIG_ERROR}
        {enable-take-address=false, indirect-api=false, port-defined-argument-value{value=34, value-type=Dem_EventIdType}, port=EventInfo_Dem_FEE_GC_WRITE_ERROR}
        {enable-take-address=false, indirect-api=false, port-defined-argument-value{value=37, value-type=Dem_EventIdType}, port=EventInfo_Dem_FEE_INVALIDATE_ERROR}
        {enable-take-address=false, indirect-api=false, port-defined-argument-value{value=33, value-type=Dem_EventIdType}, port=EventInfo_Dem_FEE_READ_ERROR}
        {enable-take-address=false, indirect-api=false, port-defined-argument-value{value=29, value-type=Dem_EventIdType}, port=EventInfo_Dem_FEE_UNCONFIG_BLK_EXCEEDED_ERROR}
        {enable-take-address=false, indirect-api=false, port-defined-argument-value{value=32, value-type=Dem_EventIdType}, port=EventInfo_Dem_FEE_WRITE_ERROR}
        {enable-take-address=false, indirect-api=false, port-defined-argument-value{value=22, value-type=Dem_EventIdType}, port=EventInfo_Dem_FLS_COMPARE_ERROR}
        {enable-take-address=false, indirect-api=false, port-defined-argument-value{value=23, value-type=Dem_EventIdType}, port=EventInfo_Dem_FLS_ERASE_ERROR}
        {enable-take-address=false, indirect-api=false, port-defined-argument-value{value=24, value-type=Dem_EventIdType}, port=EventInfo_Dem_FLS_READ_ERROR}
        {enable-take-address=false, indirect-api=false, port-defined-argument-value{value=25, value-type=Dem_EventIdType}, port=EventInfo_Dem_FLS_WRITE_ERROR}
        {enable-take-address=false, indirect-api=false, port-defined-argument-value{value=19, value-type=Dem_EventIdType}, port=EventInfo_ECUM_E_CONFIGURATION_DATA_INCONSISTENT}
        {enable-take-address=false, indirect-api=false, port-defined-argument-value{value=48, value-type=Dem_EventIdType}, port=EventInfo_ECUM_E_IMPROPER_CALLER}
        {enable-take-address=false, indirect-api=false, port-defined-argument-value{value=20, value-type=Dem_EventIdType}, port=EventInfo_ECUM_E_RAM_CHECK_FAILED}
        {enable-take-address=false, indirect-api=false, port-defined-argument-value{value=49, value-type=Dem_EventIdType}, port=EventInfo_EEP_E_COMPARE_FAILED}
        {enable-take-address=false, indirect-api=false, port-defined-argument-value{value=50, value-type=Dem_EventIdType}, port=EventInfo_EEP_E_ERASE_FAILED}
        {enable-take-address=false, indirect-api=false, port-defined-argument-value{value=51, value-type=Dem_EventIdType}, port=EventInfo_EEP_E_READ_FAILED}
        {enable-take-address=false, indirect-api=false, port-defined-argument-value{value=52, value-type=Dem_EventIdType}, port=EventInfo_EEP_E_WRITE_FAILED}
        {enable-take-address=false, indirect-api=false, port-defined-argument-value{value=65, value-type=Dem_EventIdType}, port=EventInfo_ETHSM_E_LINK_DOWN}
        {enable-take-address=false, indirect-api=false, port-defined-argument-value{value=64, value-type=Dem_EventIdType}, port=EventInfo_ETHTRCV_E_ACCESS}
        {enable-take-address=false, indirect-api=false, port-defined-argument-value{value=2, value-type=Dem_EventIdType}, port=EventInfo_ETH_E_ACCESS}
        {enable-take-address=false, indirect-api=false, port-defined-argument-value{value=6, value-type=Dem_EventIdType}, port=EventInfo_FLS_E_COMPARE_FAILED}
        {enable-take-address=false, indirect-api=false, port-defined-argument-value{value=4, value-type=Dem_EventIdType}, port=EventInfo_FLS_E_ERASE_FAILED}
        {enable-take-address=false, indirect-api=false, port-defined-argument-value{value=5, value-type=Dem_EventIdType}, port=EventInfo_FLS_E_READ_FAILED}
        {enable-take-address=false, indirect-api=false, port-defined-argument-value{value=7, value-type=Dem_EventIdType}, port=EventInfo_FLS_E_UNEXPECTED_FLASH_ID}
        {enable-take-address=false, indirect-api=false, port-defined-argument-value{value=3, value-type=Dem_EventIdType}, port=EventInfo_FLS_E_WRITE_FAILED}
        {enable-take-address=false, indirect-api=false, port-defined-argument-value{value=8, value-type=Dem_EventIdType}, port=EventInfo_FR_E_ACCESS}
        {enable-take-address=false, indirect-api=false, port-defined-argument-value{value=60, value-type=Dem_EventIdType}, port=EventInfo_IOHWAB_E_BUSY}
        {enable-take-address=false, indirect-api=false, port-defined-argument-value{value=61, value-type=Dem_EventIdType}, port=EventInfo_IOHWAB_E_PROC_FAIL}
        {enable-take-address=false, indirect-api=false, port-defined-argument-value{value=59, value-type=Dem_EventIdType}, port=EventInfo_IOHWAB_E_SETUP_FAIL}
        {enable-take-address=false, indirect-api=false, port-defined-argument-value{value=58, value-type=Dem_EventIdType}, port=EventInfo_IOHWAB_E_WRONG_PARAM}
        {enable-take-address=false, indirect-api=false, port-defined-argument-value{value=57, value-type=Dem_EventIdType}, port=EventInfo_IOHWAB_E_WRONG_SETTING}
        {enable-take-address=false, indirect-api=false, port-defined-argument-value{value=56, value-type=Dem_EventIdType}, port=EventInfo_IOHWAB_E_WRONG_STATE}
        {enable-take-address=false, indirect-api=false, port-defined-argument-value{value=9, value-type=Dem_EventIdType}, port=EventInfo_LIN_E_TIMEOUT}
        {enable-take-address=false, indirect-api=false, port-defined-argument-value{value=10, value-type=Dem_EventIdType}, port=EventInfo_MCU_E_CLOCK_FAILURE}
        {enable-take-address=false, indirect-api=false, port-defined-argument-value{value=11, value-type=Dem_EventIdType}, port=EventInfo_MCU_E_LOCK_FAILURE}
        {enable-take-address=false, indirect-api=false, port-defined-argument-value{value=12, value-type=Dem_EventIdType}, port=EventInfo_MCU_E_QUARTZ_FAILURE}
        {enable-take-address=false, indirect-api=false, port-defined-argument-value{value=13, value-type=Dem_EventIdType}, port=EventInfo_MCU_E_TIMEOUT_TRANSITION}
        {enable-take-address=false, indirect-api=false, port-defined-argument-value{value=38, value-type=Dem_EventIdType}, port=EventInfo_NVM_E_INTEGRITY_FAILED}
        {enable-take-address=false, indirect-api=false, port-defined-argument-value{value=39, value-type=Dem_EventIdType}, port=EventInfo_NVM_E_LOSS_OF_REDUNDANCY}
        {enable-take-address=false, indirect-api=false, port-defined-argument-value{value=40, value-type=Dem_EventIdType}, port=EventInfo_NVM_E_QUEUE_OVERFLOW}
        {enable-take-address=false, indirect-api=false, port-defined-argument-value{value=41, value-type=Dem_EventIdType}, port=EventInfo_NVM_E_REQ_FAILED}
        {enable-take-address=false, indirect-api=false, port-defined-argument-value{value=42, value-type=Dem_EventIdType}, port=EventInfo_NVM_E_VERIFY_FAILED}
        {enable-take-address=false, indirect-api=false, port-defined-argument-value{value=43, value-type=Dem_EventIdType}, port=EventInfo_NVM_E_WRITE_PROTECTED}
        {enable-take-address=false, indirect-api=false, port-defined-argument-value{value=44, value-type=Dem_EventIdType}, port=EventInfo_NVM_E_WRONG_BLOCK_ID}
        {enable-take-address=false, indirect-api=false, port-defined-argument-value{value=14, value-type=Dem_EventIdType}, port=EventInfo_PWM_E_UNEXPECTED_IRQ}
        {enable-take-address=false, indirect-api=false, port-defined-argument-value{value=63, value-type=Dem_EventIdType}, port=EventInfo_RAMTST_E_RAM_FAILURE}
        {enable-take-address=false, indirect-api=false, port-defined-argument-value{value=69, value-type=Dem_EventIdType}, port=EventInfo_REGMON_E_REG_FAILURE}
        {enable-take-address=false, indirect-api=false, port-defined-argument-value{value=15, value-type=Dem_EventIdType}, port=EventInfo_SPI_E_TIMEOUT}
        {enable-take-address=false, indirect-api=false, port-defined-argument-value{value=26, value-type=Dem_EventIdType}, port=EventInfo_WDGM_E_IMPROPER_CALLER}
        {enable-take-address=false, indirect-api=false, port-defined-argument-value{value=27, value-type=Dem_EventIdType}, port=EventInfo_WDGM_E_MONITORING}
        {enable-take-address=false, indirect-api=false, port-defined-argument-value{value=28, value-type=Dem_EventIdType}, port=EventInfo_WDGM_E_SET_MODE}
        {enable-take-address=false, indirect-api=false, port-defined-argument-value{value=66, value-type=Dem_EventIdType}, port=EventInfo_WDG_76_ACW_E_DISABLE_REJECTED}
        {enable-take-address=false, indirect-api=false, port-defined-argument-value{value=67, value-type=Dem_EventIdType}, port=EventInfo_WDG_76_ACW_E_MODE_FAILED}
        {enable-take-address=false, indirect-api=false, port-defined-argument-value{value=17, value-type=Dem_EventIdType}, port=EventInfo_WDG_E_DISABLE_REJECTED}
        {enable-take-address=false, indirect-api=false, port-defined-argument-value{value=18, value-type=Dem_EventIdType}, port=EventInfo_WDG_E_MISS_TRIGGER}
        {enable-take-address=false, indirect-api=false, port-defined-argument-value{value=16, value-type=Dem_EventIdType}, port=EventInfo_WDG_E_MODE_FAILED}
        {enable-take-address=false, indirect-api=false, port-defined-argument-value{value=21, value-type=Dem_EventIdType}, port=Event_DEM_E_TEST_EVENT1}
        {enable-take-address=false, indirect-api=false, port-defined-argument-value{value=45, value-type=Dem_EventIdType}, port=Event_DEM_E_TEST_EVENT2}
        {enable-take-address=false, indirect-api=false, port-defined-argument-value{value=46, value-type=Dem_EventIdType}, port=Event_DEM_E_TEST_EVENT3}
        {enable-take-address=false, indirect-api=false, port-defined-argument-value{value=47, value-type=Dem_EventIdType}, port=Event_DEM_E_TEST_EVENT4}
        {enable-take-address=false, indirect-api=false, port-defined-argument-value{value=54, value-type=Dem_EventIdType}, port=Event_DEM_E_TEST_EVENT5}
        {enable-take-address=false, indirect-api=false, port-defined-argument-value{value=55, value-type=Dem_EventIdType}, port=Event_DEM_E_TEST_EVENT6}
        {enable-take-address=false, indirect-api=false, port-defined-argument-value{value=0, value-type=uint8}, port=IndStatus_DemIndicator_0}
        {enable-take-address=false, indirect-api=false, port-defined-argument-value{value=1, value-type=uint8}, port=IndStatus_DemIndicator_1}
        {enable-take-address=false, indirect-api=false, port-defined-argument-value{value=0, value-type=uint8}, port=OpCycle_DemOperationCycle0}
        {enable-take-address=false, indirect-api=false, port-defined-argument-value{value=1, value-type=Dem_DTCOriginType}, port=OverflowIndPrimaryMemory}
      16 x runnable:
        ClearDTC: can-be-invoked-concurrently=true, symbol=Dem_CddClearDTC, arguments=[symbol=DTC, symbol=DTCFormat, symbol=DTCOrigin]
        SetEnableCondition: can-be-invoked-concurrently=true, symbol=Dem_SetEnableCondition, arguments=[symbol=EnableConditionID, symbol=ConditionFulfilled]
        GetDTCOfEvent: can-be-invoked-concurrently=true, symbol=Dem_GetDTCOfEvent, arguments=[symbol=EventId, symbol=DTCFormat, symbol=DTCOfEvent]
        GetEventExtendedDataRecord: can-be-invoked-concurrently=true, symbol=Dem_GetEventExtendedDataRecord, arguments=[symbol=EventId, symbol=RecordNumber, symbol=DestBuffer]
        GetEventFailed: can-be-invoked-concurrently=true, symbol=Dem_GetEventFailed, arguments=[symbol=EventId, symbol=EventFailed]
        GetEventFreezeFrameData: can-be-invoked-concurrently=true, symbol=Dem_GetEventFreezeFrameData, arguments=[symbol=EventId, symbol=RecordNumber, symbol=ReportTotalRecord, symbol=DataId, symbol=DestBuffer]
        GetEventStatus: can-be-invoked-concurrently=true, symbol=Dem_GetEventStatus, arguments=[symbol=EventId, symbol=EventStatusExtended]
        GetEventTested: can-be-invoked-concurrently=true, symbol=Dem_GetEventTested, arguments=[symbol=EventId, symbol=EventTested]
        GetFaultDetectionCounter: can-be-invoked-concurrently=true, symbol=Dem_GetFaultDetectionCounter, arguments=[symbol=EventId, symbol=FaultDetectionCounter]
        ResetEventStatus: can-be-invoked-concurrently=true, symbol=Dem_ResetEventStatus, runnable-entity-argument=symbol=EventId
        SetEventDisabled: can-be-invoked-concurrently=true, symbol=Dem_SetEventDisabled, runnable-entity-argument=symbol=EventId
        SetEventStatus: can-be-invoked-concurrently=true, symbol=Dem_SetEventStatus, arguments=[symbol=EventId, symbol=EventStatus]
        GetIndicatorStatus: can-be-invoked-concurrently=true, symbol=Dem_GetIndicatorStatus, arguments=[symbol=IndicatorId, symbol=IndicatorStatus]
        SetOperationCycleState: can-be-invoked-concurrently=true, symbol=Dem_SetOperationCycleState, arguments=[symbol=OperationCycleId, symbol=CycleState]
        GetEventMemoryOverflow: can-be-invoked-concurrently=true, symbol=Dem_GetEventMemoryOverflow, arguments=[symbol=DTCOrigin, symbol=OverflowIndication]
        MainFunction: symbol=Dem_MainFunction
          7 x sync call, all with timeout=0:
            SSCP_CBInitEvt_DEM_E_TEST_EVENT1: operation=CBInitEvt_DEM_E_TEST_EVENT1.InitMonitorForEvent
            SSCP_CBReadData_DE_0001: operation=CBReadData_DE_0001.ReadData
            SSCP_CBReadData_DE_0002: operation=CBReadData_DE_0002.ReadData
            SSCP_CBStatusEvt_CANSM_E_MODE_CHANGE_PROJECT_DemCallbackEventStatusChanged0: operation=CBStatusEvt_CANSM_E_MODE_CHANGE_PROJECT_DemCallbackEventStatusChanged0.EventStatusChanged
            SSCP_CBStatusEvt_DEM_E_TEST_EVENT1_DemCallbackEventStatusChanged0: operation=CBStatusEvt_DEM_E_TEST_EVENT1_DemCallbackEventStatusChanged0.EventStatusChanged
            SSCP_GeneralCBDataEvt: operation=GeneralCBDataEvt.EventDataChanged
            SSCP_GeneralCBStatusEvt: operation=GeneralCBStatusEvt.EventStatusChanged
  swc implementation Dem_SwcImplementation: programming-language=C, sw-version=1.0.0.0, swc-bsw-mapping=SwcBswMapping_Dem, vendor-id=0, behavior=DemInternalBehavior
    code-descriptors:
      code CodeDescriptor: artifact-descriptors=autosar-engineering-object={short-label=Dem_LibObjects, category=SWLIB, domain=AUTOSAR_DEM}
    resource consumption ResourceConsumption
      memory section MemorySection_PrimaryEventMemoryEntry: size=18, symbol=Dem_PrimaryEventMemory
      memory section MemorySection_NonVolatileData: size=9, symbol=Dem_NonVolatileData
      memory section MemorySection_EventStatusNvRamBlock: size=50, symbol=Dem_EventStatusNvRamData
  swc bsw mapping SwcBswMapping_Dem: bsw-behavior=BswInternalBehaviors_Dem, swc-bsw-runnable-mapping{bsw-entity=BswSE_Dem_MainFunction, swc-runnable=MainFunction}, swc-behavior=DemInternalBehavior
